VERSION ""

NS_ :

BS_:

BU_: BMS

VAL_TABLE_ Rolling_Counter_0x2A1 15 "Invalid";
VAL_TABLE_ ODS_Status 3 "Reserved" 2 "ODS disconnected" 1 "Seat Occupied" 0 "Seat Not Occupied";
VAL_TABLE_ EVCC_MHU_CharSchSetFeedBack 3 "invalid " 2 "No Schedule" 1 "Schedule Success" 0 "No action";
VAL_TABLE_ EVCC_ChargeGunSts 1 "Plug In" 0 "no Plug in";
VAL_TABLE_ EVCC_ChargeMode 2 "DC Mode " 1 "AC Mode " 0 "Default";
VAL_TABLE_ EVCC_CP_Sts 12 "F~" 11 "E~" 10 "D~" 9 "C~" 8 "B~" 7 "A~" 6 "F" 5 "E" 4 "D" 3 "C" 2 "B" 1 "A" 0 "No CP";
VAL_TABLE_ EVCC_PP_Value 7 "CC GND" 6 "1500" 5 "680" 4 "220" 3 "100" 2 "Connection" 1 "Half Connection " 0 "No Connection";
VAL_TABLE_ EVCC_Lock_Sts 4 "Error" 3 "Unlocking" 2 "Locked" 1 "Locking " 0 "Unlock";
VAL_TABLE_ Rolling_Counter_0x2AA 15 "Invalid";
VAL_TABLE_ EVCC_PLC_CommSts 2 "PLC communication Fail" 1 "PLC communication Success" 0 "No PLC communication";
VAL_TABLE_ EVCC_DC_ChargeProcess 10 "Charge Error" 9 "After Charge" 8 "Charge Stoping" 7 "Charging" 6 "Precharge waiting" 5 "Insulation Monitor From Charge Station" 4 "Information exchange" 3 "Charging authentication" 2 "TCP Connecting" 1 "PLC Linking" 0 "No Charge";
VAL_TABLE_ EVCC_BMS_InsulationMonReq 1 "Close" 0 "invalid";
VAL_TABLE_ Rolling_Counter_0x2AB 15 "Invalid";
VAL_TABLE_ EVCC_OBC_PowerReq 127 "Invalid";
VAL_TABLE_ EVCC_OBC_VoltageReq 8191 "Invalid";
VAL_TABLE_ EVCC_OBC_CurrentReq 1023 "Invalid";
VAL_TABLE_ EVCC_OBC_Control 1 "enable" 0 "disable";
VAL_TABLE_ EVCC_AC_ChargeSts 4 "Charge Err" 3 "Afer Charge" 2 "Charge Stoping" 1 "Charging " 0 "No charge";
VAL_TABLE_ Rolling_Counter_0x218 15 "Invalid";
VAL_TABLE_ BMS_DC_Charge_input 1 "Valid" 0 "invalid";
VAL_TABLE_ BMS_DC_Charge_Req 1 "Valid" 0 "invalid";
VAL_TABLE_ BMS_DC_ChargeRelay_Sts 4 "stuck open" 3 "stuck closed" 2 "closed" 1 "open" 0 "reserved";
VAL_TABLE_ Rolling_Counter_0x216 15 "Invalid";
VAL_TABLE_ BMS_RemainChargeTime 16383 "Invalid";
VAL_TABLE_ BMS_ChgVoltage_REQ 16383 "Invalid";
VAL_TABLE_ BMS_ChgCurrent_REQ 65535 "Invalid";
VAL_TABLE_ Rolling_Counter_0x126 15 "Invalid";
VAL_TABLE_ BMS_AllowChgCurrPeak 65535 "Invalid";
VAL_TABLE_ BMS_AllowChgCurr 65535 "Invalid";
VAL_TABLE_ Rolling_Counter_0x209 15 "Invalid";
VAL_TABLE_ BMS_MaxDischgPwr_ALW 4095 "Invalid";
VAL_TABLE_ BMS_MaxChgPwr_ALW 4095 "Invalid";
VAL_TABLE_ BMS_MaxDischgPwr_Peak 4095 "Invalid";
VAL_TABLE_ BMS_MaxChgPwr_Peak 4095 "Invalid";
VAL_TABLE_ Rolling_Counter_0x249 15 "Invalid";
VAL_TABLE_ Rolling_Counter_0x248 15 "Invalid";
VAL_TABLE_ BMS_FlowRate_Req 255 "Invalid";
VAL_TABLE_ BMS_CoolPwrDemand 4095 "Invalid";
VAL_TABLE_ BMS_VCU_ValveOnOff_Req 1 "open " 0 "close";
VAL_TABLE_ BMS_HeatPwrDemand 4095 "Invalid";
VAL_TABLE_ BMS_VCU_PTCOnOff_Req 1 "ON" 0 "OFF";
VAL_TABLE_ Rolling_Counter_0x206 15 "Invalid";
VAL_TABLE_ BMS_MaxMinDiffCellVol 8191 "Invalid value if diff > 500mV";
VAL_TABLE_ Rolling_Counter_0x332 15 "Invalid";
VAL_TABLE_ BMS_PackTemp_Infor 255 "Invalid";
VAL_TABLE_ Rolling_Counter_0x330 15 "Invalid";
VAL_TABLE_ BMS_ContactorAging 2 "Fault: counter reach 98%" 1 "Warning: counter reach 90%" 0 "Normal";
VAL_TABLE_ Rolling_Counter_0x176 15 "Invalid";
VAL_TABLE_ BMS_HVLinkVol_MEAS 65535 "Invalid";
VAL_TABLE_ BMS_HVPackVol_MEAS 65535 "Invalid";
VAL_TABLE_ Rolling_Counter_0x177 15 "Invalid";
VAL_TABLE_ BMS_HVBusVol_MEAS 65535 "Invalid";
VAL_TABLE_ BMS_HVFuseVol_MEAS 65535 "Invalid";
VAL_TABLE_ Rolling_Counter_0x174 15 "Invalid";
VAL_TABLE_ BMS_PackCur_MEAS 65535 "Invalid";
VAL_TABLE_ Rolling_Counter_0x215 15 "Invalid";
VAL_TABLE_ BMS_HWCrash_Sts 1 "Crash " 0 "No Crash";
VAL_TABLE_ BMS_HVIL_STS 2 "short to ground" 1 "Open & short to battery" 0 "Closed";
VAL_TABLE_ BMS_IGN_Sts 1 "ON " 0 "OFF";
VAL_TABLE_ BMS_Sys_STS 8 "Invalid" 7 "Failure, unable to operate" 6 "BCU Sleep mode" 5 "Successful Power Down" 4 "Power Down process" 3 "Successful Power Down of HV" 2 "Successful High Voltage Power Up" 1 "Self-check passes, can be high-voltage" 0 "Initialization of power on, self-checking";
VAL_TABLE_ BMS_HVOnOff_STS 3 "Fail to HV on " 2 "HV On " 1 "Precharge " 0 "HV Off";
VAL_TABLE_ BMS_Balance_STS 1 "active " 0 "Inactive";
VAL_TABLE_ BMS_BatBalance_ERR 1 "normal " 0 "Error";
VAL_TABLE_ BMS_ISU_Status 3 "Level3(<100 Ohms/V)" 2 "Level2(<200 Ohms/V)" 1 "Level1 <500 Ohms/V ~ >200 Ohms/V" 0 "Normal (> 500 Ohms/V)";
VAL_TABLE_ BMS_ERR_LEV 7 "Battery locked -Reserved" 6 "Fault, needs Shutdown and Wakeup" 5 "Emergency off condition" 4 "Delayed power down with FTTI" 3 "Power down without FTTI" 2 "Limp Home" 1 " Warning (any warning in system)" 0 "No error";
VAL_TABLE_ BMS_HV_Sts 4 "AC Charging" 3 "DC Charging" 2 "HV ON" 1 "Precharge" 0 "HV Off";
VAL_TABLE_ BMS_MHU_Auth_Sts 2 "failed " 1 "pass " 0 "init";
VAL_TABLE_ Rolling_Counter_0x214 15 "Invalid";
VAL_TABLE_ BMS_Display_SOC 1023 "Invalid";
VAL_TABLE_ Rolling_Counter_0x225 15 "Invalid";
VAL_TABLE_ CDM_bAcvCanComStblMon 1 "Error" 0 "No error";
VAL_TABLE_ FRMo_bErrHvbatStReqExtMon 1 "Error" 0 "No error";
VAL_TABLE_ FRMo_bErrChrgnAllwdExtMon 1 "Error" 0 "No error";
VAL_TABLE_ FRMo_bErrVehCrashStExtMon 1 "Error" 0 "No error";
VAL_TABLE_ CDM_bErrComctnLossCanMon 1 "Error" 0 "No error";
VAL_TABLE_ CTCMon_bErrCtctrSopcMon 1 "Error" 0 "No error";
VAL_TABLE_ CTCMon_bInvldCtctrHisdIFbMon 1 "Error" 0 "No error";
VAL_TABLE_ CTCMon_bInvldCtctrLosdUFbMon 1 "Error" 0 "No error";
VAL_TABLE_ CTM_bErrCellTDifMaxMon 1 "Error" 0 "No error";
VAL_TABLE_ CTM_bErrCellTMaxMon 1 "Error" 0 "No error";
VAL_TABLE_ CTM_bErrCellTMinMon 1 "Error" 0 "No error";
VAL_TABLE_ CTM_bErrThrwyPredMon 1 "Error" 0 "No error";
VAL_TABLE_ CUM_bErrCellUDifMaxMon 1 "Error" 0 "No error";
VAL_TABLE_ CUM_bErrCellUMaxMon 1 "Error" 0 "No error";
VAL_TABLE_ CUM_bErrCellUMinMon 1 "Error" 0 "No error";
VAL_TABLE_ CUM_bErrCellUProtnMaxNvMon 1 "Error" 0 "No error";
VAL_TABLE_ CUM_bErrCellUProtnMinNvMon 1 "Error" 0 "No error";
VAL_TABLE_ CUM_bErrPackUImplyMon 1 "Error" 0 "No error";
VAL_TABLE_ EHPMon_bRdyHvilMon 1 "Error" 0 "No error";
VAL_TABLE_ EHPMon_bErrWlddNegNvMon 1 "Error" 0 "No error";
VAL_TABLE_ EHPMon_bErrWlddPosNvMon 1 "Error" 0 "No error";
VAL_TABLE_ EHPMon_bErrWlddPrechNvMon 1 "Error" 0 "No error";
VAL_TABLE_ EHPMon_bErrHvilMon 1 "Error" 0 "No error";
VAL_TABLE_ EHPMon_bErrHvilShoMon 1 "Error" 0 "No error";
VAL_TABLE_ EHPMon_bErrPackIslnRNvMon 1 "Error" 0 "No error";
VAL_TABLE_ EHPMon_bErrVehCrashNvMon 1 "Error" 0 "No error";
VAL_TABLE_ EHPMon_bErrVehIslnRNvMon 1 "Error" 0 "No error";
VAL_TABLE_ FRMo_bErrMemStorgNvMon 1 "Error" 0 "No error";
VAL_TABLE_ L1IM_bErrClmp30MaxMonInp 1 "Error" 0 "No error";
VAL_TABLE_ L1IM_bErrClmp30MinMonInp 1 "Error" 0 "No error";
VAL_TABLE_ L1IM_bErrCtctrDtrtMonInp 1 "Error" 0 "No error";
VAL_TABLE_ L1IM_bErrUActImplyMonInp 1 "Error" 0 "No error";
VAL_TABLE_ MCCM_bAcvMdulCtlrStsMon 1 "Error" 0 "No error";
VAL_TABLE_ MCCM_bErrLntecSngFltMon 1 "Error" 0 "No error";
VAL_TABLE_ MCCM_bErrLntecLtntFltMon 1 "Error" 0 "No error";
VAL_TABLE_ MCCM_bErrMdulCellSnsrCfgMon 1 "Error" 0 "No error";
VAL_TABLE_ MCCM_bErrMdulCtlrComMon 1 "Error" 0 "No error";
VAL_TABLE_ MCCM_bErrSnsrTEltlMon 1 "Error" 0 "No error";
VAL_TABLE_ MCCM_bWarnSnsrTEltlMon 1 "Error" 0 "No error";
VAL_TABLE_ PCM_bRdySnsrIMon 1 "Error" 0 "No error";
VAL_TABLE_ PCM_bErrPackEFlowMaxLimMon 1 "Error" 0 "No error";
VAL_TABLE_ PCM_bErrPackIChDchaMaxLimMon 1 "Error" 0 "No error";
VAL_TABLE_ PCM_bErrSnsrIImplyMon 1 "Error" 0 "No error";
VAL_TABLE_ FRMo_bErrSnsrI1ExtMon 1 "Error" 0 "No error";
VAL_TABLE_ PCM_bInvldSnsrI1Mon 1 "Error" 0 "No error";
VAL_TABLE_ PCM_bInvldSnsrI2Mon 1 "Error" 0 "No error";
VAL_TABLE_ FRMo_bErrSopcLvl3Mon 1 "Error" 0 "No error";
VAL_TABLE_ BMS_FRMo_Reserved_1 1 "Error" 0 "No error";
VAL_TABLE_ BMS_FRMo_Reserved_2 1 "Error" 0 "No error";
VAL_TABLE_ BMS_FRMo_Reserved_3 1 "Error" 0 "No error";
VAL_TABLE_ BMS_FRMo_Reserved_4 1 "Error" 0 "No error";
VAL_TABLE_ BMS_FRMo_Reserved_5 1 "Error" 0 "No error";
VAL_TABLE_ Rolling_Counter_0x125 15 "Invalid";
VAL_TABLE_ BMS_AllowDischgCurr 65535 "Invalid";
VAL_TABLE_ BMS_AllowDischgCurrPeak 65535 "Invalid";
VAL_TABLE_ Rolling_Counter_0x375 15 "Invalid";
VAL_TABLE_ BMS_MainPosRelay_ERR 1 "normal " 0 "Error";
VAL_TABLE_ BMS_MainPosRelay_STS 4 "stuck open" 3 "stuck closed" 2 "closed" 1 "open" 0 "reserved";
VAL_TABLE_ BMS_PreChgRelay_ERR 1 "normal " 0 "error";
VAL_TABLE_ BMS_PreChgRelay_STS 4 "stuck open" 3 "stuck closed" 2 "closed" 1 "open" 0 "reserved";
VAL_TABLE_ BMS_TotalNegRelay_STS 4 "stuck open" 3 "stuck closed" 2 "closed" 1 "open" 0 "reserved";
VAL_TABLE_ BMS_TotalNegRelay_ERR 1 "normal " 0 "Error";
VAL_TABLE_ Rolling_Counter_0x205 15 "Invalid";
VAL_TABLE_ BMS_MaxCellVol 8191 "Invalid";
VAL_TABLE_ BMS_CellNumMaxCellVol 0 "Invalid";
VAL_TABLE_ BMS_MinCellVol 8191 "Invalid";
VAL_TABLE_ BMS_CellNumMinCellVol 0 "Invalid";
VAL_TABLE_ Rolling_Counter_0x245 15 "Invalid";
VAL_TABLE_ BMS_PackTemp 255 "Invalid";
VAL_TABLE_ BMS_MaxMinDiffCellTemp 255 "Diff Temp";
VAL_TABLE_ BMS_MaxCellTemp 255 "Invalid";
VAL_TABLE_ BMS_MinCellTemp 255 "Invalid";
VAL_TABLE_ BMS_ProbeNumMaxCellTemp 63 "Invalid" 62 "Error" 0 "Invalid";
VAL_TABLE_ BMS_ProbeNumMinCellTemp 63 "Invalid" 62 "Error" 0 "Invalid";
VAL_TABLE_ Rolling_Counter_0x305 15 "Invalid";
VAL_TABLE_ BMS_VCU_Insulation_Mon_Sts 1 "OFF" 0 "ON";
VAL_TABLE_ BMS_DischargeCurrent_Limited 1 "Limited" 0 "Not Limited ";
VAL_TABLE_ BMS_Warning_Flag_Reserved_07 1 "Warning" 0 "No warning";
VAL_TABLE_ BMS_Warning_Flag_Reserved_11 1 "Warning" 0 "No warning";
VAL_TABLE_ BMS_Warning_Flag_Reserved_10 1 "Warning" 0 "No warning";
VAL_TABLE_ BMS_Warning_Flag_Reserved_09 1 "Warning" 0 "No warning";
VAL_TABLE_ BMS_Warning_Flag_Reserved_13 1 "Warning" 0 "No warning";
VAL_TABLE_ BMS_Warning_Flag_Reserved_12 1 "Warning" 0 "No warning";
VAL_TABLE_ BMS_Warning_Flag_Reserved_06 1 "Warning" 0 "No warning";
VAL_TABLE_ BMS_Warning_Flag_Reserved_05 1 "Warning" 0 "No warning";
VAL_TABLE_ BMS_Warning_Flag_Reserved_04 1 "Warning" 0 "No warning";
VAL_TABLE_ BMS_MalfunctionSts 1 "Malfunction indicator lamp ON" 0 "Malfunction indicator lamp OFF";
VAL_TABLE_ BMS_LowBattery 2 "Extremely low level" 1 "Low level" 0 "No warning";
VAL_TABLE_ BMS_BatteryReplacement 1 "Warning" 0 "No warning";
VAL_TABLE_ BMS_PackTempSts 2 "Under Temperature Warning" 1 "Over Temperature Warning" 0 "No warning";
VAL_TABLE_ BMS_ThermalRunaway 1 "Warning" 0 "No warning";
VAL_TABLE_ Rolling_Counter_0x493 15 "Invalid";
VAL_TABLE_ BMS_QMMo_Reserved_9 1 "Error" 0 "No Error";
VAL_TABLE_ BMS_QMMo_Reserved_8 1 "Error" 0 "No Error";
VAL_TABLE_ BMS_QMMo_Reserved_7 1 "Error" 0 "No Error";
VAL_TABLE_ BMS_QMMo_Reserved_6 1 "Error" 0 "No Error";
VAL_TABLE_ BMS_QMMo_Reserved_5 1 "Error" 0 "No Error";
VAL_TABLE_ BMS_QMMo_Reserved_4 1 "Error" 0 "No Error";
VAL_TABLE_ BMS_QMMo_Reserved_3 1 "Error" 0 "No Error";
VAL_TABLE_ BMS_QMMo_Reserved_2 1 "Error" 0 "No Error";
VAL_TABLE_ BMS_QMMo_Reserved_11 1 "Error" 0 "No Error";
VAL_TABLE_ BMS_QMMo_Reserved_10 1 "Error" 0 "No Error";
VAL_TABLE_ BMS_QMMo_Reserved_1 1 "Error" 0 "No Error";
VAL_TABLE_ BMS_QMMo_Reserved_0 1 "Error" 0 "No Error";
VAL_TABLE_ Rolling_Counter_0x226 15 "Invalid";
VAL_TABLE_ Rolling_Counter_0x455 15 "Invalid";
VAL_TABLE_ BMS_PackInsu_ERR 2 "Lv2-Short to vbat and open line" 1 "Lv1 - Short to ground" 0 "Lv0-No Err";
VAL_TABLE_ BMS_CellVoltDiff_ERR 3 "Level3 Reserve" 2 "Level2 Serious alarm value" 1 "Level1 General alarm value" 0 "Level0 Normal";
VAL_TABLE_ BMS_PackOverCurr_ERR 2 "Serious Alarm value" 1 "General Alarm Value" 0 "Normal";
VAL_TABLE_ BMS_HVIL_Err 3 "Level3" 2 "Level2" 1 "Level1" 0 "Normal";
VAL_TABLE_ BMS_CellHighVol_ERR 3 "Level3 Reserve" 2 "Level2 Serious alarm value" 1 "Level1 General alarm value" 0 "Level0 Normal";
VAL_TABLE_ BMS_CellLowVol_ERR 3 "Level3 Reserve" 2 "Level2 Serious alarm value" 1 "Level1 General alarm value" 0 "Level0 Normal";
VAL_TABLE_ BMS_PackLowVol_ERR 3 "Level3 Reserve" 2 "Level2 Serious alarm value" 1 "Level1 General alarm value" 0 "Level0 Normal";
VAL_TABLE_ BMS_PackHighVol_ERR 3 "Level3 Reserve" 2 "Level2 Serious alarm value" 1 "Level1 General alarm value" 0 "Level0 Normal";
VAL_TABLE_ BMS_ProbeHighTemp_ERR 3 "Level3 Reserve" 2 "Level2 Serious alarm value" 1 "Level1 General alarm value" 0 "Level0 Normal";
VAL_TABLE_ BMS_ProbeTempDiff_ERR 3 "Level3 Reserve" 2 "Level2 Serious alarm value" 1 "Level1 General alarm value" 0 "Level0 Normal";
VAL_TABLE_ BMS_FuseStatus_ERR 1 "Fuse blow" 0 "Normal";
VAL_TABLE_ BMS_ProbeLowTemp_ERR 3 "Level3 Reserve" 2 "Level2 Serious alarm value" 1 "Level1 General alarm value" 0 "Level0 Normal";
VAL_TABLE_ softwore_version 1 "valid" 0 "Invalid";
VAL_TABLE_ Rolling_Counter_0x20B 15 "Invalid";
VAL_TABLE_ DCDC_Sys_STS 6 "(Off)" 5 "(Fault,Cannot work)" 3 "(Successful High Voltage Power Up)" 1 "(Self-Check passes, can be high-voltage)" 0 "(Initialization of power on, self-checking)";
VAL_TABLE_ DCDC_Voltage_Input 1023 "Invalid";
VAL_TABLE_ DCDC_Current_Input 255 "Invalid";
VAL_TABLE_ DCDC_Voltage_Output 1023 "Invalid";
VAL_TABLE_ DCDC_Current_Output 255 "Invalid";
VAL_TABLE_ DCDC_Output_STS 2 "fault" 1 "normal" 0 "stop";
VAL_TABLE_ DCDC_Temp 255 "Invalid";
VAL_TABLE_ Rolling_Counter_0x356 15 "Invalid";
VAL_TABLE_ OBC_WorkStatus 7 "CHG_LOCK_FAULT_STATE " 6 "CHG_RECV_FAULT_STATE " 5 " CHG_SLEEP_STATE" 4 "CHG_CHARG_OVER_STATE" 3 "CHG_CHARG_CV_STATE" 2 "CHG_CHARG_CC_STATE" 1 "CHG_STANDBY_STATE" 0 "Initial";
VAL_TABLE_ OBC_Sys_STS 3 "fault" 2 "warning" 1 "ok" 0 "init";
VAL_TABLE_ OBC_StartStatus 1 "Close Output" 0 "Start Output";
VAL_TABLE_ OBC_ChargeConnetState 3 "Invalid" 2 "connect" 1 "half connect" 0 "disconnect";
VAL_TABLE_ Rolling_Counter_0x366 15 "Invalid";
VAL_TABLE_ OBC_CP_State_reserved 5 "StataF" 4 "StataE" 3 "StataD" 2 "StataC" 1 "StataB" 0 "StataA";
VAL_TABLE_ OBC_Charge_air_temp 255 "Invalid";
VAL_TABLE_ OBC_Temp_Reserved 255 "Invalid";
VAL_TABLE_ Rolling_Counter_0x286 15 "Invalid";
VAL_TABLE_ OBC_OUT_DC_V 65535 "Invalid";
VAL_TABLE_ OBC_OUT_DC_I 16383 "Invalid";
VAL_TABLE_ OBC_DCCharge_line_V 65535 "Invalid";
VAL_TABLE_ Rolling_Counter_0x276 15 "Invalid";
VAL_TABLE_ OBC_Input_U 65535 "Invalid";
VAL_TABLE_ OBC_IN_Main_V_Reserved 65535 "Invalid";
VAL_TABLE_ OBC_IN_Main_I_Reserved 1023 "Invalid";
VAL_TABLE_ Rolling_Counter_0x296 15 "Invalid";
VAL_TABLE_ OBC_MaxOutputChgU 8191 "Invalid";
VAL_TABLE_ OBC_MaxOutputChgI 511 "Invalid";
VAL_TABLE_ OBC_MaxOutputPwr 127 "Invalid";
VAL_TABLE_ OBC_FailGrade_ERR 5 "Level5,Fatal fault" 4 "Level4,Serious fault" 3 "Level3,General fault" 2 "Level2,Minor fault" 1 "Level1,slight fault" 0 "No Fault";
VAL_TABLE_ OBC_ErrorFlag_Reserved 11 "FAULT_MUTEX " 10 "FAULT_OUT_OV " 9 "FAULT_OUT_UV" 8 "FAULT_PFC_UVPFC" 7 "FAULT_PFC_OVPFC" 6 "FAULT_IN_OV" 5 "FAULT_IN_UV" 4 "FAULT_COMM_OUT" 3 "FAULT_OUT_OC " 2 " FAULT_OTP_ALL " 1 "FAULT_OTP_RT " 0 "Initial";
VAL_TABLE_ OBC_Hardware_ERR 1 "Error" 0 "Normal";
VAL_TABLE_ OBC_OTemp_ERR 2 "Level2 - stop" 1 "Level1 - limit" 0 "Normal";
VAL_TABLE_ OBC_OCofOut_ERR_Reserved 1 "Error" 0 "Normal";
VAL_TABLE_ OBC_SlwChgSktOTemp_ERR_Reserved 1 "Error" 0 "Normal";
VAL_TABLE_ OBC_CANcomoverT_ERR 1 "Error" 0 "Normal";
VAL_TABLE_ OBC_UVofIn_ERR_Reserved 1 "Error" 0 "Normal";
VAL_TABLE_ OBC_OVofIn_ERR_Reserved 1 "Error" 0 "Normal";
VAL_TABLE_ OBC_OVofPFC_ERR_Reserved 1 "Error" 0 "Normal";
VAL_TABLE_ OBC_UVofPFC_ERR_Reserved 1 "Error" 0 "Normal";
VAL_TABLE_ OBC_UVofOut_ERR 1 "Error" 0 "Normal";
VAL_TABLE_ OBC_OVofOut_ERR 1 "Error" 0 "Normal";
VAL_TABLE_ EDS_bus_Volt_FWD 16383 "Invalid";
VAL_TABLE_ EDS_bus_Curr_FWD 65535 "Invalid";
VAL_TABLE_ EDS_HVIL_STS_FWD 3 "short to ground" 2 "short to battery" 1 "Open" 0 "Closed";
VAL_TABLE_ Rolling_Counter_0x1F8 15 "Invalid";
VAL_TABLE_ EDS_output_trq_FR 65535 "Invalid";
VAL_TABLE_ EDS_output_trqValid_FR 1 "valid" 0 "invalid";
VAL_TABLE_ EDS_Spd_FR 65535 "Invalid";
VAL_TABLE_ EDS_SpdValid_FR 1 "valid" 0 "invalid";
VAL_TABLE_ EDS_MotorDriveSts_FR 3 "Invaild" 2 "regen control" 1 "Drive control" 0 "Zero control";
VAL_TABLE_ EDS_Work_STS_FR 15 "invaild" 14 "power off" 13 "Failure" 12 "after run" 11 "shut down" 5 "HVReady" 4 "normal" 3 "precharge" 2 "standby" 1 "init" 0 "default";
VAL_TABLE_ EDS_powoff_req_FR 1 "(Request high voltage power down)" 0 "(No request)";
VAL_TABLE_ EDS_FailGrade_ERR_FWD 7 "Invaild" 6 "Invaild" 5 "Fifth Fault,Delayed power off" 4 "Forth Fault,ZeroTorque" 3 "Third Fault,Limp" 2 "Second Fault，Limited power" 1 "First-Level warning" 0 "No fault";
VAL_TABLE_ EDS_MotOverTempAlarm_FWD 1 "Error" 0 "Normal";
VAL_TABLE_ EDS_MotOverTempFault_FWD 1 "Error" 0 "Normal";
VAL_TABLE_ EDS_MotTempSenFault_FWD 1 "Error" 0 "Normal";
VAL_TABLE_ EDS_EDSOverTempUFault_FWD 1 "Error" 0 "Normal";
VAL_TABLE_ EDS_EDSOverTempVFault_FWD 1 "Error" 0 "Normal";
VAL_TABLE_ EDS_EDSOverTempWFault_FWD 1 "Error" 0 "Normal";
VAL_TABLE_ EDS_EDSOverTempAlarm_FWD 1 "Error" 0 "Normal";
VAL_TABLE_ EDS_TCoolantOvHi_FWD 1 "Error" 0 "Normal";
VAL_TABLE_ EDS_EDSTempCmpAlarm_FWD 1 "Error" 0 "Normal";
VAL_TABLE_ EDS_EDSPhaOvCurentHWFault_FWD 1 "Error" 0 "Normal";
VAL_TABLE_ EDS_EDSphaOffCalFault_FWD 1 "Error" 0 "Normal";
VAL_TABLE_ EDS_EDSOverIdcLnkAlarm_FWD 1 "Error" 0 "Normal";
VAL_TABLE_ EDS_EDSHVOverVoltageAlarm_FWD 1 "Error" 0 "Normal";
VAL_TABLE_ EDS_EDSHVOverVoltageFault_FWD 1 "Error" 0 "Normal";
VAL_TABLE_ EDS_EDSHVUnderVoltageAlarm_FWD 1 "Error" 0 "Normal";
VAL_TABLE_ EDS_EDSHVUnderVoltageFault_FWD 1 "Error" 0 "Normal";
VAL_TABLE_ EDS_RunToDischaErr_FWD 1 "Error" 0 "Normal";
VAL_TABLE_ EDS_12VOverVoltageAlarm_FWD 1 "Error" 0 "Normal";
VAL_TABLE_ EDS_12VUnderVoltageAlarm_FWD 1 "Error" 0 "Normal";
VAL_TABLE_ EDS_MotOverAlarm_FWD 1 "Error" 0 "Normal";
VAL_TABLE_ EDS_MotOverFault_FWD 1 "Error" 0 "Normal";
VAL_TABLE_ EDS_iDcLnkOvCLimFail_FWD 1 "Error" 0 "Normal";
VAL_TABLE_ EDS_MotBlockedFault_FWD 1 "Error" 0 "Normal";
VAL_TABLE_ EDS_RSLErr_FWD 1 "Error" 0 "Normal";
VAL_TABLE_ EDS_MotTrqLimFault_FWD 1 "Error" 0 "Normal";
VAL_TABLE_ EDS_ResolverOffsetAngle_FWD 1 "Error" 0 "Normal";
VAL_TABLE_ EDS_EDSDisChgFault_FWD 1 "Error" 0 "Normal";
VAL_TABLE_ EDS_IGBTFault_FWD 1 "Error" 0 "Normal";
VAL_TABLE_ EDS_CANBusoffFault_FWD 1 "Error" 0 "Normal";
VAL_TABLE_ EDS_TDrvBoardOvHiWarn_FWD 1 "Error" 0 "Normal";
VAL_TABLE_ EDS_TIGBTOvHiFault_FWD 1 "Error" 0 "Normal";
VAL_TABLE_ EDS_TIGBTOvHiWarn_FWD 1 "Error" 0 "Normal";
VAL_TABLE_ EDS_IOHWABSampFail_FWD 1 "Error" 0 "Normal";
VAL_TABLE_ EDS_EDSOpenFault_FWD 1 "Error" 0 "Normal";
VAL_TABLE_ EDS_MotorOpenFault_FWD 1 "Error" 0 "Normal";
VAL_TABLE_ EDS_EmacBlkdWarn_FWD 1 "Error" 0 "Normal";
VAL_TABLE_ EDS_VerMatchFailureErr_FWD 1 "Error" 0 "Normal";
VAL_TABLE_ EDS_DiashCirNoPsblErr_FWD 1 "Error" 0 "Normal";
VAL_TABLE_ EDS_OperOutdRngErr_FWD 1 "Error" 0 "Normal";
VAL_TABLE_ EDS_PhaseLossFaultErr_FWD 1 "Error" 0 "Normal";
VAL_TABLE_ EDS_CPLDFault_FWD 1 "Error" 0 "Normal";
VAL_TABLE_ EDS_CPLDFaultBaseSpd_FWD 1 "Error" 0 "Normal";
VAL_TABLE_ EDS_IOHWABNen33Fail_FWD 1 "Error" 0 "Normal";
VAL_TABLE_ EDS_HvMcuSlightFault_RWD 1 "Error" 0 "Normal";
VAL_TABLE_ EDS_HvMcuSevFault_FWD 1 "Error" 0 "Normal";
VAL_TABLE_ EDS_EDSPhaSampHWFault_FWD 1 "Error" 0 "Normal";
VAL_TABLE_ EDS_IsOvHiErr_FWD 1 "Error" 0 "Normal";
VAL_TABLE_ EDS_CanRollingCounterErr_FWD 1 "Error" 0 "Normal";
VAL_TABLE_ EDS_CanTimeoutErr_FWD 1 "Error" 0 "Normal";
VAL_TABLE_ EDS_CrashFault_FWD 1 "Error" 0 "Normal";
VAL_TABLE_ Rolling_Counter_0x219 15 "Invalid";
VAL_TABLE_ VCU_ChargeAllow 1 "Allow " 0 "Not allow";
VAL_TABLE_ Rolling_Counter_0x220 15 "Invalid";
VAL_TABLE_ VCU_BMS_PTCOnOff_Sts 1 "on " 0 "off";
VAL_TABLE_ VCU_BMS_ValveOnOff_Sts 1 "open " 0 "close";
VAL_TABLE_ VCU_BMS_PumpFB 3 "Reserve" 2 "Fault" 1 "ON" 0 "OFF";
VAL_TABLE_ VCU_Charge_Control 2 "Forbid" 1 "Allowed" 0 "Default";
VAL_TABLE_ VCU_AC_chargeSock_temp1 2047 "Invaild";
VAL_TABLE_ VCU_DC_chargeSock_temp1 2047 "Invaild";
VAL_TABLE_ VCU_DC_chargeSock_temp2 2047 "Invaild";
VAL_TABLE_ VCU_PTC_RelaySts 1 "close" 0 "open";
VAL_TABLE_ VCU_EACEnbReq 1 "Enable" 0 "Disable";
VAL_TABLE_ VCU_EACAllowedPower 1023 "Invalid";
VAL_TABLE_ VCU_EAC_CompSpdReq 16383 "Invaild";
VAL_TABLE_ VCU_RegenLevel_Feed 3 "invalid" 2 "High" 1 "Low" 0 "none";
VAL_TABLE_ VCU_RBCSts 1 "active" 0 "incative";
VAL_TABLE_ VCU_RDCSts 1 "active" 0 "incative";
VAL_TABLE_ VCU_Veh_ERR 1 "Error" 0 "Normal";
VAL_TABLE_ VCU_DrvSys_ERR 1 "Error" 0 "Normal";
VAL_TABLE_ VCU_PackSys_ERR 1 "Error" 0 "Normal";
VAL_TABLE_ VCU_TBOX_Veh_STS_Reserved 3 "Other" 2 "Off" 1 "Start" 0 "Invalid";
VAL_TABLE_ VCU_VehChg_STS 3 "Charge fault" 2 "Charging complete" 1 "Charging in progress" 0 "Charging not in progress";
VAL_TABLE_ VCU_BatterVoltage_Reserved 255 "Invalid";
VAL_TABLE_ VCU_BatteryVoltErr_Reserved 1 "warning" 0 "no warning";
VAL_TABLE_ VCU_MotorCoolingCircuitErr_Reserved 1 "Error" 0 "Normal";
VAL_TABLE_ VCU_PackCoolingCircuitErr_Reserved 1 "Error" 0 "Normal";
VAL_TABLE_ VCU_VehicleHVStatus 3 "Reserved" 2 "ReadyToDrive" 1 "HV On" 0 "Not ready";
VAL_TABLE_ VCU_InstantPowerConsump 1023 "Invalid";
VAL_TABLE_ VCU_AveragePowerConsump 1023 "Invalid";
VAL_TABLE_ VCU_BrakePedalSts 3 "Invalid" 2 "Reserved" 1 "pressed" 0 "Not pressed";
VAL_TABLE_ Rolling_Counter_0x3E0 15 "Invalid";
VAL_TABLE_ VCU_MHU_Ack_ChgSche_stt 0 "Disabled" 1 "Enabled" 2 "Reserved" 3 "Invalid";
VAL_TABLE_ VCU_MHU_GuestMode_sts 0 "OFF" 1 "ON" 2 "Reserved" 3 "Reserved";
VAL_TABLE_ VCU_ValetMode_sts 0 "Inactive" 1 "Active" 255 "Invalid";
VAL_TABLE_ VCU_CreepDisable_stt 0 "Enable" 1"Disable";
VAL_TABLE_ Rolling_Counter_0x199 15 "Invalid";
VAL_TABLE_ VCU_VehFailGrade_ERR 5 "Level5" 4 "Level4" 3 "Level3" 2 "Level2" 1 "Level1" 0 "Normal";
VAL_TABLE_ VCU_BMS_HVOnOff_REQ 1 "allow" 0 "forbid";
VAL_TABLE_ VCU_Vehicle_Mode 9 "Reserved " 8 "Emer Driving Mode " 7 "Reserved" 6 "Charging Mode " 5 "HV-Termination Mode " 4 "Driving Mode " 3 "HV-Activation Mode" 2 "Vehicle Reset Mode " 1 "StandBy IG OFF Mode " 0 "Reserved";
VAL_TABLE_ EAC_CompElecCurrV 0 "Valid" 1 "Invalid";
VAL_TABLE_ EAC_CompStat 0 "Normal Operation" 1 "Degraded Operation" 2 "Inoperative" 15 "Invalid";
VAL_TABLE_ EAC_CompElecPwrV 0 "Valid" 1 "Invalid";
VAL_TABLE_ EAC_CompSpdIncrReq 0 "False" 1 "True";
VAL_TABLE_ EAC_CompSpdV 0 "Valid" 1 "Invalid";
VAL_TABLE_ EAC_CompElecPwr 255 "Invaild";
VAL_TABLE_ EAC_CompSpd 16383 "Invaild";
VAL_TABLE_ EAC_CompElecCurr 255 "Invaild";
VAL_TABLE_ EAC_CompFltStat 0 "No Fault" 1 "Under Voltage" 2 "Over Voltage" 3 "Over Temperature" 4 "Input Control" 5 "Current Fault" 6 "Internal Fault" 8 "Motor slip protection" 9 "HVDC input voltage drop protection" 10 "Inside the controller 15V control power supply output undervoltage protection" 11 "Overcurrent frequency limitation and frequency reduction" 15 "Invalid";
VAL_TABLE_ Rolling_Counter_0x20C 15 "Invalid";
VAL_TABLE_ IPC_ODO 1048575 "Invalid";
VAL_TABLE_ IPC_TripA 65535 "Invalid";
VAL_TABLE_ IPC_AverageSpeedTripA 4095 "Invalid";
VAL_TABLE_ IPC_AverageConsumptionTripA 1023 "Invalid";
VAL_TABLE_ IPC_ParkBrakeSts 3 "Invalid" 2 "Reserved" 1 "Applied" 0 "Released";
VAL_TABLE_ IPC_VehSpd 32767 "Invalid";
VAL_TABLE_ IPC_Sec 63 "Invalid";
VAL_TABLE_ IPC_Min 63 "Invalid";
VAL_TABLE_ IPC_Hour 31 "Invalid";
VAL_TABLE_ IPC_Day 31 "Invalid";
VAL_TABLE_ IPC_Month 15 "Invalid";
VAL_TABLE_ IPC_Year 255 "Invalid";
VAL_TABLE_ IPC_SelfCheckStatus 1 "self-check finish" 0 "self-checking";
VAL_TABLE_ Rolling_Counter_0x432 15 "Invalid";
VAL_TABLE_ MHU_FOTA_State 0 "INIT" 1 "NORMAL" 2 "FOTA FLASHING" 3 "FOTA-SUSPENDED" 4 "FAIL-SAFE-ERROR" 5 "SHUTDOWN" 6 "REMOTE DIAGNOSTICS" 7 "Invalid";
VAL_TABLE_ Rolling_Counter_0x403 15 "Invalid";
VAL_TABLE_ MHU_SET_TCS_OnOff 0 "OFF (keep sending for 2 seconds)" 1 "ON (keep sending for 2 seconds)" 2 "No action" 3 "Invalid";
VAL_TABLE_ MHU_SET_DrivingModeSwitch 3 "sport mode (should be hold during 1 second)" 2 "normal mode (should be hold during 1 second)" 1 "eco mode (should be hold during 1 second)" 0 "no change request";
VAL_TABLE_ MHU_SET_RegenLevel 3 "No action" 2 "High" 1 "Low" 0 "none";
VAL_TABLE_ MHU_VCU_CreepDisable_stt 0 "No request" 1 "Creep Disable request" 2 "Reserved" 3 "Invalid";
VAL_TABLE_ MHU_HVACTurnON 0 "No request" 1 "ON" 2 "Reserved" 3 "Invalid";
VAL_TABLE_ MHU_ChargeScheduleSet 0 "Disabled" 1 "Enabled" 2 "No Action" 3 "Reserved";
VAL_TABLE_ MHU_ChargingRequest 0 "Reserved" 1 "Request scheduled start charging" 2 "Request stop" 3 "No effect";
VAL_TABLE_ MHU_ValetMode_Activation 0 "Inactive" 1 "Active" 254 "Reserved" 255 "Invalid";
VAL_TABLE_ CCU_TemperatureGearSts 63 "Invalid" 16 "level 8" 15 "level 7" 14 "level 6" 13 "level 5" 12 "level 4" 11 "level 3" 10 "level 2" 9 "level 1" 8 "level 8" 7 "level 7" 6 "level 6" 5 "level 5" 4 "level 4" 3 "level 3" 2 "level 2" 1 "level 1" 0 "Inactive";
VAL_TABLE_ CCU_BlowMode_Sts 7 "Invalid" 6 "Reserve" 4 "Foot and window" 3 "Foot" 2 "Foot and Face" 1 "Face" 0 "OFF";
VAL_TABLE_ CCU_Circulation_Sts 1 "Internal circulation" 0 "Outer circulation";
VAL_TABLE_ CCU_AC_Req 3 "Invalid" 2 "Reserved" 1 "Requset" 0 "No requset";
VAL_TABLE_ CCU_AC_Sts 1 "ON" 0 "OFF";
VAL_TABLE_ CCU_BlowerLevelSts 8 "level 8" 7 "level 7" 6 "level 6" 5 "level 5" 4 "level 4" 3 "level 3" 2 "level 2" 1 "level 1" 0 "OFF";
VAL_TABLE_ CCU_FrontDefrostSts 1 "On" 0 "Off";
VAL_TABLE_ CCU_PTC_Req 3 "Invalid" 2 "Reserved" 1 "Requset" 0 "No requset";
VAL_TABLE_ CCU_PTC_Temperature 1023 "Invaild";
VAL_TABLE_ CCU_CompSpdMEAS_Comp 8191 "Invalid";
VAL_TABLE_ CCU_PollutionSts 1 "ON" 0 "OFF";
VAL_TABLE_ CCU_ExternalTemperature 255 "Invaild";
VAL_TABLE_ CCU_evaporator_Temperature 31 "Invalid";
VAL_TABLE_ CCU_ExternalTemperatureFailSts 1 "invalid" 0 "valid";
VAL_TABLE_ Rolling_Counter_0x112 15 "Invalid";
VAL_TABLE_ STAT_Terminal 7 "Signal invalid" 6 "Reserved" 5 "Reserved" 4 "SW update OTA (Not used in VFe34)" 3 "Engine start (eMotor running)" 2 "ON (Driver Present)" 1 "ACC (Park)" 0 "OFF(Comfort Enable)";
VAL_TABLE_ STAT_CL30s_L_Reserved 3 "Signal invalid" 2 "Failure" 1 "ON" 0 "OFF";
VAL_TABLE_ Rolling_Counter_0x10a 15 "Invalid";
VAL_TABLE_ BCM_LVTop_up 1 "start Top up" 0 "stop Top up";
VAL_TABLE_ Rolling_Counter_0x85 15 "Invalid";
VAL_TABLE_ ACM_Crash_Sts 3 "Invalid Value" 2 "Invalid Value" 1 "Crash_Detected" 0 "No_Event";
VAL_TABLE_ ACM_Airbag_Deployment_Status 3 "Invalid Value" 2 "Invalid Value" 1 "Airbag_Deployment" 0 "No_Airbag_Deployment";
VAL_TABLE_ ACM_Crash_Intensity 7 "Invalid_Value" 6 "Invalid_Value" 5 "Invalid_Value" 4 "Invalid_Value" 3 "Crash_Intensity_3" 2 "Crash_Intensity_2" 1 "Crash_Intensity_1" 0 "No_Crash";
VAL_TABLE_ ACM_Front_Crash 3 "Invalid Value" 2 "Invalid Value" 1 "Front_Crash_Detected" 0 "No_Event";
VAL_TABLE_ ACM_DriverSide_Crash 3 "Invalid Value" 2 "Invalid Value" 1 "Driverside_Crash_Detected" 0 "No_Event";
VAL_TABLE_ ACM_PassSide_Crash 3 "Invalid Value" 2 "Invalid Value" 1 "PassSide_Crash_Detected" 0 "No_Event";
VAL_TABLE_ ACM_Rear_Crash 3 "Invalid Value" 2 "Invalid Value" 1 "Rear_Crash_Detected" 0 "No_Event";
VAL_TABLE_ ACM_Rollover_Crash 3 "Invalid Value" 2 "Invalid Value" 1 "Rollover_Crash_Detected" 0 "No_Event";
VAL_TABLE_ Rolling_Counter_0x342 15 "Invalid";
VAL_TABLE_ ABS_LRWhlSpdRaw 32767 "Invalid";
VAL_TABLE_ ABS_LRWhlSpdRawValid 1 "Valid" 0 "Invalid";
VAL_TABLE_ ABS_RRWhlSpdRaw 32767 "Invalid";
VAL_TABLE_ ABS_RRWhlSpdRawValid 1 "Valid" 0 "Invalid";
VAL_TABLE_ ABS_VehSpd 32767 "Invalid";
VAL_TABLE_ ABS_VehSpdValid 1 "Valid" 0 "Invalid";
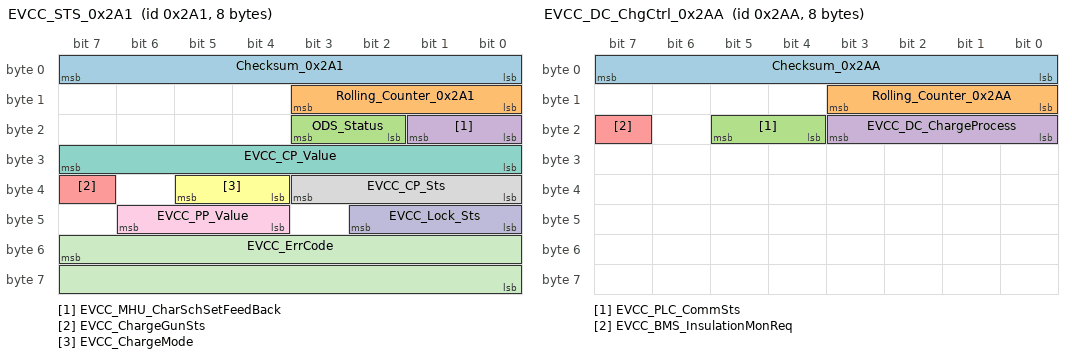
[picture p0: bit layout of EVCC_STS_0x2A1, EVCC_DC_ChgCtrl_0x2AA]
BO_ 673 EVCC_STS_0x2A1: 8 Vector__XXX
 SG_ Checksum_0x2A1 : 7|8@0+ (1,0) [0|255] "" BMS
 SG_ Rolling_Counter_0x2A1 : 11|4@0+ (1,0) [0|15] "" BMS
 SG_ ODS_Status : 19|2@0+ (1,0) [0|3] "" BMS
 SG_ EVCC_MHU_CharSchSetFeedBack : 17|2@0+ (1,0) [0|3] "" Vector__XXX
 SG_ EVCC_ChargeGunSts : 39|1@0+ (1,0) [0|1] "" BMS
 SG_ EVCC_ChargeMode : 37|2@0+ (1,0) [0|3] "" BMS
 SG_ EVCC_CP_Value : 31|8@0+ (1,0) [0|100] "%" BMS
 SG_ EVCC_CP_Sts : 35|4@0+ (1,0) [0|15] "" BMS
 SG_ EVCC_PP_Value : 46|3@0+ (1,0) [0|7] "" BMS
 SG_ EVCC_Lock_Sts : 42|3@0+ (1,0) [0|7] "" BMS
 SG_ EVCC_ErrCode : 55|16@0+ (1,0) [0|65535] "" BMS
BO_ 682 EVCC_DC_ChgCtrl_0x2AA: 8 Vector__XXX
 SG_ Checksum_0x2AA : 7|8@0+ (1,0) [0|255] "" BMS
 SG_ Rolling_Counter_0x2AA : 11|4@0+ (1,0) [0|15] "" BMS
 SG_ EVCC_PLC_CommSts : 21|2@0+ (1,0) [0|3] "" BMS
 SG_ EVCC_DC_ChargeProcess : 19|4@0+ (1,0) [0|15] "" BMS
 SG_ EVCC_BMS_InsulationMonReq : 23|1@0+ (1,0) [0|1] "" BMS
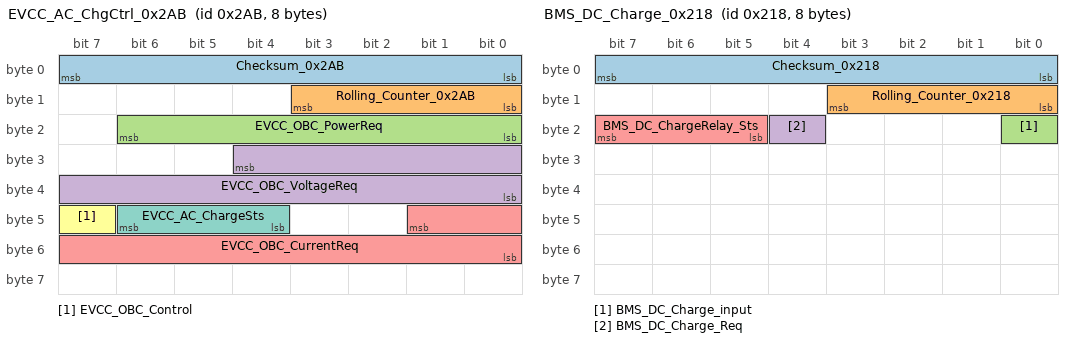
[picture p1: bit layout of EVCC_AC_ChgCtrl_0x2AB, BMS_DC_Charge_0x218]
BO_ 683 EVCC_AC_ChgCtrl_0x2AB: 8 Vector__XXX
 SG_ Checksum_0x2AB : 7|8@0+ (1,0) [0|255] "" BMS
 SG_ Rolling_Counter_0x2AB : 11|4@0+ (1,0) [0|15] "" BMS
 SG_ EVCC_OBC_PowerReq : 22|7@0+ (0.1,0) [0|10] "kW" Vector__XXX
 SG_ EVCC_OBC_VoltageReq : 28|13@0+ (0.1,0) [0|500] "V" Vector__XXX
 SG_ EVCC_OBC_CurrentReq : 41|10@0+ (0.1,0) [0|100] "A" Vector__XXX
 SG_ EVCC_OBC_Control : 47|1@0+ (1,0) [0|1] "" Vector__XXX
 SG_ EVCC_AC_ChargeSts : 46|3@0+ (1,0) [0|7] "" BMS
BO_ 536 BMS_DC_Charge_0x218: 8 BMS
 SG_ Checksum_0x218 : 7|8@0+ (1,0) [0|255] "" Vector__XXX
 SG_ Rolling_Counter_0x218 : 11|4@0+ (1,0) [0|15] "" Vector__XXX
 SG_ BMS_DC_Charge_input : 16|1@0+ (1,0) [0|1] "" Vector__XXX
 SG_ BMS_DC_Charge_Req : 20|1@0+ (1,0) [0|1] "" Vector__XXX
 SG_ BMS_DC_ChargeRelay_Sts : 23|3@0+ (1,0) [0|4] "" Vector__XXX
BO_ 534 BMS_ChgParamReq_0x216: 8 BMS
 SG_ Checksum_0x216 : 7|8@0+ (1,0) [0|255] "" Vector__XXX
 SG_ Rolling_Counter_0x216 : 11|4@0+ (1,0) [0|15] "" Vector__XXX
 SG_ BMS_RemainChargeTime : 21|14@0+ (1,0) [0|16383] "min" Vector__XXX
 SG_ BMS_ChgVoltage_REQ : 37|14@0+ (0.1,0) [0|800] "V" Vector__XXX
 SG_ BMS_ChgCurrent_REQ : 55|16@0+ (0.1,0) [0|1500] "A" Vector__XXX
BO_ 294 BMS_AllowChargeCurr_0x126: 8 BMS
 SG_ Checksum_0x126 : 7|8@0+ (1,0) [0|255] "" Vector__XXX
 SG_ Rolling_Counter_0x126 : 11|4@0+ (1,0) [0|15] "" Vector__XXX
 SG_ BMS_AllowChgCurrPeak : 39|16@0+ (0.1,0) [0|1500] "A" Vector__XXX
 SG_ BMS_AllowChgCurr : 23|16@0+ (0.1,0) [0|1500] "A" Vector__XXX
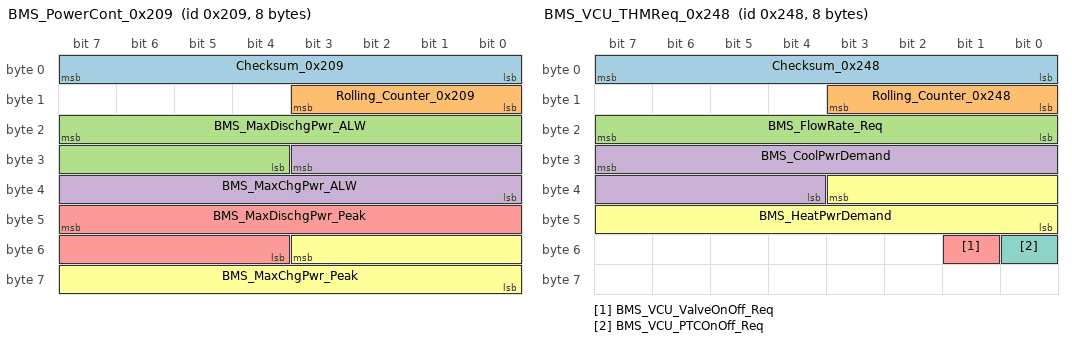
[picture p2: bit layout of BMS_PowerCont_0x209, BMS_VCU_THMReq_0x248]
BO_ 521 BMS_PowerCont_0x209: 8 BMS
 SG_ Checksum_0x209 : 7|8@0+ (1,0) [0|255] "" Vector__XXX
 SG_ Rolling_Counter_0x209 : 11|4@0+ (1,0) [0|15] "" Vector__XXX
 SG_ BMS_MaxDischgPwr_ALW : 23|12@0+ (0.1,0) [0|400] "KW" Vector__XXX
 SG_ BMS_MaxChgPwr_ALW : 27|12@0+ (0.1,0) [0|400] "KW" Vector__XXX
 SG_ BMS_MaxDischgPwr_Peak : 47|12@0+ (0.2,0) [0|800] "kw" Vector__XXX
 SG_ BMS_MaxChgPwr_Peak : 51|12@0+ (0.2,0) [0|800] "kw" Vector__XXX
BO_ 585 BMS_CoolntInletOutletTmp_0x249: 8 BMS
 SG_ Checksum_0x249 : 7|8@0+ (1,0) [0|255] "" Vector__XXX
 SG_ Rolling_Counter_0x249 : 11|4@0+ (1,0) [0|15] "" Vector__XXX
 SG_ BMS_CoolantOutletTemp : 31|8@0+ (1,-40) [-40|215] "degree centigrade" Vector__XXX
 SG_ BMS_CoolantInletTemp : 23|8@0+ (1,-40) [-40|215] "degree centigrade" Vector__XXX
BO_ 584 BMS_VCU_THMReq_0x248: 8 BMS
 SG_ Checksum_0x248 : 7|8@0+ (1,0) [0|255] "" Vector__XXX
 SG_ Rolling_Counter_0x248 : 11|4@0+ (1,0) [0|15] "" Vector__XXX
 SG_ BMS_FlowRate_Req : 23|8@0+ (1,0) [0|50] "L/min" Vector__XXX
 SG_ BMS_CoolPwrDemand : 31|12@0+ (0.1,0) [0|10] "KW" Vector__XXX
 SG_ BMS_VCU_ValveOnOff_Req : 49|1@0+ (1,0) [0|1] "" Vector__XXX
 SG_ BMS_HeatPwrDemand : 35|12@0+ (0.1,0) [0|10] "KW" Vector__XXX
 SG_ BMS_VCU_PTCOnOff_Req : 48|1@0+ (1,0) [0|1] "" Vector__XXX
BO_ 518 BMS_VolMeas2_0x206: 8 BMS
 SG_ Checksum_0x206 : 7|8@0+ (1,0) [0|255] "" Vector__XXX
 SG_ Rolling_Counter_0x206 : 11|4@0+ (1,0) [0|15] "" Vector__XXX
 SG_ BMS_MaxMinDiffCellVol : 20|13@0+ (0.001,0) [0|2] "V" Vector__XXX
BO_ 818 BMS_PackInfo_0x332: 8 BMS
 SG_ Checksum_0x332 : 7|8@0+ (1,0) [0|255] "" Vector__XXX
 SG_ Rolling_Counter_0x332 : 11|4@0+ (1,0) [0|15] "" Vector__XXX
 SG_ BMS_PackTemp_Infor : 39|8@0+ (1,-40) [-40|215] "℃" Vector__XXX
 SG_ BMS_PackCNom : 23|16@0+ (0.1,0) [0|6553.5] "kwh" Vector__XXX
BO_ 816 BMS_HistData_x330: 8 BMS
 SG_ Checksum_0x330 : 7|8@0+ (1,0) [0|255] "" Vector__XXX
 SG_ Rolling_Counter_0x330 : 11|4@0+ (1,0) [0|15] "" Vector__XXX
 SG_ BMS_ContactorAging : 23|8@0+ (1,0) [0|100] "%" Vector__XXX
BO_ 374 BMS_HVMeas1_0x176: 8 BMS
 SG_ Checksum_0x176 : 7|8@0+ (1,0) [0|255] "" Vector__XXX
 SG_ Rolling_Counter_0x176 : 11|4@0+ (1,0) [0|15] "" Vector__XXX
 SG_ BMS_HVLinkVol_MEAS : 39|16@0+ (0.1,0) [0|800] "V" Vector__XXX
 SG_ BMS_HVPackVol_MEAS : 23|16@0+ (0.1,0) [0|800] "V" Vector__XXX
BO_ 375 BMS_HVMeas2_0x177: 8 BMS
 SG_ Checksum_0x177 : 7|8@0+ (1,0) [0|255] "" Vector__XXX
 SG_ Rolling_Counter_0x177 : 11|4@0+ (1,0) [0|15] "" Vector__XXX
 SG_ BMS_HVBusVol_MEAS : 23|16@0+ (0.1,0) [0|800] "V" Vector__XXX
 SG_ BMS_HVFuseVol_MEAS : 39|16@0+ (0.1,0) [0|800] "V" Vector__XXX
BO_ 372 BMS_CurMeas_0x174: 8 BMS
 SG_ Checksum_0x174 : 7|8@0+ (1,0) [0|255] "" Vector__XXX
 SG_ Rolling_Counter_0x174 : 11|4@0+ (1,0) [0|15] "" Vector__XXX
 SG_ BMS_PackCur_MEAS : 23|16@0+ (0.1,-3276.8) [-3276.8|3276.7] "A" Vector__XXX
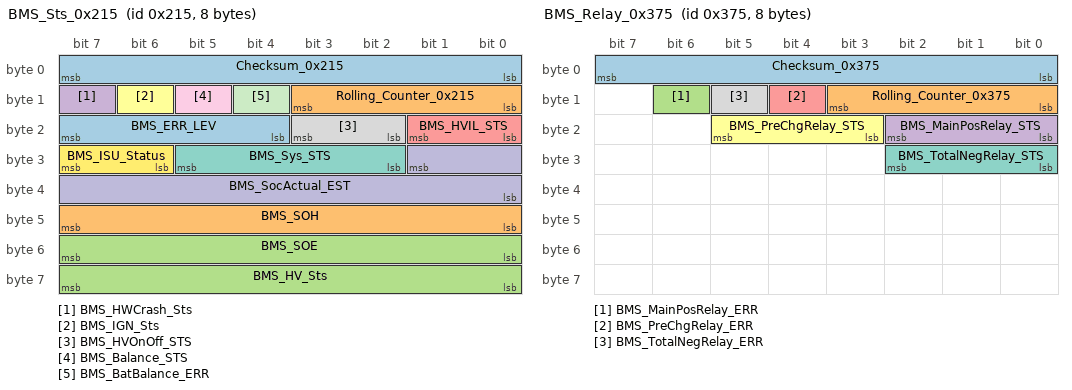
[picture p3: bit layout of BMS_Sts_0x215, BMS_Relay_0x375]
BO_ 533 BMS_Sts_0x215: 8 BMS
 SG_ Checksum_0x215 : 7|8@0+ (1,0) [0|255] "" Vector__XXX
 SG_ Rolling_Counter_0x215 : 11|4@0+ (1,0) [0|15] "" Vector__XXX
 SG_ BMS_SOE : 55|8@0+ (0.5,0) [0|100] "%" Vector__XXX
 SG_ BMS_HWCrash_Sts : 15|1@0+ (1,0) [0|1] "" Vector__XXX
 SG_ BMS_HVIL_STS : 17|2@0+ (1,0) [0|3] "" Vector__XXX
 SG_ BMS_IGN_Sts : 14|1@0+ (1,0) [0|1] "" Vector__XXX
 SG_ BMS_Sys_STS : 29|4@0+ (1,0) [0|15] "" Vector__XXX
 SG_ BMS_HVOnOff_STS : 19|2@0+ (1,0) [0|3] "" Vector__XXX
 SG_ BMS_Balance_STS : 13|1@0+ (1,0) [0|1] "" Vector__XXX
 SG_ BMS_SocActual_EST : 25|10@0+ (0.1,0) [0|100] "percent" Vector__XXX
 SG_ BMS_BatBalance_ERR : 12|1@0+ (1,0) [0|1] "" Vector__XXX
 SG_ BMS_ISU_Status : 31|2@0+ (1,0) [0|3] "" Vector__XXX
 SG_ BMS_ERR_LEV : 23|4@0+ (1,0) [0|15] "" Vector__XXX
 SG_ BMS_SOH : 47|8@0+ (0.5,0) [0|100] "%" Vector__XXX
 SG_ BMS_HV_Sts : 63|8@0+ (1,0) [0|255] "" Vector__XXX
BO_ 931 BMS_Sts2_0x3A3: 8 BMS
 SG_ BMS_MHU_Auth_Sts : 7|2@0+ (1,0) [0|3] "" Vector__XXX
BO_ 532 BMS_Sts3_0x214: 8 BMS
 SG_ Checksum_0x214 : 7|8@0+ (1,0) [0|255] "" Vector__XXX
 SG_ Rolling_Counter_0x214 : 11|4@0+ (1,0) [0|15] "" Vector__XXX
 SG_ BMS_Display_SOC : 21|10@0+ (0.1,0) [0|100] "" Vector__XXX
BO_ 549 BMS_FaultMgr_0x225: 8 BMS
 SG_ Checksum_0x225 : 7|8@0+ (1,0) [0|255] "" Vector__XXX
 SG_ Rolling_Counter_0x225 : 11|4@0+ (1,0) [0|15] "" Vector__XXX
 SG_ CDM_bAcvCanComStblMon : 12|1@0+ (1,0) [0|1] "" Vector__XXX
 SG_ FRMo_bErrHvbatStReqExtMon : 13|1@0+ (1,0) [0|1] "" Vector__XXX
 SG_ FRMo_bErrChrgnAllwdExtMon : 14|1@0+ (1,0) [0|1] "" Vector__XXX
 SG_ FRMo_bErrVehCrashStExtMon : 15|1@0+ (1,0) [0|1] "" Vector__XXX
 SG_ CDM_bErrComctnLossCanMon : 16|1@0+ (1,0) [0|1] "" Vector__XXX
 SG_ CTCMon_bErrCtctrSopcMon : 17|1@0+ (1,0) [0|1] "" Vector__XXX
 SG_ CTCMon_bInvldCtctrHisdIFbMon : 18|1@0+ (1,0) [0|1] "" Vector__XXX
 SG_ CTCMon_bInvldCtctrLosdUFbMon : 19|1@0+ (1,0) [0|1] "" Vector__XXX
 SG_ CTM_bErrCellTDifMaxMon : 20|1@0+ (1,0) [0|1] "" Vector__XXX
 SG_ CTM_bErrCellTMaxMon : 21|1@0+ (1,0) [0|1] "" Vector__XXX
 SG_ CTM_bErrCellTMinMon : 22|1@0+ (1,0) [0|1] "" Vector__XXX
 SG_ CTM_bErrThrwyPredMon : 23|1@0+ (1,0) [0|1] "" Vector__XXX
 SG_ CUM_bErrCellUDifMaxMon : 24|1@0+ (1,0) [0|1] "" Vector__XXX
 SG_ CUM_bErrCellUMaxMon : 25|1@0+ (1,0) [0|1] "" Vector__XXX
 SG_ CUM_bErrCellUMinMon : 26|1@0+ (1,0) [0|1] "" Vector__XXX
 SG_ CUM_bErrCellUProtnMaxNvMon : 27|1@0+ (1,0) [0|1] "" Vector__XXX
 SG_ CUM_bErrCellUProtnMinNvMon : 28|1@0+ (1,0) [0|1] "" Vector__XXX
 SG_ CUM_bErrPackUImplyMon : 29|1@0+ (1,0) [0|1] "" Vector__XXX
 SG_ EHPMon_bRdyHvilMon : 30|1@0+ (1,0) [0|1] "" Vector__XXX
 SG_ EHPMon_bErrWlddNegNvMon : 31|1@0+ (1,0) [0|1] "" Vector__XXX
 SG_ EHPMon_bErrWlddPosNvMon : 32|1@0+ (1,0) [0|1] "" Vector__XXX
 SG_ EHPMon_bErrWlddPrechNvMon : 33|1@0+ (1,0) [0|1] "" Vector__XXX
 SG_ EHPMon_bErrHvilMon : 34|1@0+ (1,0) [0|1] "" Vector__XXX
 SG_ EHPMon_bErrHvilShoMon : 35|1@0+ (1,0) [0|1] "" Vector__XXX
 SG_ EHPMon_bErrPackIslnRNvMon : 36|1@0+ (1,0) [0|1] "" Vector__XXX
 SG_ EHPMon_bErrVehCrashNvMon : 37|1@0+ (1,0) [0|1] "" Vector__XXX
 SG_ EHPMon_bErrVehIslnRNvMon : 38|1@0+ (1,0) [0|1] "" Vector__XXX
 SG_ FRMo_bErrMemStorgNvMon : 39|1@0+ (1,0) [0|1] "" Vector__XXX
 SG_ L1IM_bErrClmp30MaxMonInp : 40|1@0+ (1,0) [0|1] "" Vector__XXX
 SG_ L1IM_bErrClmp30MinMonInp : 41|1@0+ (1,0) [0|1] "" Vector__XXX
 SG_ L1IM_bErrCtctrDtrtMonInp : 42|1@0+ (1,0) [0|1] "" Vector__XXX
 SG_ L1IM_bErrUActImplyMonInp : 43|1@0+ (1,0) [0|1] "" Vector__XXX
 SG_ MCCM_bAcvMdulCtlrStsMon : 44|1@0+ (1,0) [0|1] "" Vector__XXX
 SG_ MCCM_bErrLntecSngFltMon : 45|1@0+ (1,0) [0|1] "" Vector__XXX
 SG_ MCCM_bErrLntecLtntFltMon : 46|1@0+ (1,0) [0|1] "" Vector__XXX
 SG_ MCCM_bErrMdulCellSnsrCfgMon : 47|1@0+ (1,0) [0|1] "" Vector__XXX
 SG_ MCCM_bErrMdulCtlrComMon : 48|1@0+ (1,0) [0|1] "" Vector__XXX
 SG_ MCCM_bErrSnsrTEltlMon : 49|1@0+ (1,0) [0|1] "" Vector__XXX
 SG_ MCCM_bWarnSnsrTEltlMon : 50|1@0+ (1,0) [0|1] "" Vector__XXX
 SG_ PCM_bRdySnsrIMon : 51|1@0+ (1,0) [0|1] "" Vector__XXX
 SG_ PCM_bErrPackEFlowMaxLimMon : 52|1@0+ (1,0) [0|1] "" Vector__XXX
 SG_ PCM_bErrPackIChDchaMaxLimMon : 53|1@0+ (1,0) [0|1] "" Vector__XXX
 SG_ PCM_bErrSnsrIImplyMon : 54|1@0+ (1,0) [0|1] "" Vector__XXX
 SG_ FRMo_bErrSnsrI1ExtMon : 55|1@0+ (1,0) [0|1] "" Vector__XXX
 SG_ PCM_bInvldSnsrI1Mon : 56|1@0+ (1,0) [0|1] "" Vector__XXX
 SG_ PCM_bInvldSnsrI2Mon : 57|1@0+ (1,0) [0|1] "" Vector__XXX
 SG_ FRMo_bErrSopcLvl3Mon : 58|1@0+ (1,0) [0|1] "" Vector__XXX
 SG_ BMS_FRMo_Reserved_1 : 59|1@0+ (1,0) [0|1] "" Vector__XXX
 SG_ BMS_FRMo_Reserved_2 : 60|1@0+ (1,0) [0|1] "" Vector__XXX
 SG_ BMS_FRMo_Reserved_3 : 61|1@0+ (1,0) [0|1] "" Vector__XXX
 SG_ BMS_FRMo_Reserved_4 : 62|1@0+ (1,0) [0|1] "" Vector__XXX
 SG_ BMS_FRMo_Reserved_5 : 63|1@0+ (1,0) [0|1] "" Vector__XXX
BO_ 293 BMS_Discharge_0x125: 8 BMS
 SG_ Checksum_0x125 : 7|8@0+ (1,0) [0|255] "" Vector__XXX
 SG_ Rolling_Counter_0x125 : 11|4@0+ (1,0) [0|15] "" Vector__XXX
 SG_ BMS_AllowDischgCurr : 23|16@0+ (0.1,0) [0|1500] "A" Vector__XXX
 SG_ BMS_AllowDischgCurrPeak : 39|16@0+ (0.1,0) [0|1500] "A" Vector__XXX
BO_ 885 BMS_Relay_0x375: 8 BMS
 SG_ Checksum_0x375 : 7|8@0+ (1,0) [0|255] "" Vector__XXX
 SG_ Rolling_Counter_0x375 : 11|4@0+ (1,0) [0|15] "" Vector__XXX
 SG_ BMS_MainPosRelay_ERR : 14|1@0+ (1,0) [0|1] "" Vector__XXX
 SG_ BMS_MainPosRelay_STS : 18|3@0+ (1,0) [0|7] "" Vector__XXX
 SG_ BMS_PreChgRelay_ERR : 12|1@0+ (1,0) [0|1] "" Vector__XXX
 SG_ BMS_PreChgRelay_STS : 21|3@0+ (1,0) [0|7] "" Vector__XXX
 SG_ BMS_TotalNegRelay_STS : 26|3@0+ (1,0) [0|7] "" Vector__XXX
 SG_ BMS_TotalNegRelay_ERR : 13|1@0+ (1,0) [0|1] "" Vector__XXX
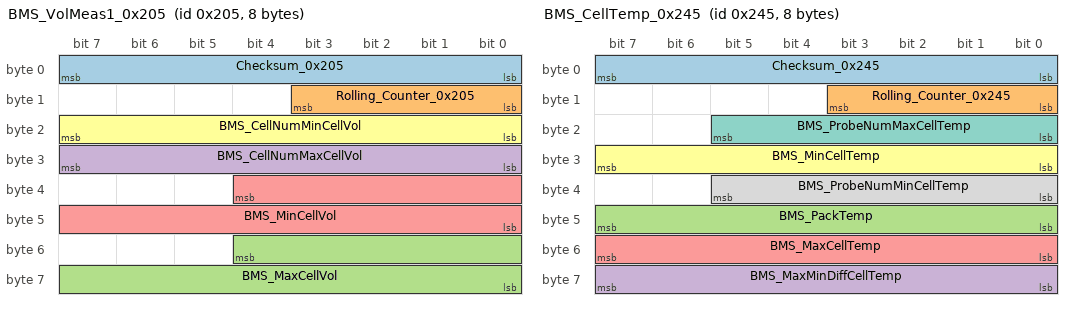
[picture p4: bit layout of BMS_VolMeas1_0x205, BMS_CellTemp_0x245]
BO_ 517 BMS_VolMeas1_0x205: 8 BMS
 SG_ Checksum_0x205 : 7|8@0+ (1,0) [0|255] "" Vector__XXX
 SG_ Rolling_Counter_0x205 : 11|4@0+ (1,0) [0|15] "" Vector__XXX
 SG_ BMS_MaxCellVol : 52|13@0+ (0.001,0) [0|6] "V" Vector__XXX
 SG_ BMS_CellNumMaxCellVol : 31|8@0+ (1,0) [0|255] "" Vector__XXX
 SG_ BMS_MinCellVol : 36|13@0+ (0.001,0) [0|6] "V" Vector__XXX
 SG_ BMS_CellNumMinCellVol : 23|8@0+ (1,0) [0|255] "" Vector__XXX
BO_ 581 BMS_CellTemp_0x245: 8 BMS
 SG_ Checksum_0x245 : 7|8@0+ (1,0) [0|255] "" Vector__XXX
 SG_ Rolling_Counter_0x245 : 11|4@0+ (1,0) [0|15] "" Vector__XXX
 SG_ BMS_PackTemp : 47|8@0+ (1,-40) [-40|215] "degree centigrade" Vector__XXX
 SG_ BMS_MaxMinDiffCellTemp : 63|8@0+ (1,-40) [-40|215] "degree centigrade" Vector__XXX
 SG_ BMS_MaxCellTemp : 55|8@0+ (1,-40) [-40|215] "degree centigrade" Vector__XXX
 SG_ BMS_MinCellTemp : 31|8@0+ (1,-40) [-40|215] "degree centigrade" Vector__XXX
 SG_ BMS_ProbeNumMaxCellTemp : 21|6@0+ (1,0) [0|63] "" Vector__XXX
 SG_ BMS_ProbeNumMinCellTemp : 37|6@0+ (1,0) [0|63] "" Vector__XXX
BO_ 773 BMS_Insulation_0x305: 8 BMS
 SG_ Checksum_0x305 : 7|8@0+ (1,0) [0|255] "" Vector__XXX
 SG_ Rolling_Counter_0x305 : 11|4@0+ (1,0) [0|15] "" Vector__XXX
 SG_ BMS_VCU_Insulation_Mon_Sts : 15|1@0+ (1,0) [0|1] "" Vector__XXX
 SG_ BMS_PackInsuRes : 23|16@0+ (1,0) [0|60000] "kOhm" Vector__XXX
BO_ 1171 BMS_WarnMsg_0x493: 8 BMS
 SG_ BMS_DischargeCurrent_Limited : 16|1@0+ (1,0) [0|1] "" Vector__XXX
 SG_ BMS_Warning_Flag_Reserved_07 : 17|1@0+ (1,0) [0|1] "" Vector__XXX
 SG_ BMS_Warning_Flag_Reserved_11 : 47|8@0+ (1,0) [0|255] "" Vector__XXX
 SG_ BMS_Warning_Flag_Reserved_10 : 39|8@0+ (1,0) [0|255] "" Vector__XXX
 SG_ BMS_Warning_Flag_Reserved_09 : 31|8@0+ (1,0) [0|255] "" Vector__XXX
 SG_ BMS_Warning_Flag_Reserved_13 : 63|8@0+ (1,0) [0|255] "" Vector__XXX
 SG_ BMS_Warning_Flag_Reserved_12 : 55|8@0+ (1,0) [0|255] "" Vector__XXX
 SG_ BMS_Warning_Flag_Reserved_06 : 18|1@0+ (1,0) [0|1] "" Vector__XXX
 SG_ BMS_Warning_Flag_Reserved_05 : 19|1@0+ (1,0) [0|1] "" Vector__XXX
 SG_ BMS_Warning_Flag_Reserved_04 : 20|1@0+ (1,0) [0|1] "" Vector__XXX
 SG_ BMS_MalfunctionSts : 21|1@0+ (1,0) [0|1] "" Vector__XXX
 SG_ BMS_LowBattery : 23|2@0+ (1,0) [0|3] "" Vector__XXX
 SG_ BMS_BatteryReplacement : 15|1@0+ (1,0) [0|1] "" Vector__XXX
 SG_ BMS_PackTempSts : 13|2@0+ (1,0) [0|3] "" Vector__XXX
 SG_ BMS_ThermalRunaway : 14|1@0+ (1,0) [0|1] "" Vector__XXX
 SG_ Rolling_Counter_0x493 : 11|4@0+ (1,0) [0|15] "" Vector__XXX
 SG_ Checksum_0x493 : 7|8@0+ (1,0) [0|255] "" Vector__XXX
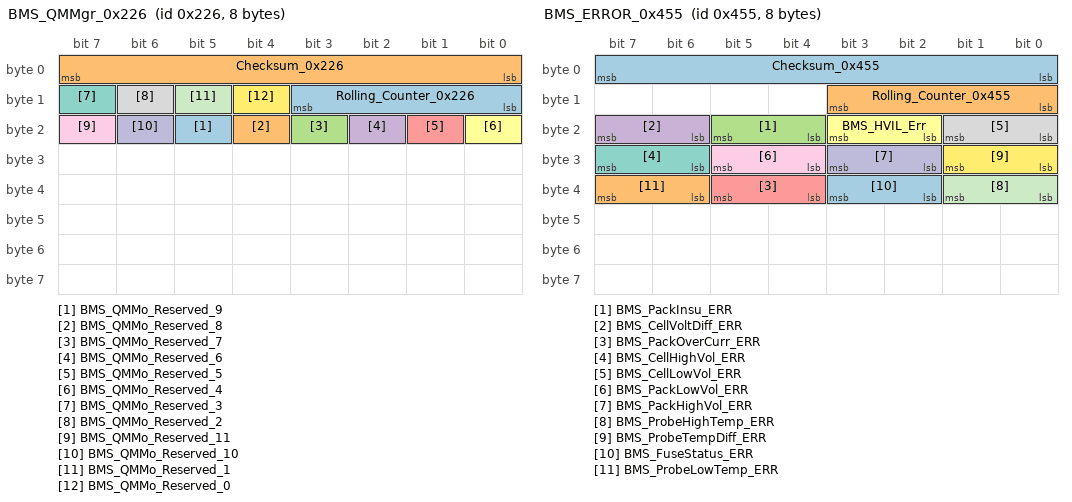
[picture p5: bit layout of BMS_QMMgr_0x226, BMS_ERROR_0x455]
BO_ 550 BMS_QMMgr_0x226: 8 BMS
 SG_ BMS_QMMo_Reserved_9 : 21|1@0+ (1,0) [0|1] "" Vector__XXX
 SG_ BMS_QMMo_Reserved_8 : 20|1@0+ (1,0) [0|1] "" Vector__XXX
 SG_ BMS_QMMo_Reserved_7 : 19|1@0+ (1,0) [0|1] "" Vector__XXX
 SG_ BMS_QMMo_Reserved_6 : 18|1@0+ (1,0) [0|1] "" Vector__XXX
 SG_ BMS_QMMo_Reserved_5 : 17|1@0+ (1,0) [0|1] "" Vector__XXX
 SG_ BMS_QMMo_Reserved_4 : 16|1@0+ (1,0) [0|1] "" Vector__XXX
 SG_ BMS_QMMo_Reserved_3 : 15|1@0+ (1,0) [0|1] "" Vector__XXX
 SG_ BMS_QMMo_Reserved_2 : 14|1@0+ (1,0) [0|1] "" Vector__XXX
 SG_ BMS_QMMo_Reserved_11 : 23|1@0+ (1,0) [0|1] "" Vector__XXX
 SG_ BMS_QMMo_Reserved_10 : 22|1@0+ (1,0) [0|1] "" Vector__XXX
 SG_ BMS_QMMo_Reserved_1 : 13|1@0+ (1,0) [0|1] "" Vector__XXX
 SG_ BMS_QMMo_Reserved_0 : 12|1@0+ (1,0) [0|1] "" Vector__XXX
 SG_ Rolling_Counter_0x226 : 11|4@0+ (1,0) [0|15] "" Vector__XXX
 SG_ Checksum_0x226 : 7|8@0+ (1,0) [0|255] "" Vector__XXX
BO_ 1109 BMS_ERROR_0x455: 8 BMS
 SG_ Checksum_0x455 : 7|8@0+ (1,0) [0|255] "" Vector__XXX
 SG_ Rolling_Counter_0x455 : 11|4@0+ (1,0) [0|15] "" Vector__XXX
 SG_ BMS_PackInsu_ERR : 21|2@0+ (1,0) [0|3] "" Vector__XXX
 SG_ BMS_CellVoltDiff_ERR : 23|2@0+ (1,0) [0|3] "" Vector__XXX
 SG_ BMS_PackOverCurr_ERR : 37|2@0+ (1,0) [0|3] "" Vector__XXX
 SG_ BMS_HVIL_Err : 19|2@0+ (1,0) [0|3] "" Vector__XXX
 SG_ BMS_CellHighVol_ERR : 31|2@0+ (1,0) [0|3] "" Vector__XXX
 SG_ BMS_CellLowVol_ERR : 17|2@0+ (1,0) [0|3] "" Vector__XXX
 SG_ BMS_PackLowVol_ERR : 29|2@0+ (1,0) [0|3] "" Vector__XXX
 SG_ BMS_PackHighVol_ERR : 27|2@0+ (1,0) [0|3] "" Vector__XXX
 SG_ BMS_ProbeHighTemp_ERR : 33|2@0+ (1,0) [0|3] "" Vector__XXX
 SG_ BMS_ProbeTempDiff_ERR : 25|2@0+ (1,0) [0|3] "" Vector__XXX
 SG_ BMS_FuseStatus_ERR : 35|2@0+ (1,0) [0|1] "" Vector__XXX
 SG_ BMS_ProbeLowTemp_ERR : 39|2@0+ (1,0) [0|3] "" Vector__XXX
BO_ 1504 Test1_BMS_CellVoltage_0x5E0: 8 BMS
 SG_ BMS_Voltage_FrameNumber : 7|8@0+ (1,0) [0|255] "" Vector__XXX
 SG_ BMS_Voltage_Value1 : 15|16@0+ (1,0) [0|5000] "" Vector__XXX
 SG_ BMS_Voltage_Value2 : 31|16@0+ (1,0) [0|5000] "" Vector__XXX
 SG_ BMS_Voltage_Value3 : 47|16@0+ (1,0) [0|5000] "" Vector__XXX
 SG_ softwore_version : 63|8@0+ (1,0) [0|255] "" Vector__XXX
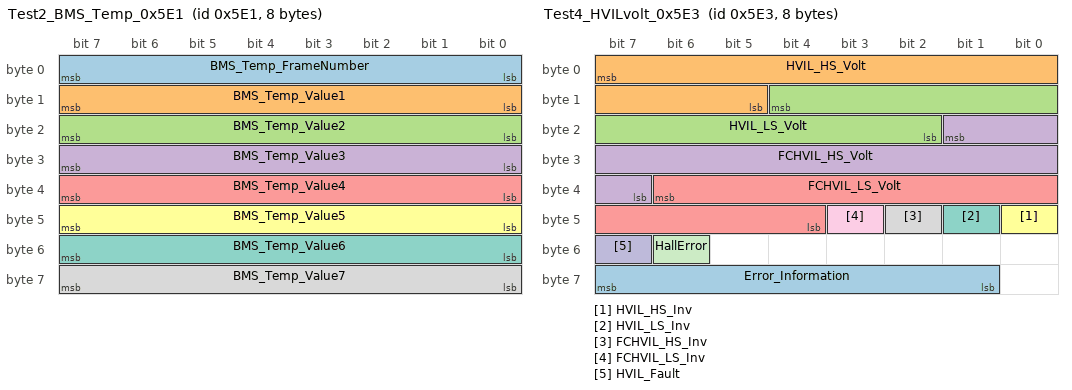
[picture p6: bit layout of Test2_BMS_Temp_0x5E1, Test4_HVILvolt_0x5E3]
BO_ 1505 Test2_BMS_Temp_0x5E1: 8 BMS
 SG_ BMS_Temp_FrameNumber : 7|8@0+ (1,0) [1|255] "" Vector__XXX
 SG_ BMS_Temp_Value1 : 15|8@0+ (1,-40) [-40|215] "°C" Vector__XXX
 SG_ BMS_Temp_Value2 : 23|8@0+ (1,-40) [-40|215] "°C" Vector__XXX
 SG_ BMS_Temp_Value3 : 31|8@0+ (1,-40) [-40|215] "°C" Vector__XXX
 SG_ BMS_Temp_Value4 : 39|8@0+ (1,-40) [-40|215] "°C" Vector__XXX
 SG_ BMS_Temp_Value5 : 47|8@0+ (1,-40) [-40|215] "°C" Vector__XXX
 SG_ BMS_Temp_Value6 : 55|8@0+ (1,-40) [-40|215] "°C" Vector__XXX
 SG_ BMS_Temp_Value7 : 63|8@0+ (1,-40) [-40|215] "°C" Vector__XXX
BO_ 1506 Test3_BMS_DTC_0x5E2: 8 BMS
 SG_ BMS_Test_Runaway : 7|16@0+ (1,0) [0|255] "" Vector__XXX
 SG_ BMS_Test_shunt_Temp : 23|16@0+ (1,-40) [-40|65535] "°C" Vector__XXX
 SG_ BMS_Test_V4_Volt : 39|16@0+ (1,0) [0|65535] "V" Vector__XXX
 SG_ BMS_Test_L2ErrNum : 55|16@0+ (1,0) [0|65535] "" Vector__XXX
BO_ 1507 Test4_HVILvolt_0x5E3: 8 BMS
 SG_ Error_Information : 63|7@0+ (1,0) [0|127] "" Vector__XXX
 SG_ HVIL_HS_Volt : 7|11@0+ (0.01,0) [0|20] "V" Vector__XXX
 SG_ HVIL_LS_Volt : 12|11@0+ (0.01,0) [0|20] "V" Vector__XXX
 SG_ FCHVIL_HS_Volt : 17|11@0+ (0.01,0) [0|20] "V" Vector__XXX
 SG_ FCHVIL_LS_Volt : 38|11@0+ (0.01,0) [0|20] "V" Vector__XXX
 SG_ HVIL_HS_Inv : 40|1@0+ (1,0) [0|0] "" Vector__XXX
 SG_ HVIL_LS_Inv : 41|1@0+ (1,0) [0|0] "" Vector__XXX
 SG_ FCHVIL_HS_Inv : 42|1@0+ (1,0) [0|0] "" Vector__XXX
 SG_ FCHVIL_LS_Inv : 43|1@0+ (1,0) [0|0] "" Vector__XXX
 SG_ HVIL_Fault : 55|1@0+ (1,0) [0|0] "" Vector__XXX
 SG_ HallError : 54|1@0+ (1,0) [0|0] "" Vector__XXX
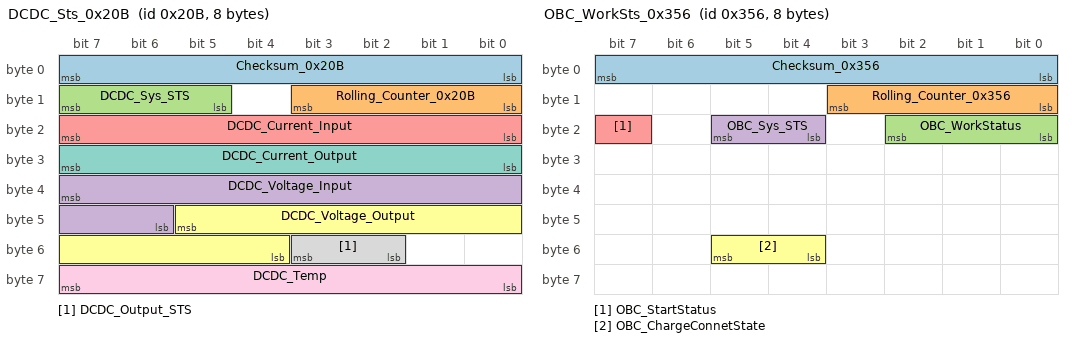
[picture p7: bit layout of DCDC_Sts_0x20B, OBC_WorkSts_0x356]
BO_ 523 DCDC_Sts_0x20B: 8 Vector__XXX
 SG_ Checksum_0x20B : 7|8@0+ (1,0) [0|255] "" BMS
 SG_ Rolling_Counter_0x20B : 11|4@0+ (1,0) [0|15] "" BMS
 SG_ DCDC_Sys_STS : 15|3@0+ (1,0) [0|7] "" BMS
 SG_ DCDC_Voltage_Input : 39|10@0+ (1,0) [0|1000] "V" BMS
 SG_ DCDC_Current_Input : 23|8@0+ (0.1,0) [0|25.5] "A" BMS
 SG_ DCDC_Voltage_Output : 45|10@0+ (1,0) [0|1000] "V" BMS
 SG_ DCDC_Current_Output : 31|8@0+ (1,0) [0|255] "A" BMS
 SG_ DCDC_Output_STS : 51|2@0+ (1,0) [0|3] "" BMS
 SG_ DCDC_Temp : 63|8@0+ (1,-40) [-40|215] "Centigrade" BMS
BO_ 854 OBC_WorkSts_0x356: 8 Vector__XXX
 SG_ Checksum_0x356 : 7|8@0+ (1,0) [0|255] "" BMS
 SG_ Rolling_Counter_0x356 : 11|4@0+ (1,0) [0|15] "" BMS
 SG_ OBC_WorkStatus : 18|3@0+ (1,0) [0|7] "" BMS
 SG_ OBC_Sys_STS : 21|2@0+ (1,0) [0|3] "" BMS
 SG_ OBC_StartStatus : 23|1@0+ (1,0) [0|1] "" BMS
 SG_ OBC_ChargeConnetState : 53|2@0+ (1,0) [0|3] "" BMS
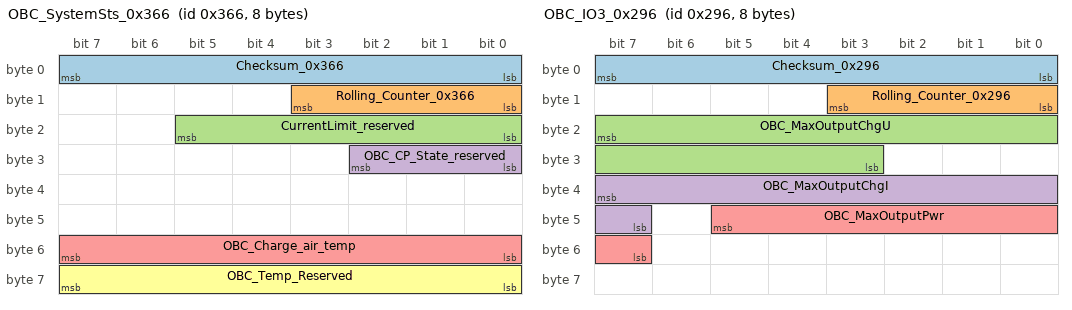
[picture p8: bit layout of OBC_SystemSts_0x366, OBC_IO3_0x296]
BO_ 870 OBC_SystemSts_0x366: 8 Vector__XXX
 SG_ Checksum_0x366 : 7|8@0+ (1,0) [0|255] "" BMS
 SG_ Rolling_Counter_0x366 : 11|4@0+ (1,0) [0|15] "" BMS
 SG_ CurrentLimit_reserved : 21|6@0+ (1,0) [0|63] "A" BMS
 SG_ OBC_CP_State_reserved : 26|3@0+ (1,0) [0|7] "" BMS
 SG_ OBC_Charge_air_temp : 55|8@0+ (1,-40) [-40|215] "degree" BMS
 SG_ OBC_Temp_Reserved : 63|8@0+ (1,-40) [-40|215] "degree" BMS
BO_ 646 OBC_IO1_0x286: 8 Vector__XXX
 SG_ Checksum_0x286 : 7|8@0+ (1,0) [0|255] "" BMS
 SG_ Rolling_Counter_0x286 : 11|4@0+ (1,0) [0|15] "" BMS
 SG_ OBC_OUT_DC_V : 23|16@0+ (0.1,0) [0|6553.5] "V" BMS
 SG_ OBC_OUT_DC_I : 39|14@0+ (0.1,0) [0|1000] "A" BMS
 SG_ OBC_DCCharge_line_V : 55|16@0+ (0.1,0) [0|6553.5] "V" BMS
BO_ 630 OBC_IO2_0x276: 8 Vector__XXX
 SG_ Checksum_0x276 : 7|8@0+ (1,0) [0|255] "" BMS
 SG_ Rolling_Counter_0x276 : 11|4@0+ (1,0) [0|15] "" BMS
 SG_ OBC_Input_U : 39|16@0+ (0.1,0) [0|6553.5] "V" BMS
 SG_ OBC_IN_Main_V_Reserved : 23|16@0+ (0.1,0) [0|6553.5] "V" BMS
 SG_ OBC_IN_Main_I_Reserved : 55|10@0+ (0.1,0) [0|100] "A" BMS
BO_ 662 OBC_IO3_0x296: 8 Vector__XXX
 SG_ Checksum_0x296 : 7|8@0+ (1,0) [0|255] "" BMS
 SG_ Rolling_Counter_0x296 : 11|4@0+ (1,0) [0|15] "" BMS
 SG_ OBC_MaxOutputChgU : 23|13@0+ (0.1,0) [0|500] "V" BMS
 SG_ OBC_MaxOutputChgI : 39|9@0+ (0.1,0) [0|40] "A" BMS
 SG_ OBC_MaxOutputPwr : 45|7@0+ (0.1,0) [0|10] "kW" BMS
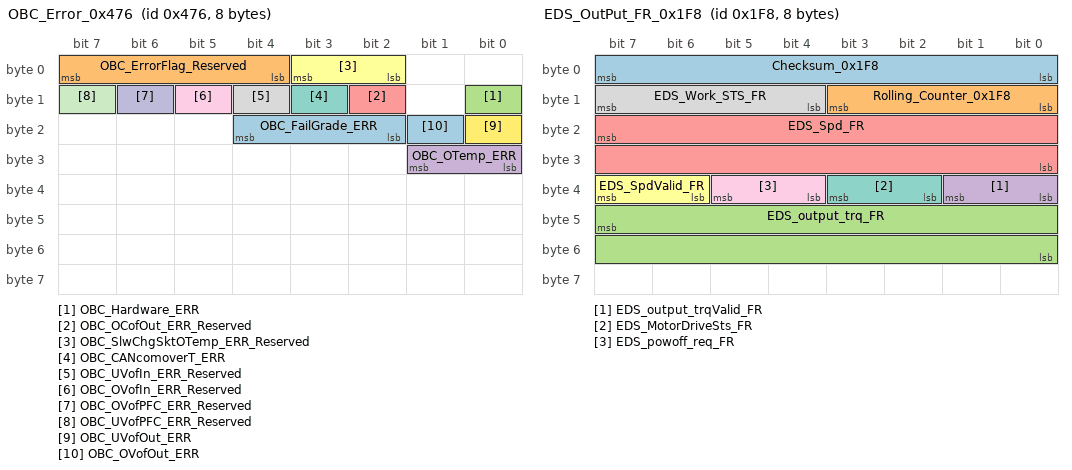
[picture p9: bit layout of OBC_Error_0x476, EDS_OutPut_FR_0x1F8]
BO_ 1142 OBC_Error_0x476: 8 Vector__XXX
 SG_ OBC_FailGrade_ERR : 20|3@0+ (1,0) [0|5] "" BMS
 SG_ OBC_ErrorFlag_Reserved : 7|4@0+ (1,0) [0|16] "" BMS
 SG_ OBC_Hardware_ERR : 8|1@0+ (1,0) [0|1] "" BMS
 SG_ OBC_OTemp_ERR : 25|2@0+ (1,0) [0|3] "" BMS
 SG_ OBC_OCofOut_ERR_Reserved : 10|1@0+ (1,0) [0|1] "" BMS
 SG_ OBC_SlwChgSktOTemp_ERR_Reserved : 3|2@0+ (1,0) [0|2] "" BMS
 SG_ OBC_CANcomoverT_ERR : 11|1@0+ (1,0) [0|1] "" BMS
 SG_ OBC_UVofIn_ERR_Reserved : 12|1@0+ (1,0) [0|1] "" BMS
 SG_ OBC_OVofIn_ERR_Reserved : 13|1@0+ (1,0) [0|1] "" BMS
 SG_ OBC_OVofPFC_ERR_Reserved : 14|1@0+ (1,0) [0|1] "" BMS
 SG_ OBC_UVofPFC_ERR_Reserved : 15|1@0+ (1,0) [0|1] "" BMS
 SG_ OBC_UVofOut_ERR : 16|1@0+ (1,0) [0|1] "" BMS
 SG_ OBC_OVofOut_ERR : 17|1@0+ (1,0) [0|1] "" BMS
BO_ 840 EDS_Sts_FR_0x348: 8 Vector__XXX
 SG_ EDS_bus_Volt_FWD : 7|14@0+ (0.1,0) [0|1000] "V" BMS
 SG_ EDS_bus_Curr_FWD : 23|16@0+ (0.1,-1000) [-1000|1000] "A" BMS
 SG_ EDS_MtrNumb_FWD : 39|8@0+ (1,0) [0|255] "" BMS
 SG_ EDS_DriveMtrNmb_FWD : 47|8@0+ (1,0) [0|255] "" BMS
 SG_ EDS_HVIL_STS_FWD : 9|2@0+ (1,0) [0|3] "" BMS
BO_ 504 EDS_OutPut_FR_0x1F8: 8 Vector__XXX
 SG_ Checksum_0x1F8 : 7|8@0+ (1,0) [0|255] "" BMS
 SG_ Rolling_Counter_0x1F8 : 11|4@0+ (1,0) [0|15] "" BMS
 SG_ EDS_output_trq_FR : 47|16@0+ (1,-2000) [-2000|2000] "Nm" BMS
 SG_ EDS_output_trqValid_FR : 33|2@0+ (1,0) [0|1] "" BMS
 SG_ EDS_Spd_FR : 23|16@0+ (1,-20000) [-20000|20000] "rpm" BMS
 SG_ EDS_SpdValid_FR : 39|2@0+ (1,0) [0|1] "" BMS
 SG_ EDS_MotorDriveSts_FR : 35|2@0+ (1,0) [0|3] "" BMS
 SG_ EDS_Work_STS_FR : 15|4@0+ (1,0) [0|15] "" BMS
 SG_ EDS_powoff_req_FR : 37|2@0+ (1,0) [0|1] "" BMS
BO_ 1080 EDS_Error_FR_0x438: 8 Vector__XXX
 SG_ EDS_FailNum_ERR_FWD : 7|8@0+ (1,0) [0|255] "" BMS
 SG_ EDS_FailGrade_ERR_FWD : 10|3@0+ (1,0) [0|7] "" BMS
 SG_ EDS_MotOverTempAlarm_FWD : 11|1@0+ (1,0) [0|1] "" BMS
 SG_ EDS_MotOverTempFault_FWD : 12|1@0+ (1,0) [0|1] "" BMS
 SG_ EDS_MotTempSenFault_FWD : 13|1@0+ (1,0) [0|1] "" BMS
 SG_ EDS_EDSOverTempUFault_FWD : 14|1@0+ (1,0) [0|1] "" BMS
 SG_ EDS_EDSOverTempVFault_FWD : 15|1@0+ (1,0) [0|1] "" BMS
 SG_ EDS_EDSOverTempWFault_FWD : 16|1@0+ (1,0) [0|1] "" BMS
 SG_ EDS_EDSOverTempAlarm_FWD : 17|1@0+ (1,0) [0|1] "" BMS
 SG_ EDS_TCoolantOvHi_FWD : 18|1@0+ (1,0) [0|1] "" BMS
 SG_ EDS_EDSTempCmpAlarm_FWD : 19|1@0+ (1,0) [0|1] "" BMS
 SG_ EDS_EDSPhaOvCurentHWFault_FWD : 20|1@0+ (1,0) [0|1] "" BMS
 SG_ EDS_EDSphaOffCalFault_FWD : 21|1@0+ (1,0) [0|1] "" BMS
 SG_ EDS_EDSOverIdcLnkAlarm_FWD : 22|1@0+ (1,0) [0|1] "" BMS
 SG_ EDS_EDSHVOverVoltageAlarm_FWD : 23|1@0+ (1,0) [0|1] "" BMS
 SG_ EDS_EDSHVOverVoltageFault_FWD : 24|1@0+ (1,0) [0|1] "" BMS
 SG_ EDS_EDSHVUnderVoltageAlarm_FWD : 25|1@0+ (1,0) [0|1] "" BMS
 SG_ EDS_EDSHVUnderVoltageFault_FWD : 26|1@0+ (1,0) [0|1] "" BMS
 SG_ EDS_RunToDischaErr_FWD : 27|1@0+ (1,0) [0|1] "" BMS
 SG_ EDS_12VOverVoltageAlarm_FWD : 28|1@0+ (1,0) [0|1] "" BMS
 SG_ EDS_12VUnderVoltageAlarm_FWD : 29|1@0+ (1,0) [0|1] "" BMS
 SG_ EDS_MotOverAlarm_FWD : 30|1@0+ (1,0) [0|1] "" BMS
 SG_ EDS_MotOverFault_FWD : 31|1@0+ (1,0) [0|1] "" BMS
 SG_ EDS_iDcLnkOvCLimFail_FWD : 32|1@0+ (1,0) [0|1] "" BMS
 SG_ EDS_MotBlockedFault_FWD : 33|1@0+ (1,0) [0|1] "" BMS
 SG_ EDS_RSLErr_FWD : 34|1@0+ (1,0) [0|1] "" BMS
 SG_ EDS_MotTrqLimFault_FWD : 35|1@0+ (1,0) [0|1] "" BMS
 SG_ EDS_ResolverOffsetAngle_FWD : 36|1@0+ (1,0) [0|1] "" BMS
 SG_ EDS_EDSDisChgFault_FWD : 37|1@0+ (1,0) [0|1] "" BMS
 SG_ EDS_IGBTFault_FWD : 38|1@0+ (1,0) [0|1] "" BMS
 SG_ EDS_CANBusoffFault_FWD : 39|1@0+ (1,0) [0|1] "" BMS
 SG_ EDS_TDrvBoardOvHiWarn_FWD : 40|1@0+ (1,0) [0|1] "" BMS
 SG_ EDS_TIGBTOvHiFault_FWD : 41|1@0+ (1,0) [0|1] "" BMS
 SG_ EDS_TIGBTOvHiWarn_FWD : 42|1@0+ (1,0) [0|1] "" BMS
 SG_ EDS_IOHWABSampFail_FWD : 43|1@0+ (1,0) [0|1] "" BMS
 SG_ EDS_EDSOpenFault_FWD : 44|1@0+ (1,0) [0|1] "" BMS
 SG_ EDS_MotorOpenFault_FWD : 45|1@0+ (1,0) [0|1] "" BMS
 SG_ EDS_EmacBlkdWarn_FWD : 47|1@0+ (1,0) [0|1] "" BMS
 SG_ EDS_VerMatchFailureErr_FWD : 48|1@0+ (1,0) [0|1] "" BMS
 SG_ EDS_DiashCirNoPsblErr_FWD : 49|1@0+ (1,0) [0|1] "" BMS
 SG_ EDS_OperOutdRngErr_FWD : 50|1@0+ (1,0) [0|1] "" BMS
 SG_ EDS_PhaseLossFaultErr_FWD : 51|1@0+ (1,0) [0|1] "" BMS
 SG_ EDS_CPLDFault_FWD : 52|1@0+ (1,0) [0|1] "" BMS
 SG_ EDS_CPLDFaultBaseSpd_FWD : 53|1@0+ (1,0) [0|1] "" BMS
 SG_ EDS_IOHWABNen33Fail_FWD : 54|1@0+ (1,0) [0|1] "" BMS
 SG_ EDS_HvMcuSlightFault_RWD : 55|1@0+ (1,0) [0|1] "" BMS
 SG_ EDS_HvMcuSevFault_FWD : 56|1@0+ (1,0) [0|1] "" BMS
 SG_ EDS_EDSPhaSampHWFault_FWD : 57|1@0+ (1,0) [0|1] "" BMS
 SG_ EDS_IsOvHiErr_FWD : 58|1@0+ (1,0) [0|1] "" BMS
 SG_ EDS_CanRollingCounterErr_FWD : 59|1@0+ (1,0) [0|1] "" BMS
 SG_ EDS_CanTimeoutErr_FWD : 60|1@0+ (1,0) [0|1] "" BMS
 SG_ EDS_CrashFault_FWD : 61|1@0+ (1,0) [0|1] "" BMS
BO_ 537 VCU_PT_Control_0x219: 8 Vector__XXX
 SG_ Checksum_0x219 : 7|8@0+ (1,0) [0|255] "" BMS
 SG_ Rolling_Counter_0x219 : 11|4@0+ (1,0) [0|15] "" BMS
 SG_ VCU_VehicleDischargePower : 39|7@0+ (1,0) [0|100] "%" Vector__XXX
 SG_ VCU_VehicleChargePower : 23|7@0+ (1,0) [0|100] "%" Vector__XXX
 SG_ VCU_ChargeAllow : 54|1@0+ (1,0) [0|1] "" BMS
BO_ 544 VCU_BMS_PumpValve_REQ_0x220: 8 Vector__XXX
 SG_ Checksum_0x220 : 7|8@0+ (1,0) [0|255] "" BMS
 SG_ Rolling_Counter_0x220 : 11|4@0+ (1,0) [0|15] "" BMS
 SG_ VCU_BMS_PTCOnOff_Sts : 12|1@0+ (1,0) [0|1] "" BMS
 SG_ VCU_BMS_ValveOnOff_Sts : 13|1@0+ (1,0) [0|1] "" BMS
 SG_ VCU_BMS_PumpFB : 18|3@0+ (1,0) [0|7] "" BMS
BO_ 757 VCU_Chgcontrol_0x2F5: 8 Vector__XXX
 SG_ VCU_Charge_Control : 23|2@0+ (1,0) [0|3] "" BMS
 SG_ VCU_AC_chargeSock_temp1 : 18|11@0+ (0.1,-50) [-50|100] "degree" BMS
 SG_ VCU_DC_chargeSock_temp1 : 34|11@0+ (0.1,-50) [-50|100] "degree" BMS
 SG_ VCU_DC_chargeSock_temp2 : 50|11@0+ (0.1,-50) [-50|100] "degree" BMS
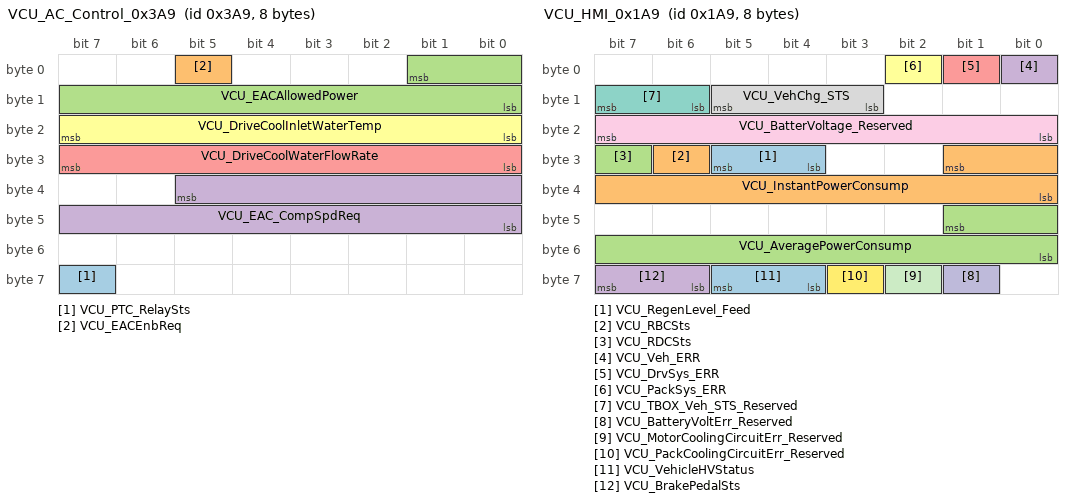
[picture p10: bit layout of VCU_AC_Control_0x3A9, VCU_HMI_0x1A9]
BO_ 937 VCU_AC_Control_0x3A9: 8 Vector__XXX
 SG_ VCU_PTC_RelaySts : 63|1@0+ (1,0) [0|1] "" BMS
 SG_ VCU_EACEnbReq : 5|1@0+ (1,0) [0|1] "" Vector__XXX
 SG_ VCU_EACAllowedPower : 1|10@0+ (0.1,0) [0|100] "KW" Vector__XXX
 SG_ VCU_EAC_CompSpdReq : 37|14@0+ (1,0) [0|16383] "rpm" Vector__XXX
 SG_ VCU_DriveCoolWaterFlowRate : 31|8@0+ (0.1,0) [0|25.4] "L/min" Vector__XXX
 SG_ VCU_DriveCoolInletWaterTemp : 23|8@0+ (1,-40) [-40|215] "degree" Vector__XXX
BO_ 425 VCU_HMI_0x1A9: 8 Vector__XXX
 SG_ VCU_RegenLevel_Feed : 29|2@0+ (1,0) [0|3] "" Vector__XXX
 SG_ VCU_RBCSts : 30|1@0+ (1,0) [0|1] "" Vector__XXX
 SG_ VCU_RDCSts : 31|1@0+ (1,0) [0|1] "" Vector__XXX
 SG_ VCU_Veh_ERR : 0|1@0+ (1,0) [0|1] "" BMS
 SG_ VCU_DrvSys_ERR : 1|1@0+ (1,0) [0|1] "" BMS
 SG_ VCU_PackSys_ERR : 2|1@0+ (1,0) [0|1] "" BMS
 SG_ VCU_TBOX_Veh_STS_Reserved : 15|2@0+ (1,0) [0|3] "" BMS
 SG_ VCU_VehChg_STS : 13|3@0+ (1,0) [0|7] "" BMS
 SG_ VCU_BatterVoltage_Reserved : 23|8@0+ (0.07,0) [0|17.85] "V" BMS
 SG_ VCU_BatteryVoltErr_Reserved : 57|1@0+ (1,0) [0|1] "" BMS
 SG_ VCU_MotorCoolingCircuitErr_Reserved : 58|1@0+ (1,0) [0|1] "" BMS
 SG_ VCU_PackCoolingCircuitErr_Reserved : 59|1@0+ (1,0) [0|1] "" BMS
 SG_ VCU_VehicleHVStatus : 61|2@0+ (1,0) [0|3] "" BMS
 SG_ VCU_InstantPowerConsump : 25|10@0+ (0.1,0) [0|100] "kwh/100km" BMS
 SG_ VCU_AveragePowerConsump : 41|10@0+ (0.1,0) [0|100] "kwh/100km" BMS
 SG_ VCU_BrakePedalSts : 63|2@0+ (1,0) [0|3] "" BMS
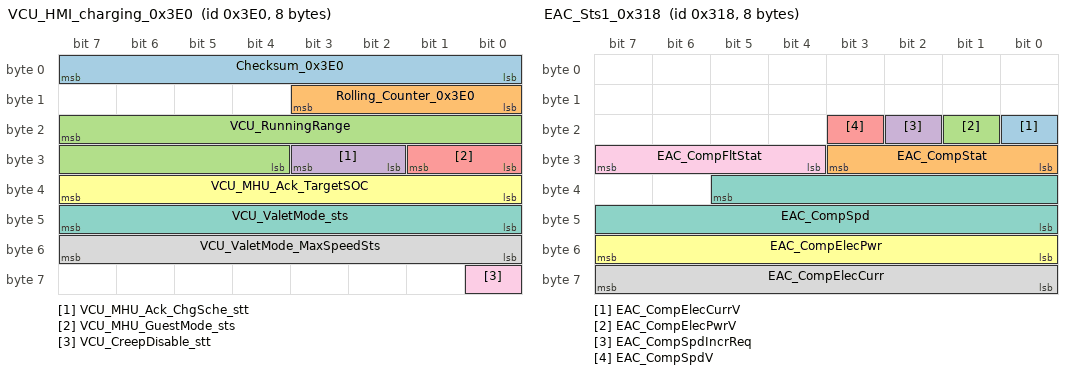
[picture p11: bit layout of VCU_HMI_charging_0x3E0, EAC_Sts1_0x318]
BO_ 992 VCU_HMI_charging_0x3E0: 8 Vector__XXX
 SG_ Checksum_0x3E0 : 7|8@0+ (1,0) [0|255] "" Vector__XXX
 SG_ Rolling_Counter_0x3E0 : 11|4@0+ (1,0) [0|15] "" Vector__XXX
 SG_ VCU_RunningRange : 23|12@0+ (0.5,0) [0|2047] "km" Vector__XXX
 SG_ VCU_MHU_Ack_ChgSche_stt : 27|2@0+ (1,0) [0|3] "" Vector__XXX
 SG_ VCU_MHU_GuestMode_sts : 25|2@0+ (1,0) [0|3] "" Vector__XXX
 SG_ VCU_MHU_Ack_TargetSOC : 39|8@0+ (1,0) [0|100] "%" BMS
 SG_ VCU_ValetMode_sts : 47|8@0+ (1,0) [0|255] "" Vector__XXX
 SG_ VCU_ValetMode_MaxSpeedSts : 55|8@0+ (1,0) [0|255] "kph" Vector__XXX
 SG_ VCU_CreepDisable_stt : 56|1@0+ (1,0) [0|1] "" Vector__XXX
BO_ 409 VCU_Sts_0x199: 8 Vector__XXX
 SG_ Checksum_0x199 : 7|8@0+ (1,0) [0|255] "" BMS
 SG_ Rolling_Counter_0x199 : 11|4@0+ (1,0) [0|15] "" BMS
 SG_ VCU_VehFailGrade_ERR : 22|3@0+ (1,0) [0|7] "" Vector__XXX
 SG_ VCU_BMS_HVOnOff_REQ : 19|2@0+ (1,0) [0|1] "" BMS
 SG_ VCU_Vehicle_Mode : 31|4@0+ (1,0) [0|15] "" BMS
BO_ 792 EAC_Sts1_0x318: 8 Vector__XXX
 SG_ EAC_CompElecCurrV : 16|1@0+ (1,0) [0|1] "" BMS
 SG_ EAC_CompStat : 27|4@0+ (1,0) [0|15] "" Vector__XXX
 SG_ EAC_CompElecPwrV : 17|1@0+ (1,0) [0|1] "" BMS
 SG_ EAC_CompSpdIncrReq : 18|1@0+ (1,0) [0|1] "" Vector__XXX
 SG_ EAC_CompSpdV : 19|1@0+ (1,0) [0|1] "" Vector__XXX
 SG_ EAC_CompElecPwr : 55|8@0+ (40,0) [0|10200] "W" BMS
 SG_ EAC_CompSpd : 37|14@0+ (1,0) [0|16383] "rpm" Vector__XXX
 SG_ EAC_CompElecCurr : 63|8@0+ (0.2,0) [0|51] "A" Vector__XXX
 SG_ EAC_CompFltStat : 31|4@0+ (1,0) [0|15] "" Vector__XXX
BO_ 524 GW_IPC_ODO_0x20C: 8 Vector__XXX
 SG_ Checksum_0x20C : 7|8@0+ (1,0) [0|255] "" BMS
 SG_ Rolling_Counter_0x20C : 11|4@0+ (1,0) [0|15] "" BMS
 SG_ IPC_ODO : 31|20@0+ (1,0) [0|999999] "km" BMS
BO_ 703 GW_IPC_Information_0x2BF: 8 Vector__XXX
 SG_ IPC_TripA : 7|16@0+ (0.1,0) [0|999.9] "km" Vector__XXX
 SG_ IPC_AverageSpeedTripA : 27|12@0+ (0.0625,0) [0|250] "km/h" Vector__XXX
 SG_ IPC_AverageConsumptionTripA : 23|10@0+ (0.1,0) [0|100] "kwh/100km" Vector__XXX
 SG_ IPC_ParkBrakeSts : 29|2@0+ (1,0) [0|3] "" Vector__XXX
 SG_ IPC_VehSpd : 54|15@0+ (0.01,0) [0|327.66] "kph" BMS
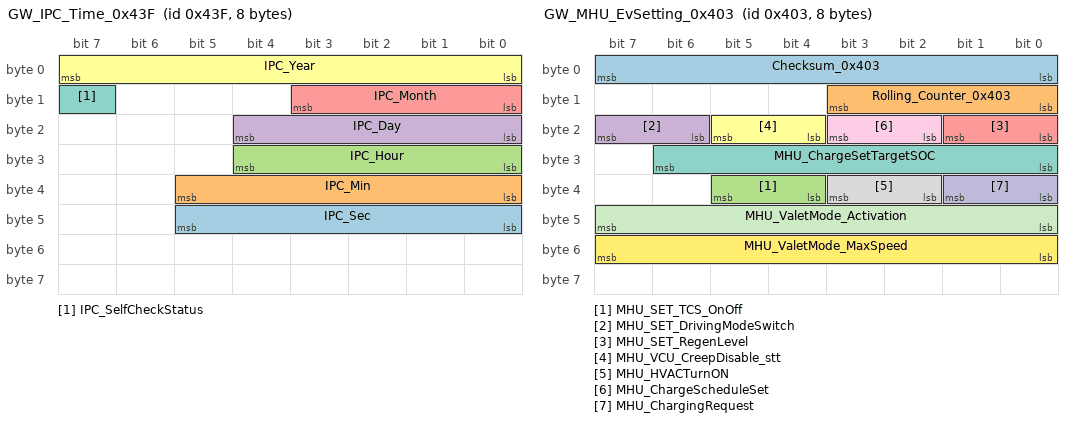
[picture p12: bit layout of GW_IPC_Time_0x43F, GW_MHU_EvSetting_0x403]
BO_ 1087 GW_IPC_Time_0x43F: 8 Vector__XXX
 SG_ IPC_Sec : 45|6@0+ (1,0) [0|59] "second" BMS
 SG_ IPC_Min : 37|6@0+ (1,0) [0|59] "min" BMS
 SG_ IPC_Hour : 28|5@0+ (1,0) [0|23] "hour" BMS
 SG_ IPC_Day : 20|5@0+ (1,0) [1|31] "" BMS
 SG_ IPC_Month : 11|4@0+ (1,0) [1|12] "" BMS
 SG_ IPC_Year : 7|8@0+ (1,2000) [2000|2255] "" BMS
 SG_ IPC_SelfCheckStatus : 15|1@0+ (1,0) [0|1] "" BMS
BO_ 1074 GW_TELEMATICS_SERVICES_0x432: 8 Vector__XXX
 SG_ Checksum_0x432 : 7|8@0+ (1,0) [0|255] "" BMS
 SG_ Rolling_Counter_0x432 : 11|4@0+ (1,0) [0|14] "" BMS
 SG_ MHU_FOTA_State : 15|4@0+ (1,0) [0|14] "" BMS
 SG_ MHU_FOTA_Error_Code : 23|8@0+ (1,0) [0|255] "" BMS
BO_ 1027 GW_MHU_EvSetting_0x403: 8 Vector__XXX
 SG_ Checksum_0x403 : 7|8@0+ (1,0) [0|255] "" BMS
 SG_ Rolling_Counter_0x403 : 11|4@0+ (1,0) [0|15] "" BMS
 SG_ MHU_SET_TCS_OnOff : 37|2@0+ (1,0) [0|3] "" BMS
 SG_ MHU_SET_DrivingModeSwitch : 23|2@0+ (1,0) [0|3] "" BMS
 SG_ MHU_SET_RegenLevel : 17|2@0+ (1,0) [0|3] "" BMS
 SG_ MHU_VCU_CreepDisable_stt : 21|2@0+ (1,0) [0|3] "" BMS
 SG_ MHU_ChargeSetTargetSOC : 30|7@0+ (1,0) [10|100] "Percentage" BMS
 SG_ MHU_HVACTurnON : 35|2@0+ (1,0) [0|3] "" BMS
 SG_ MHU_ChargeScheduleSet : 19|2@0+ (1,0) [0|3] "" BMS
 SG_ MHU_ChargingRequest : 33|2@0+ (1,0) [0|3] "" BMS
 SG_ MHU_ValetMode_Activation : 47|8@0+ (1,0) [0|254] "" BMS
 SG_ MHU_ValetMode_MaxSpeed : 55|8@0+ (1,0) [0|254] "kph" BMS
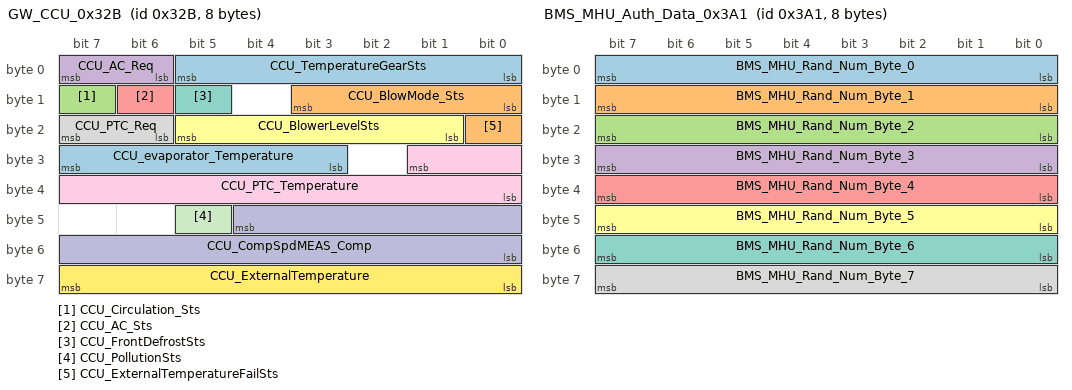
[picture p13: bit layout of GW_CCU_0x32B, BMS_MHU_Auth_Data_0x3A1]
BO_ 811 GW_CCU_0x32B: 8 Vector__XXX
 SG_ CCU_TemperatureGearSts : 5|6@0+ (1,0) [0|63] "" Vector__XXX
 SG_ CCU_BlowMode_Sts : 11|4@0+ (1,0) [0|15] "" Vector__XXX
 SG_ CCU_Circulation_Sts : 15|1@0+ (1,0) [0|1] "" Vector__XXX
 SG_ CCU_AC_Req : 7|2@0+ (1,0) [0|3] "" Vector__XXX
 SG_ CCU_AC_Sts : 14|1@0+ (1,0) [0|1] "" Vector__XXX
 SG_ CCU_BlowerLevelSts : 21|5@0+ (1,0) [0|9] "" Vector__XXX
 SG_ CCU_FrontDefrostSts : 13|1@0+ (1,0) [0|1] "" Vector__XXX
 SG_ CCU_PTC_Req : 23|2@0+ (1,0) [0|3] "" Vector__XXX
 SG_ CCU_PTC_Temperature : 25|10@0+ (0.1,0) [0|100] "°C" Vector__XXX
 SG_ CCU_CompSpdMEAS_Comp : 44|13@0+ (1,0) [0|8191] "rpm" Vector__XXX
 SG_ CCU_PollutionSts : 45|1@0+ (1,0) [0|1] "" Vector__XXX
 SG_ CCU_ExternalTemperature : 63|8@0+ (0.5,-40) [-40|87] "°C" BMS
 SG_ CCU_evaporator_Temperature : 31|5@0+ (1,-10) [-10|20] "°C" Vector__XXX
 SG_ CCU_ExternalTemperatureFailSts : 16|1@0+ (1,0) [0|1] "" BMS
BO_ 929  BMS_MHU_Auth_Data_0x3A1: 8 BMS
 SG_ BMS_MHU_Rand_Num_Byte_0 : 7|8@0+ (1,0) [0|255] "" Vector__XXX
 SG_ BMS_MHU_Rand_Num_Byte_1 : 15|8@0+ (1,0) [0|255] "" Vector__XXX
 SG_ BMS_MHU_Rand_Num_Byte_2 : 23|8@0+ (1,0) [0|255] "" Vector__XXX
 SG_ BMS_MHU_Rand_Num_Byte_3 : 31|8@0+ (1,0) [0|255] "" Vector__XXX
 SG_ BMS_MHU_Rand_Num_Byte_4 : 39|8@0+ (1,0) [0|255] "" Vector__XXX
 SG_ BMS_MHU_Rand_Num_Byte_5 : 47|8@0+ (1,0) [0|255] "" Vector__XXX
 SG_ BMS_MHU_Rand_Num_Byte_6 : 55|8@0+ (1,0) [0|255] "" Vector__XXX
 SG_ BMS_MHU_Rand_Num_Byte_7 : 63|8@0+ (1,0) [0|255] "" Vector__XXX
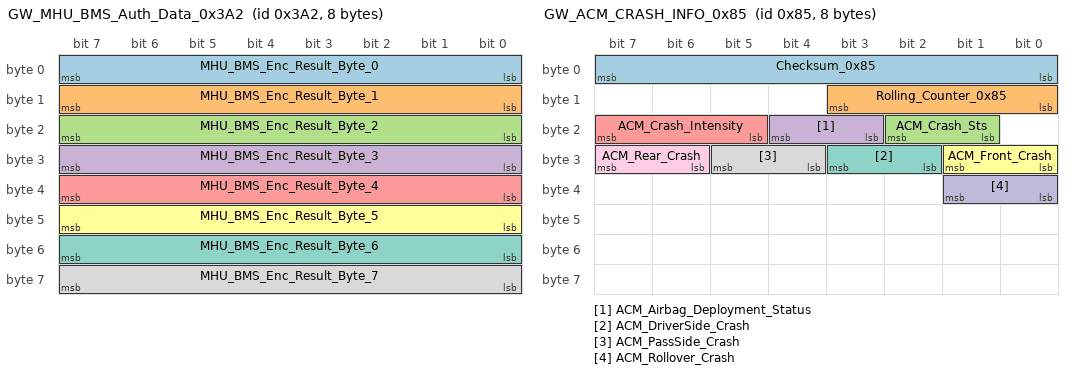
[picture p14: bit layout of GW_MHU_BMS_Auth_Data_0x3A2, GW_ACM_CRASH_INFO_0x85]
BO_ 930 GW_MHU_BMS_Auth_Data_0x3A2: 8 Vector__XXX
 SG_ MHU_BMS_Enc_Result_Byte_0 : 7|8@0+ (1,0) [0|255] "" BMS
 SG_ MHU_BMS_Enc_Result_Byte_1 : 15|8@0+ (1,0) [0|255] "" BMS
 SG_ MHU_BMS_Enc_Result_Byte_2 : 23|8@0+ (1,0) [0|255] "" BMS
 SG_ MHU_BMS_Enc_Result_Byte_3 : 31|8@0+ (1,0) [0|255] "" BMS
 SG_ MHU_BMS_Enc_Result_Byte_4 : 39|8@0+ (1,0) [0|255] "" BMS
 SG_ MHU_BMS_Enc_Result_Byte_5 : 47|8@0+ (1,0) [0|255] "" BMS
 SG_ MHU_BMS_Enc_Result_Byte_6 : 55|8@0+ (1,0) [0|255] "" BMS
 SG_ MHU_BMS_Enc_Result_Byte_7 : 63|8@0+ (1,0) [0|255] "" BMS
BO_ 274 GW_BCM_CLAMP_STAT_0x112: 8 Vector__XXX
 SG_ Checksum_0x112 : 7|8@0+ (1,0) [0|255] "" BMS
 SG_ Rolling_Counter_0x112 : 11|4@0+ (1,0) [0|15] "" BMS
 SG_ STAT_Terminal : 34|3@0+ (1,0) [0|7] "Bit" BMS
 SG_ STAT_CL30s_L_Reserved : 41|2@0+ (1,0) [0|3] "Bit" Vector__XXX
BO_ 266 GW_BCM_VOLTAGE_0x10a: 8 Vector__XXX
 SG_ Checksum_0x10a : 7|8@0+ (1,0) [0|255] "" BMS
 SG_ Rolling_Counter_0x10a : 11|4@0+ (1,0) [0|15] "" BMS
 SG_ BCM_LVTop_up : 24|1@0+ (1,0) [0|1] "" Vector__XXX
 SG_ Ubatt_Reserved : 23|14@0+ (0.001,3) [3|18] "V" BMS
BO_ 133 GW_ACM_CRASH_INFO_0x85: 8 Vector__XXX
 SG_ Checksum_0x85 : 7|8@0+ (1,0) [0|255] "" BMS
 SG_ Rolling_Counter_0x85 : 11|4@0+ (1,0) [0|15] "" BMS
 SG_ ACM_Crash_Sts : 18|2@0+ (1,0) [0|3] "" BMS
 SG_ ACM_Airbag_Deployment_Status : 20|2@0+ (1,0) [0|3] "" Vector__XXX
 SG_ ACM_Crash_Intensity : 23|3@0+ (1,0) [0|7] "" BMS
 SG_ ACM_Front_Crash : 25|2@0+ (1,0) [0|3] "" Vector__XXX
 SG_ ACM_DriverSide_Crash : 27|2@0+ (1,0) [0|3] "" Vector__XXX
 SG_ ACM_PassSide_Crash : 29|2@0+ (1,0) [0|3] "" Vector__XXX
 SG_ ACM_Rear_Crash : 31|2@0+ (1,0) [0|3] "" Vector__XXX
 SG_ ACM_Rollover_Crash : 33|2@0+ (1,0) [0|3] "" Vector__XXX
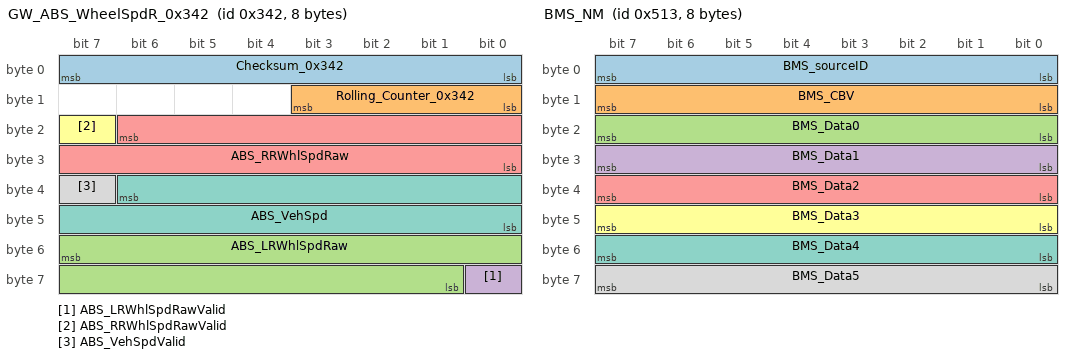
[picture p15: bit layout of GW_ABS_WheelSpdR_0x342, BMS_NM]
BO_ 834 GW_ABS_WheelSpdR_0x342: 8 Vector__XXX
 SG_ Checksum_0x342 : 7|8@0+ (1,0) [0|255] "" BMS
 SG_ Rolling_Counter_0x342 : 11|4@0+ (1,0) [0|15] "" BMS
 SG_ ABS_LRWhlSpdRaw : 55|15@0+ (0.01,0) [0|327.66] "kph" Vector__XXX
 SG_ ABS_LRWhlSpdRawValid : 56|1@0+ (1,0) [0|1] "" Vector__XXX
 SG_ ABS_RRWhlSpdRaw : 22|15@0+ (0.01,0) [0|327.66] "kph" Vector__XXX
 SG_ ABS_RRWhlSpdRawValid : 23|1@0+ (1,0) [0|1] "" Vector__XXX
 SG_ ABS_VehSpd : 38|15@0+ (0.01,0) [0|327.66] "kph" BMS
 SG_ ABS_VehSpdValid : 39|1@0+ (1,0) [0|1] "" BMS
BO_ 1299 BMS_NM: 8 BMS
 SG_ BMS_sourceID : 7|8@0+ (1,0) [0|255] "" Vector__XXX
 SG_ BMS_CBV : 15|8@0+ (1,0) [0|255] "" Vector__XXX
 SG_ BMS_Data0 : 23|8@0+ (1,0) [0|255] "" Vector__XXX
 SG_ BMS_Data1 : 31|8@0+ (1,0) [0|255] "" Vector__XXX
 SG_ BMS_Data2 : 39|8@0+ (1,0) [0|255] "" Vector__XXX
 SG_ BMS_Data3 : 47|8@0+ (1,0) [0|255] "" Vector__XXX
 SG_ BMS_Data4 : 55|8@0+ (1,0) [0|255] "" Vector__XXX
 SG_ BMS_Data5 : 63|8@0+ (1,0) [0|255] "" Vector__XXX
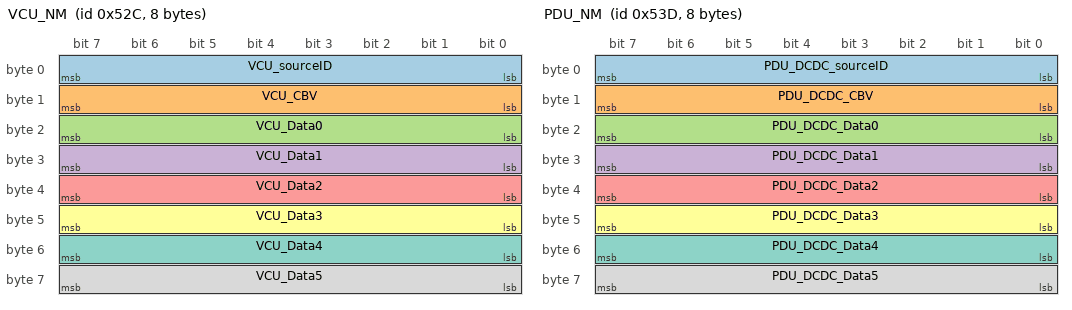
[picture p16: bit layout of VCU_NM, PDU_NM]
BO_ 1324 VCU_NM: 8 Vector__XXX
 SG_ VCU_sourceID : 7|8@0+ (1,0) [0|255] "" BMS
 SG_ VCU_CBV : 15|8@0+ (1,0) [0|255] "" BMS
 SG_ VCU_Data0 : 23|8@0+ (1,0) [0|255] "" BMS
 SG_ VCU_Data1 : 31|8@0+ (1,0) [0|255] "" BMS
 SG_ VCU_Data2 : 39|8@0+ (1,0) [0|255] "" BMS
 SG_ VCU_Data3 : 47|8@0+ (1,0) [0|255] "" BMS
 SG_ VCU_Data4 : 55|8@0+ (1,0) [0|255] "" BMS
 SG_ VCU_Data5 : 63|8@0+ (1,0) [0|255] "" BMS
BO_ 1341 PDU_NM: 8 Vector__XXX
 SG_ PDU_DCDC_sourceID : 7|8@0+ (1,0) [0|255] "" BMS
 SG_ PDU_DCDC_CBV : 15|8@0+ (1,0) [0|255] "" BMS
 SG_ PDU_DCDC_Data0 : 23|8@0+ (1,0) [0|255] "" BMS
 SG_ PDU_DCDC_Data1 : 31|8@0+ (1,0) [0|255] "" BMS
 SG_ PDU_DCDC_Data2 : 39|8@0+ (1,0) [0|255] "" BMS
 SG_ PDU_DCDC_Data3 : 47|8@0+ (1,0) [0|255] "" BMS
 SG_ PDU_DCDC_Data4 : 55|8@0+ (1,0) [0|255] "" BMS
 SG_ PDU_DCDC_Data5 : 63|8@0+ (1,0) [0|255] "" BMS
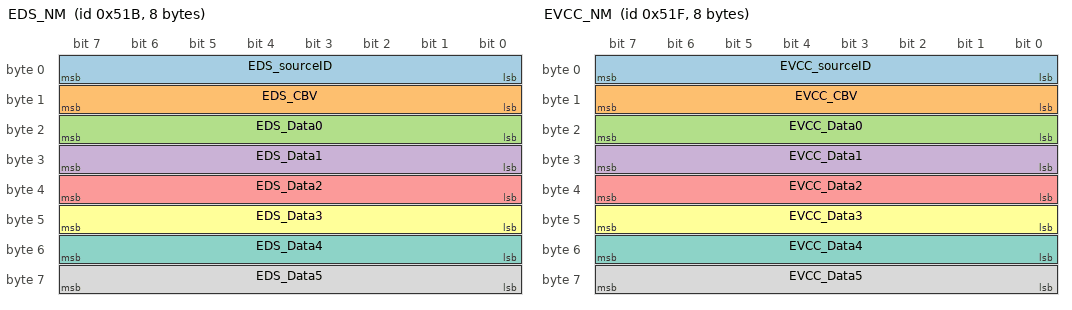
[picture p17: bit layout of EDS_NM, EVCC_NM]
BO_ 1307 EDS_NM: 8 Vector__XXX
 SG_ EDS_sourceID : 7|8@0+ (1,0) [0|255] "" BMS
 SG_ EDS_CBV : 15|8@0+ (1,0) [0|255] "" BMS
 SG_ EDS_Data0 : 23|8@0+ (1,0) [0|255] "" BMS
 SG_ EDS_Data1 : 31|8@0+ (1,0) [0|255] "" BMS
 SG_ EDS_Data2 : 39|8@0+ (1,0) [0|255] "" BMS
 SG_ EDS_Data3 : 47|8@0+ (1,0) [0|255] "" BMS
 SG_ EDS_Data4 : 55|8@0+ (1,0) [0|255] "" BMS
 SG_ EDS_Data5 : 63|8@0+ (1,0) [0|255] "" BMS
BO_ 1311 EVCC_NM: 8 Vector__XXX
 SG_ EVCC_sourceID : 7|8@0+ (1,0) [0|255] "" BMS
 SG_ EVCC_CBV : 15|8@0+ (1,0) [0|255] "" BMS
 SG_ EVCC_Data0 : 23|8@0+ (1,0) [0|255] "" BMS
 SG_ EVCC_Data1 : 31|8@0+ (1,0) [0|255] "" BMS
 SG_ EVCC_Data2 : 39|8@0+ (1,0) [0|255] "" BMS
 SG_ EVCC_Data3 : 47|8@0+ (1,0) [0|255] "" BMS
 SG_ EVCC_Data4 : 55|8@0+ (1,0) [0|255] "" BMS
 SG_ EVCC_Data5 : 63|8@0+ (1,0) [0|255] "" BMS
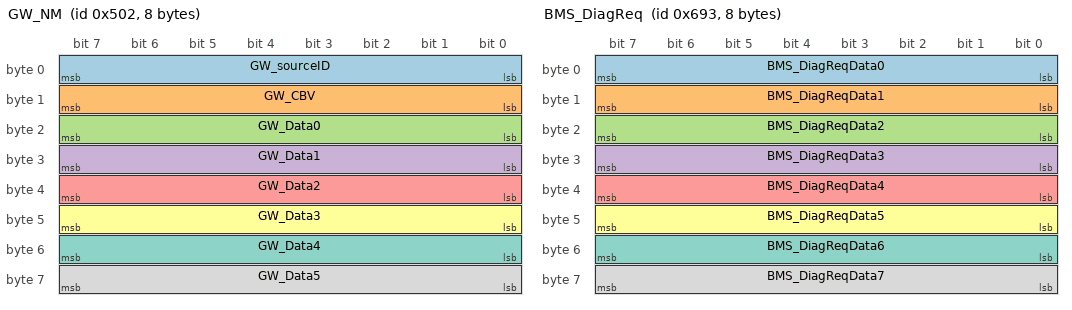
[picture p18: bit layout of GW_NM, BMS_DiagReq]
BO_ 1282 GW_NM: 8 Vector__XXX
 SG_ GW_sourceID : 7|8@0+ (1,0) [0|255] "" BMS
 SG_ GW_CBV : 15|8@0+ (1,0) [0|255] "" BMS
 SG_ GW_Data0 : 23|8@0+ (1,0) [0|255] "" BMS
 SG_ GW_Data1 : 31|8@0+ (1,0) [0|255] "" BMS
 SG_ GW_Data2 : 39|8@0+ (1,0) [0|255] "" BMS
 SG_ GW_Data3 : 47|8@0+ (1,0) [0|255] "" BMS
 SG_ GW_Data4 : 55|8@0+ (1,0) [0|255] "" BMS
 SG_ GW_Data5 : 63|8@0+ (1,0) [0|255] "" BMS
BO_ 1683 BMS_DiagReq: 8 Vector__XXX
 SG_ BMS_DiagReqData0 : 7|8@0+ (1,0) [0|255] "" BMS
 SG_ BMS_DiagReqData1 : 15|8@0+ (1,0) [0|255] "" BMS
 SG_ BMS_DiagReqData2 : 23|8@0+ (1,0) [0|255] "" BMS
 SG_ BMS_DiagReqData3 : 31|8@0+ (1,0) [0|255] "" BMS
 SG_ BMS_DiagReqData4 : 39|8@0+ (1,0) [0|255] "" BMS
 SG_ BMS_DiagReqData5 : 47|8@0+ (1,0) [0|255] "" BMS
 SG_ BMS_DiagReqData6 : 55|8@0+ (1,0) [0|255] "" BMS
 SG_ BMS_DiagReqData7 : 63|8@0+ (1,0) [0|255] "" BMS
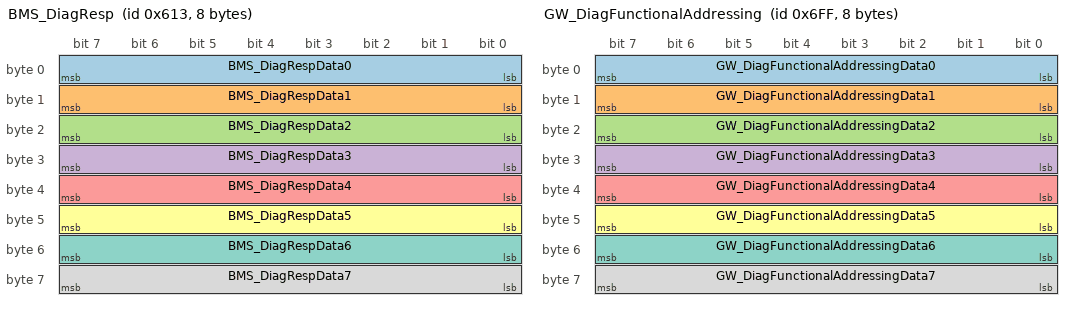
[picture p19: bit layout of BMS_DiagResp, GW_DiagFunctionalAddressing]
BO_ 1555 BMS_DiagResp: 8 BMS
 SG_ BMS_DiagRespData0 : 7|8@0+ (1,0) [0|255] "" Vector__XXX
 SG_ BMS_DiagRespData1 : 15|8@0+ (1,0) [0|255] "" Vector__XXX
 SG_ BMS_DiagRespData2 : 23|8@0+ (1,0) [0|255] "" Vector__XXX
 SG_ BMS_DiagRespData3 : 31|8@0+ (1,0) [0|255] "" Vector__XXX
 SG_ BMS_DiagRespData4 : 39|8@0+ (1,0) [0|255] "" Vector__XXX
 SG_ BMS_DiagRespData5 : 47|8@0+ (1,0) [0|255] "" Vector__XXX
 SG_ BMS_DiagRespData6 : 55|8@0+ (1,0) [0|255] "" Vector__XXX
 SG_ BMS_DiagRespData7 : 63|8@0+ (1,0) [0|255] "" Vector__XXX
BO_ 1791 GW_DiagFunctionalAddressing: 8 Vector__XXX
 SG_ GW_DiagFunctionalAddressingData0 : 7|8@0+ (1,0) [0|255] "" BMS
 SG_ GW_DiagFunctionalAddressingData1 : 15|8@0+ (1,0) [0|255] "" BMS
 SG_ GW_DiagFunctionalAddressingData2 : 23|8@0+ (1,0) [0|255] "" BMS
 SG_ GW_DiagFunctionalAddressingData3 : 31|8@0+ (1,0) [0|255] "" BMS
 SG_ GW_DiagFunctionalAddressingData4 : 39|8@0+ (1,0) [0|255] "" BMS
 SG_ GW_DiagFunctionalAddressingData5 : 47|8@0+ (1,0) [0|255] "" BMS
 SG_ GW_DiagFunctionalAddressingData6 : 55|8@0+ (1,0) [0|255] "" BMS
 SG_ GW_DiagFunctionalAddressingData7 : 63|8@0+ (1,0) [0|255] "" BMS
CM_ SG_ 673 Checksum_0x2A1 "Checksum";
CM_ SG_ 673 Rolling_Counter_0x2A1 "Rolling_Counter";
CM_ SG_ 673 ODS_Status "Status of ODS";
CM_ SG_ 673 EVCC_MHU_CharSchSetFeedBack "MHU ChargeScheduleSet Feedback";
CM_ SG_ 673 EVCC_ChargeGunSts "charge gun statue";
CM_ SG_ 673 EVCC_ChargeMode "change mode AC or DC";
CM_ SG_ 673 EVCC_CP_Value "CP dutyvalue";
CM_ SG_ 673 EVCC_CP_Sts "CP State";
CM_ SG_ 673 EVCC_PP_Value "PP resistance value or state";
CM_ SG_ 673 EVCC_Lock_Sts "lock state";
CM_ SG_ 673 EVCC_ErrCode "EVCC Error code";
CM_ SG_ 682 Checksum_0x2AA "Checksum";
CM_ SG_ 682 Rolling_Counter_0x2AA "Rolling_Counter";
CM_ SG_ 682 EVCC_PLC_CommSts "PLC communication states";
CM_ SG_ 682 EVCC_DC_ChargeProcess "DC charge process";
CM_ SG_ 682 EVCC_BMS_InsulationMonReq "When DC charging, close the BMS insulation detection command";
CM_ SG_ 683 Checksum_0x2AB "Checksum";
CM_ SG_ 683 Rolling_Counter_0x2AB "Rolling_Counter";
CM_ SG_ 683 EVCC_OBC_PowerReq "require power for OBC";
CM_ SG_ 683 EVCC_OBC_VoltageReq "require voltage for OBC";
CM_ SG_ 683 EVCC_OBC_CurrentReq "require current for OBC";
CM_ SG_ 683 EVCC_OBC_Control "Enable/Disable OBC command";
CM_ SG_ 683 EVCC_AC_ChargeSts "AC Charge state";
CM_ SG_ 536 Checksum_0x218 "Checksum";
CM_ SG_ 536 Rolling_Counter_0x218 "Rolling_Counter";
CM_ SG_ 536 BMS_DC_Charge_input "BMS DC Charge input statue";
CM_ SG_ 536 BMS_DC_Charge_Req "BMS DC Charge request";
CM_ SG_ 536 BMS_DC_ChargeRelay_Sts "BMS DC Charge relay statue";
CM_ SG_ 534 Checksum_0x216 "Checksum";
CM_ SG_ 534 Rolling_Counter_0x216 "Rolling_Counter";
CM_ SG_ 534 BMS_RemainChargeTime "Charge remaining time (XGW - IPC)";
CM_ SG_ 534 BMS_ChgVoltage_REQ "BMS requires charging voltage";
CM_ SG_ 534 BMS_ChgCurrent_REQ "BMS requires charging current";
CM_ SG_ 294 Checksum_0x126 "Checksum";
CM_ SG_ 294 Rolling_Counter_0x126 "Rolling_Counter";
CM_ SG_ 294 BMS_AllowChgCurrPeak "Peak allowable charge current of battery";
CM_ SG_ 294 BMS_AllowChgCurr "Continuous maximum allowable charge current of battery";
CM_ SG_ 521 Checksum_0x209 "Checksum";
CM_ SG_ 521 Rolling_Counter_0x209 "Rolling_Counter";
CM_ SG_ 521 BMS_MaxDischgPwr_ALW "Allow Max Discharge Power";
CM_ SG_ 521 BMS_MaxChgPwr_ALW "Allow Max Regenerative Power";
CM_ SG_ 521 BMS_MaxDischgPwr_Peak "Peak Discharge Power";
CM_ SG_ 521 BMS_MaxChgPwr_Peak "Peak Regenerative Power";
CM_ SG_ 585 Checksum_0x249 "Checksum";
CM_ SG_ 585 Rolling_Counter_0x249 "Rolling Counter";
CM_ SG_ 585 BMS_CoolantOutletTemp "Temperature of Battery Coolant Outlet";
CM_ SG_ 585 BMS_CoolantInletTemp "Temperature of Battery Coolant Inlet";
CM_ SG_ 584 Checksum_0x248 "Checksum";
CM_ SG_ 584 Rolling_Counter_0x248 "Rolling Counter";
CM_ SG_ 584 BMS_FlowRate_Req "Flow rate required";
CM_ SG_ 584 BMS_CoolPwrDemand "requesting the cooling power required fro the battery pack";
CM_ SG_ 584 BMS_VCU_ValveOnOff_Req "requesting VCU to turn on and off the valve";
CM_ SG_ 584 BMS_HeatPwrDemand "requesting the heating power required fro the battery pack";
CM_ SG_ 584 BMS_VCU_PTCOnOff_Req "PTC Heater turn on and off request";
CM_ SG_ 518 Checksum_0x206 "Checksum";
CM_ SG_ 518 Rolling_Counter_0x206 "Rolling Counter";
CM_ SG_ 518 BMS_MaxMinDiffCellVol "max and min cell voltage differences";
CM_ SG_ 818 Checksum_0x332 "Rolling Counter";
CM_ SG_ 818 Rolling_Counter_0x332 "Checksum";
CM_ SG_ 818 BMS_PackTemp_Infor "Pack Temperature";
CM_ SG_ 818 BMS_PackCNom "Nominal capacity of the battery pack";
CM_ SG_ 816 Checksum_0x330 "Rolling Counter";
CM_ SG_ 816 Rolling_Counter_0x330 "Checksum";
CM_ SG_ 816 BMS_ContactorAging "Aging condition of contactor";
CM_ SG_ 374 Checksum_0x176 "Checksum";
CM_ SG_ 374 Rolling_Counter_0x176 "Rolling Counter";
CM_ SG_ 374 BMS_HVLinkVol_MEAS "Link Voltage";
CM_ SG_ 374 BMS_HVPackVol_MEAS "Pack Voltage";
CM_ SG_ 375 Checksum_0x177 "Checksum";
CM_ SG_ 375 Rolling_Counter_0x177 "Rolling Counter";
CM_ SG_ 375 BMS_HVBusVol_MEAS "BUS Voltage, it is informative";
CM_ SG_ 375 BMS_HVFuseVol_MEAS "Measure voltage after fuse to identify the fuse is blown or not";
CM_ SG_ 372 Checksum_0x174 "Checksum";
CM_ SG_ 372 Rolling_Counter_0x174 "Rolling_Counter";
CM_ SG_ 372 BMS_PackCur_MEAS "Pack Current";
CM_ SG_ 533 Checksum_0x215 "Checksum";
CM_ SG_ 533 Rolling_Counter_0x215 "Rolling Counter";
CM_ SG_ 533 BMS_SOE "BMS State Of Enegy";
CM_ SG_ 533 BMS_HWCrash_Sts "Battery Pack Hardware Crash signal Status";
CM_ SG_ 533 BMS_HVIL_STS "The HVIL state of BMS";
CM_ SG_ 533 BMS_IGN_Sts "the ignition signal status (on/off)";
CM_ SG_ 533 BMS_Sys_STS "BMS_Status(Self-test after BMS wake-up)";
CM_ SG_ 533 BMS_HVOnOff_STS "BMS High Voltage Status(BMS_HVOnOff_STS to be received by all modules,Used as a flash programming pre-condition (replacement for engine running)";
CM_ SG_ 533 BMS_Balance_STS "BMS Balance Status";
CM_ SG_ 533 BMS_SocActual_EST "Actual SOC";
CM_ SG_ 533 BMS_BatBalance_ERR "Battery Balance Error indicates Balancing switch is short or open";
CM_ SG_ 533 BMS_ISU_Status "Insulation status";
CM_ SG_ 533 BMS_ERR_LEV "BMS requesting VCU to operate at the limited operating strategy (LOS)";
CM_ SG_ 533 BMS_SOH "BMS State Of Health";
CM_ SG_ 533 BMS_HV_Sts "BMS High Voltage Status";
CM_ SG_ 931 BMS_MHU_Auth_Sts "BMS and MHU Authentication status";
CM_ SG_ 532 Checksum_0x214 "Checksum";
CM_ SG_ 532 Rolling_Counter_0x214 "Rolling Counter";
CM_ SG_ 532 BMS_Display_SOC "Display SOC";
CM_ SG_ 549 Checksum_0x225 "Checksum";
CM_ SG_ 549 Rolling_Counter_0x225 "Rolling Counter";
CM_ SG_ 549 CDM_bAcvCanComStblMon "Monitored flag indicating active stable CAN communication.";
CM_ SG_ 549 FRMo_bErrHvbatStReqExtMon "Collective error flag indicating HV battery state request E2E fault.";
CM_ SG_ 549 FRMo_bErrChrgnAllwdExtMon "Collective error flag indicating charging allowed E2E fault.";
CM_ SG_ 549 FRMo_bErrVehCrashStExtMon "Collective error flag indicating vehicle crash state E2E fault.";
CM_ SG_ 549 CDM_bErrComctnLossCanMon "Error flag indicating total loss of CAN communication fault.";
CM_ SG_ 549 CTCMon_bErrCtctrSopcMon "Error flag indicating contactor switch-off path test fault.";
CM_ SG_ 549 CTCMon_bInvldCtctrHisdIFbMon "Error flag indicating high-side feedback current invalidity.";
CM_ SG_ 549 CTCMon_bInvldCtctrLosdUFbMon "Error flag indicating low-side feedback voltage invalidity.";
CM_ SG_ 549 CTM_bErrCellTDifMaxMon "Error flag indicating maximum cell temperature difference fault.";
CM_ SG_ 549 CTM_bErrCellTMaxMon "Error flag indicating maximum cell temperature limit fault.";
CM_ SG_ 549 CTM_bErrCellTMinMon "Error flag indicating minimum cell temperature limit fault.";
CM_ SG_ 549 CTM_bErrThrwyPredMon "Error flag indicating thermal runaway fault.";
CM_ SG_ 549 CUM_bErrCellUDifMaxMon "Error flag indicating maximum cell voltage difference fault.";
CM_ SG_ 549 CUM_bErrCellUMaxMon "Error flag indicating cell overvoltage fault.";
CM_ SG_ 549 CUM_bErrCellUMinMon "Error flag indicating cell undervoltage fault.";
CM_ SG_ 549 CUM_bErrCellUProtnMaxNvMon "Non-volatile error flag indicating cell overvoltage protection limit fault.";
CM_ SG_ 549 CUM_bErrCellUProtnMinNvMon "Non-volatile error flag indicating cell overvoltage protection limit fault.";
CM_ SG_ 549 CUM_bErrPackUImplyMon "Error flag indicating pack voltage implausibility.";
CM_ SG_ 549 EHPMon_bRdyHvilMon "Ready flag indicating operational HVIL circuit.";
CM_ SG_ 549 EHPMon_bErrWlddNegNvMon "Non-volatile error flag indicating welded negative contactor fault.";
CM_ SG_ 549 EHPMon_bErrWlddPosNvMon "Non-volatile error flag indicating welded positive contactor fault.";
CM_ SG_ 549 EHPMon_bErrWlddPrechNvMon "Non-volatile error flag indicating welded precharge contactor fault.";
CM_ SG_ 549 EHPMon_bErrHvilMon "Error flag indicating HVIL open line fault.";
CM_ SG_ 549 EHPMon_bErrHvilShoMon "Error flag indicating HVIL invalidity (ScG/ScB) fault.";
CM_ SG_ 549 EHPMon_bErrPackIslnRNvMon "Non-volatile error flag indicating pack level isolation resistance fault.";
CM_ SG_ 549 EHPMon_bErrVehCrashNvMon "Non-volatile error flag indicating vehicle crash fault .";
CM_ SG_ 549 EHPMon_bErrVehIslnRNvMon "Non-volatile error flag indicating vehicle level isolation resistance fault.";
CM_ SG_ 549 FRMo_bErrMemStorgNvMon "Error flag indicating storage fault in the non-volatile memory.";
CM_ SG_ 549 L1IM_bErrClmp30MaxMonInp "Error flag indicating Level 1 KL30 overvoltage fault.";
CM_ SG_ 549 L1IM_bErrClmp30MinMonInp "Error flag indicating Level 1 KL30 undervoltage fault.";
CM_ SG_ 549 L1IM_bErrCtctrDtrtMonInp "Error flag indicating Level 1 contactor deterioration fault.";
CM_ SG_ 549 L1IM_bErrUActImplyMonInp "Error flag indicating Level 1 high voltage implausibility.";
CM_ SG_ 549 MCCM_bAcvMdulCtlrStsMon "Active flag indicating operational module controller status.";
CM_ SG_ 549 MCCM_bErrLntecSngFltMon "Error flag indicating single-point safety mechanism fault of the Multi-Stack Battery Monitor.";
CM_ SG_ 549 MCCM_bErrLntecLtntFltMon "Error flag indicating latent safety mechanism fault of the Multi-Stack Battery Monitor.";
CM_ SG_ 549 MCCM_bErrMdulCellSnsrCfgMon "Error flag indicating module/cell/temperature sensor configuration fault.";
CM_ SG_ 549 MCCM_bErrMdulCtlrComMon "Error flag indicating module controller communication status fault.";
CM_ SG_ 549 MCCM_bErrSnsrTEltlMon "Error flag indicating multiple temperature sensor in a module fault.";
CM_ SG_ 549 MCCM_bWarnSnsrTEltlMon "Error flag indicating single temperature sensor in a module fault.";
CM_ SG_ 549 PCM_bRdySnsrIMon "Ready flag indicating operational current sensors.";
CM_ SG_ 549 PCM_bErrPackEFlowMaxLimMon "Error flag indicating energy flow limit fault.";
CM_ SG_ 549 PCM_bErrPackIChDchaMaxLimMon "Error flag indicating pack current charging/discharging limit fault.";
CM_ SG_ 549 PCM_bErrSnsrIImplyMon "Error flag indicating current sensor implausibility fault.";
CM_ SG_ 549 FRMo_bErrSnsrI1ExtMon "Collective error flag indicating current sensor 1 (CAN-based shunt sensor) E2E fault.";
CM_ SG_ 549 PCM_bInvldSnsrI1Mon "Error flag indicating current sensor 1 invalidity fault.";
CM_ SG_ 549 PCM_bInvldSnsrI2Mon "Error flag indicating current sensor 2 invalidity fault.";
CM_ SG_ 549 FRMo_bErrSopcLvl3Mon "Error flag indicating Level 3 switch-off path test fault.";
CM_ SG_ 549 BMS_FRMo_Reserved_1 "Fault monitor signal";
CM_ SG_ 549 BMS_FRMo_Reserved_2 "Fault monitor signal";
CM_ SG_ 549 BMS_FRMo_Reserved_3 "Fault monitor signal";
CM_ SG_ 549 BMS_FRMo_Reserved_4 "Fault monitor signal";
CM_ SG_ 549 BMS_FRMo_Reserved_5 "Fault monitor signal";
CM_ SG_ 293 Checksum_0x125 "Checksum";
CM_ SG_ 293 Rolling_Counter_0x125 "Rolling Counter";
CM_ SG_ 293 BMS_AllowDischgCurr "continuous maximum allowable discharge current of battery";
CM_ SG_ 293 BMS_AllowDischgCurrPeak "Peak maximum allowable discharge current of battery";
CM_ SG_ 885 Checksum_0x375 "Checksum";
CM_ SG_ 885 Rolling_Counter_0x375 "Rolling Counter";
CM_ SG_ 885 BMS_MainPosRelay_ERR "Main Position Relay Error";
CM_ SG_ 885 BMS_MainPosRelay_STS "Main Positive Relay Status";
CM_ SG_ 885 BMS_PreChgRelay_ERR "Precahrge relay is not working properly";
CM_ SG_ 885 BMS_PreChgRelay_STS "PreCharge Relay Status";
CM_ SG_ 885 BMS_TotalNegRelay_STS "Main Negative Relay Status";
CM_ SG_ 885 BMS_TotalNegRelay_ERR "Main Negative Relay Error";
CM_ SG_ 517 Checksum_0x205 "Checksum";
CM_ SG_ 517 Rolling_Counter_0x205 "Rolling Counter";
CM_ SG_ 517 BMS_MaxCellVol "Max Cell Voltage";
CM_ SG_ 517 BMS_CellNumMaxCellVol "Cell Number of Max Cell Voltage";
CM_ SG_ 517 BMS_MinCellVol "Min Cell Voltage";
CM_ SG_ 517 BMS_CellNumMinCellVol "Cell Number of Min Cell Voltage";
CM_ SG_ 581 Checksum_0x245 "Checksum";
CM_ SG_ 581 Rolling_Counter_0x245 "Rolling Counter";
CM_ SG_ 581 BMS_PackTemp "Pack Temperature";
CM_ SG_ 581 BMS_MaxMinDiffCellTemp "max and min cell temperature differences";
CM_ SG_ 581 BMS_MaxCellTemp "Max Cell Temperature";
CM_ SG_ 581 BMS_MinCellTemp "Min Cell Temperature";
CM_ SG_ 581 BMS_ProbeNumMaxCellTemp "Probe Number of Max Cell Temperature";
CM_ SG_ 581 BMS_ProbeNumMinCellTemp "Probe Number of Min Cell Temperature";
CM_ SG_ 773 Checksum_0x305 "Checksum";
CM_ SG_ 773 Rolling_Counter_0x305 "Rolling Counter";
CM_ SG_ 773 BMS_VCU_Insulation_Mon_Sts "Feedback for the Insulation Monitoring signal";
CM_ SG_ 773 BMS_PackInsuRes "Minimum value of BCU_PosInsuRes and BCU_NegInsuRes";
CM_ SG_ 1171 BMS_DischargeCurrent_Limited "Battery Discharge current limited due to BMS-MHU authentication failure.";
CM_ SG_ 1171 BMS_Warning_Flag_Reserved_07 "Warning signal";
CM_ SG_ 1171 BMS_Warning_Flag_Reserved_11 "Warning signal";
CM_ SG_ 1171 BMS_Warning_Flag_Reserved_10 "Warning signal";
CM_ SG_ 1171 BMS_Warning_Flag_Reserved_09 "Warning signal";
CM_ SG_ 1171 BMS_Warning_Flag_Reserved_13 "Warning signal";
CM_ SG_ 1171 BMS_Warning_Flag_Reserved_12 "Warning signal";
CM_ SG_ 1171 BMS_Warning_Flag_Reserved_06 "Warning signal";
CM_ SG_ 1171 BMS_Warning_Flag_Reserved_05 "Warning signal";
CM_ SG_ 1171 BMS_Warning_Flag_Reserved_04 "Warning signal";
CM_ SG_ 1171 BMS_MalfunctionSts "Malfunction status of battery for MHU display";
CM_ SG_ 1171 BMS_LowBattery "Low Battery Warning";
CM_ SG_ 1171 BMS_BatteryReplacement "Separate signal to indicate the battery replacement information(Battery replacement MHU)";
CM_ SG_ 1171 BMS_PackTempSts "Pack temperature warning";
CM_ SG_ 1171 BMS_ThermalRunaway "Thermalrunaway";
CM_ SG_ 1171 Rolling_Counter_0x493 "Rolling Counter";
CM_ SG_ 1171 Checksum_0x493 "Checksum";
CM_ SG_ 550 BMS_QMMo_Reserved_9 "QM fault monitoring signals";
CM_ SG_ 550 BMS_QMMo_Reserved_8 "QM fault monitoring signals";
CM_ SG_ 550 BMS_QMMo_Reserved_7 "QM fault monitoring signals";
CM_ SG_ 550 BMS_QMMo_Reserved_6 "QM fault monitoring signals";
CM_ SG_ 550 BMS_QMMo_Reserved_5 "QM fault monitoring signals";
CM_ SG_ 550 BMS_QMMo_Reserved_4 "QM fault monitoring signals";
CM_ SG_ 550 BMS_QMMo_Reserved_3 "QM fault monitoring signals";
CM_ SG_ 550 BMS_QMMo_Reserved_2 "QM fault monitoring signals";
CM_ SG_ 550 BMS_QMMo_Reserved_11 "QM fault monitoring signals";
CM_ SG_ 550 BMS_QMMo_Reserved_10 "QM fault monitoring signals";
CM_ SG_ 550 BMS_QMMo_Reserved_1 "QM fault monitoring signals";
CM_ SG_ 550 BMS_QMMo_Reserved_0 "QM fault monitoring signals";
CM_ SG_ 550 Rolling_Counter_0x226 "Rolling Counter";
CM_ SG_ 550 Checksum_0x226 "Checksum";
CM_ SG_ 1109 Checksum_0x455 "Checksum";
CM_ SG_ 1109 Rolling_Counter_0x455 "Rolling Counter";
CM_ SG_ 1109 BMS_PackInsu_ERR "Insulation check lines have problems, short to ground or short to bat";
CM_ SG_ 1109 BMS_CellVoltDiff_ERR "max and min cell voltage difference is too large";
CM_ SG_ 1109 BMS_PackOverCurr_ERR "When the over current is detected during charging and discharging for the given period of time, then the BMS_Packovercurr_err will set";
CM_ SG_ 1109 BMS_HVIL_Err "High Voltage Interlock loop circuit error";
CM_ SG_ 1109 BMS_CellHighVol_ERR "Over voltage of the cell is detected";
CM_ SG_ 1109 BMS_CellLowVol_ERR "under voltage of the cell is detected";
CM_ SG_ 1109 BMS_PackLowVol_ERR "Pack voltage is lower than the permittable values";
CM_ SG_ 1109 BMS_PackHighVol_ERR "Pack voltage is higher than the permittable values";
CM_ SG_ 1109 BMS_ProbeHighTemp_ERR "Over temperature of the cell is detected";
CM_ SG_ 1109 BMS_ProbeTempDiff_ERR "The difference in temperture between max and min is beyound the permissable limit";
CM_ SG_ 1109 BMS_FuseStatus_ERR "Fuse and Pyro fuse blowup status";
CM_ SG_ 1109 BMS_ProbeLowTemp_ERR "Under Temperature of the cell is detected";
CM_ SG_ 1504 BMS_Voltage_FrameNumber "BMS Voltage FrameNumber";
CM_ SG_ 1504 BMS_Voltage_Value1 "BMS Voltage Value1";
CM_ SG_ 1504 BMS_Voltage_Value2 "BMS Voltage Value2";
CM_ SG_ 1504 BMS_Voltage_Value3 "BMS Voltage Value3";
CM_ SG_ 1504 softwore_version "Current Raw wheel speed information valid flag of rear left wheel.";
CM_ SG_ 1505 BMS_Temp_FrameNumber "BMS Temperature FrameNumber";
CM_ SG_ 1505 BMS_Temp_Value1 "BMS Temperature Value1";
CM_ SG_ 1505 BMS_Temp_Value2 "BMS Temperature Value2";
CM_ SG_ 1505 BMS_Temp_Value3 "BMS Temperature Value3";
CM_ SG_ 1505 BMS_Temp_Value4 "BMS Temperature Value4";
CM_ SG_ 1505 BMS_Temp_Value5 "BMS Temperature Value5";
CM_ SG_ 1505 BMS_Temp_Value6 "BMS Temperature Value6";
CM_ SG_ 1505 BMS_Temp_Value7 "BMS Temperature Value7";
CM_ SG_ 1506 BMS_Test_Runaway "BMS Test Runaway";
CM_ SG_ 1506 BMS_Test_shunt_Temp "BMS Test shunt Temperature";
CM_ SG_ 1506 BMS_Test_V4_Volt "BMS Test V4 Volt";
CM_ SG_ 1506 BMS_Test_L2ErrNum "BMS Test L2ErrNum";
CM_ SG_ 1507 Error_Information "Error Information";
CM_ SG_ 1507 HVIL_HS_Volt "HVIL HS Volt";
CM_ SG_ 1507 HVIL_LS_Volt "HVIL LS Volt";
CM_ SG_ 1507 FCHVIL_HS_Volt "FCHVIL HS Volt";
CM_ SG_ 1507 FCHVIL_LS_Volt "FCHVIL LS Volt";
CM_ SG_ 1507 HVIL_HS_Inv "HVIL HS Inv";
CM_ SG_ 1507 HVIL_LS_Inv "HVIL LS Inv";
CM_ SG_ 1507 FCHVIL_HS_Inv "FCHVIL HS Inv";
CM_ SG_ 1507 FCHVIL_LS_Inv "FCHVIL LS Inv";
CM_ SG_ 1507 HVIL_Fault "HVIL Fault";
CM_ SG_ 1507 HallError "Hall Error";
CM_ SG_ 523 Checksum_0x20B "Checksum";
CM_ SG_ 523 Rolling_Counter_0x20B "Rolling counter";
CM_ SG_ 523 DCDC_Sys_STS "DCDC System Status(Self-test after DCDC wake-up)";
CM_ SG_ 523 DCDC_Voltage_Input "DCDC Input Voltage";
CM_ SG_ 523 DCDC_Current_Input "DCDC Input Current";
CM_ SG_ 523 DCDC_Voltage_Output "DCDC Output Voltage";
CM_ SG_ 523 DCDC_Current_Output "DCDC Output Current";
CM_ SG_ 523 DCDC_Output_STS "DCDC Output Status";
CM_ SG_ 523 DCDC_Temp "DCDC Work Temperature";
CM_ SG_ 854 Checksum_0x356 "Checksum";
CM_ SG_ 854 Rolling_Counter_0x356 "Rolling counter";
CM_ SG_ 854 OBC_WorkStatus "OBC working status";
CM_ SG_ 854 OBC_Sys_STS "OBC System Status";
CM_ SG_ 854 OBC_StartStatus "Output state of the charging machine";
CM_ SG_ 854 OBC_ChargeConnetState "OBC Charge Connet State";
CM_ SG_ 870 Checksum_0x366 "Checksum";
CM_ SG_ 870 Rolling_Counter_0x366 "Rolling counter";
CM_ SG_ 870 CurrentLimit_reserved "Current Limit";
CM_ SG_ 870 OBC_CP_State_reserved "CP State";
CM_ SG_ 870 OBC_Charge_air_temp "Air temperature of OBC";
CM_ SG_ 870 OBC_Temp_Reserved "Control board Temperature";
CM_ SG_ 646 Checksum_0x286 "Checksum";
CM_ SG_ 646 Rolling_Counter_0x286 "Rolling counter";
CM_ SG_ 646 OBC_OUT_DC_V "Output Voltage Value of DC High Voltage";
CM_ SG_ 646 OBC_OUT_DC_I "Output Current Value of DC Hight Voltage";
CM_ SG_ 646 OBC_DCCharge_line_V "The voltage between positive and negative DC fast charging high voltage lines";
CM_ SG_ 630 Checksum_0x276 "Checksum";
CM_ SG_ 630 Rolling_Counter_0x276 "Rolling counter";
CM_ SG_ 630 OBC_Input_U "OBC input voltage";
CM_ SG_ 630 OBC_IN_Main_V_Reserved "The Input Voltage value of OBC (Reserved)";
CM_ SG_ 630 OBC_IN_Main_I_Reserved "The Input Current value of OBC (Reserved)";
CM_ SG_ 662 Checksum_0x296 "Checksum";
CM_ SG_ 662 Rolling_Counter_0x296 "Rolling counter";
CM_ SG_ 662 OBC_MaxOutputChgU "Maximum output voltage of OBC";
CM_ SG_ 662 OBC_MaxOutputChgI "Maximum output current of OBC";
CM_ SG_ 662 OBC_MaxOutputPwr "Maximum output power of OBC";
CM_ SG_ 1142 OBC_FailGrade_ERR "OBC Fault Status";
CM_ SG_ 1142 OBC_ErrorFlag_Reserved "Error Flag (Reserved)";
CM_ SG_ 1142 OBC_Hardware_ERR "Hardware Fault";
CM_ SG_ 1142 OBC_OTemp_ERR "Charger Over Temperature Fault";
CM_ SG_ 1142 OBC_OCofOut_ERR_Reserved "Output Over Current Fault (Reserved)";
CM_ SG_ 1142 OBC_SlwChgSktOTemp_ERR_Reserved "OBC Slow Charger Socket Over Temp error";
CM_ SG_ 1142 OBC_CANcomoverT_ERR "CAN Communication Over Time Fault(LossBMSNote)";
CM_ SG_ 1142 OBC_UVofIn_ERR_Reserved "Input Under Voltage Fault  (Reserved)";
CM_ SG_ 1142 OBC_OVofIn_ERR_Reserved "Input Over Voltage Fault (Reserved)";
CM_ SG_ 1142 OBC_OVofPFC_ERR_Reserved "PFC Over Voltage Fault  (Reserved)";
CM_ SG_ 1142 OBC_UVofPFC_ERR_Reserved "PFC Under Voltage Fault (Reserved)";
CM_ SG_ 1142 OBC_UVofOut_ERR "Output Under Voltage Fault";
CM_ SG_ 1142 OBC_OVofOut_ERR "Output Over Voltage Fault";
CM_ SG_ 840 EDS_bus_Volt_FWD "Bus voltage of current EDS";
CM_ SG_ 840 EDS_bus_Curr_FWD "Bus current of current EDS";
CM_ SG_ 840 EDS_MtrNumb_FWD "Motor Number";
CM_ SG_ 840 EDS_DriveMtrNmb_FWD "DriveMotorNumber";
CM_ SG_ 840 EDS_HVIL_STS_FWD "FWD EDS HighVoltage state";
CM_ SG_ 504 Checksum_0x1F8 "Check sum";
CM_ SG_ 504 Rolling_Counter_0x1F8 "Rolling counter";
CM_ SG_ 504 EDS_output_trq_FR "Actual output torque of current EDS";
CM_ SG_ 504 EDS_output_trqValid_FR "Indicate the valid flag of current motor torque";
CM_ SG_ 504 EDS_Spd_FR "current motor speed";
CM_ SG_ 504 EDS_SpdValid_FR "Indicate the valid flag of current motor speed";
CM_ SG_ 504 EDS_MotorDriveSts_FR "The drive state of EDS";
CM_ SG_ 504 EDS_Work_STS_FR "EDS Work status";
CM_ SG_ 504 EDS_powoff_req_FR "If there is a serious failure in the running process of EDS, the high voltage of VCU will be requested";
CM_ SG_ 1080 EDS_FailNum_ERR_FWD "FaultNumber";
CM_ SG_ 1080 EDS_FailGrade_ERR_FWD "Fault level of EDS system";
CM_ SG_ 1080 EDS_MotOverTempAlarm_FWD "Motor over temperture alarm";
CM_ SG_ 1080 EDS_MotOverTempFault_FWD "Motor over temperture fault";
CM_ SG_ 1080 EDS_MotTempSenFault_FWD "Motor temperature sensor fault";
CM_ SG_ 1080 EDS_EDSOverTempUFault_FWD "EDS Upha Over temperature fault";
CM_ SG_ 1080 EDS_EDSOverTempVFault_FWD "EDS Vpha Over temperature fault";
CM_ SG_ 1080 EDS_EDSOverTempWFault_FWD "EDS Wpha Over temperature fault";
CM_ SG_ 1080 EDS_EDSOverTempAlarm_FWD "EDS over temperture alarm";
CM_ SG_ 1080 EDS_TCoolantOvHi_FWD "Alarm  when Cooling water temperature is too high";
CM_ SG_ 1080 EDS_EDSTempCmpAlarm_FWD "EDS temp offset checkout alarm";
CM_ SG_ 1080 EDS_EDSPhaOvCurentHWFault_FWD "Phase Current Overcurrent hardware fault";
CM_ SG_ 1080 EDS_EDSphaOffCalFault_FWD "EDS phase Current Offset Calibration Fault";
CM_ SG_ 1080 EDS_EDSOverIdcLnkAlarm_FWD "EDS IdcLnk Overcurrent alarm";
CM_ SG_ 1080 EDS_EDSHVOverVoltageAlarm_FWD "EDS high voltage over voltage alarm";
CM_ SG_ 1080 EDS_EDSHVOverVoltageFault_FWD "EDS high voltage over voltage fault";
CM_ SG_ 1080 EDS_EDSHVUnderVoltageAlarm_FWD "EDS high voltage under voltage alarm";
CM_ SG_ 1080 EDS_EDSHVUnderVoltageFault_FWD "EDS high voltage under voltage fault";
CM_ SG_ 1080 EDS_RunToDischaErr_FWD "Stateflow fail to enter avtive discharge";
CM_ SG_ 1080 EDS_12VOverVoltageAlarm_FWD "12V Power over voltage alarm";
CM_ SG_ 1080 EDS_12VUnderVoltageAlarm_FWD "12V Power under voltage alarm";
CM_ SG_ 1080 EDS_MotOverAlarm_FWD "Motor overspeed fault alarm";
CM_ SG_ 1080 EDS_MotOverFault_FWD "Motor overspeed fault fault";
CM_ SG_ 1080 EDS_iDcLnkOvCLimFail_FWD "Bus current over-current fault";
CM_ SG_ 1080 EDS_MotBlockedFault_FWD "Motor blocked fault";
CM_ SG_ 1080 EDS_RSLErr_FWD "Rotary transformer signal fault";
CM_ SG_ 1080 EDS_MotTrqLimFault_FWD "Motor torque limit fault";
CM_ SG_ 1080 EDS_ResolverOffsetAngle_FWD "EDS offset angle check fault";
CM_ SG_ 1080 EDS_EDSDisChgFault_FWD "EDS Active discharge fault";
CM_ SG_ 1080 EDS_IGBTFault_FWD "IGBT fault";
CM_ SG_ 1080 EDS_CANBusoffFault_FWD "CAN busoff fault";
CM_ SG_ 1080 EDS_TDrvBoardOvHiWarn_FWD "Alarm when drive plate temperature is too high";
CM_ SG_ 1080 EDS_TIGBTOvHiFault_FWD "IGBT junction temperature over temperature fault";
CM_ SG_ 1080 EDS_TIGBTOvHiWarn_FWD "IGBT junction temperature over temperature alarm";
CM_ SG_ 1080 EDS_IOHWABSampFail_FWD "Chip control power sampling failure";
CM_ SG_ 1080 EDS_EDSOpenFault_FWD "EDS open plate fault";
CM_ SG_ 1080 EDS_MotorOpenFault_FWD "Motor open plate fault";
CM_ SG_ 1080 EDS_EmacBlkdWarn_FWD "Motor locked rotor warning";
CM_ SG_ 1080 EDS_VerMatchFailureErr_FWD "EDS Software Version match Failure Fault";
CM_ SG_ 1080 EDS_DiashCirNoPsblErr_FWD "Unable to active short circuit fault";
CM_ SG_ 1080 EDS_OperOutdRngErr_FWD "Short circuit over temperature operation diagnosis";
CM_ SG_ 1080 EDS_PhaseLossFaultErr_FWD "Missing phase fault";
CM_ SG_ 1080 EDS_CPLDFault_FWD "CPLD Fault";
CM_ SG_ 1080 EDS_CPLDFaultBaseSpd_FWD "CPLD enter ASC fault based on motor speed";
CM_ SG_ 1080 EDS_IOHWABNen33Fail_FWD "Feedback NEN33 fault";
CM_ SG_ 1080 EDS_HvMcuSlightFault_RWD "HvMcu Slight fault";
CM_ SG_ 1080 EDS_HvMcuSevFault_FWD "HvMcu serious fault";
CM_ SG_ 1080 EDS_EDSPhaSampHWFault_FWD "UVW phase current monitoring sampling hard wire fault";
CM_ SG_ 1080 EDS_IsOvHiErr_FWD "Phase current overcurrent diagnosis";
CM_ SG_ 1080 EDS_CanRollingCounterErr_FWD "Receive count error";
CM_ SG_ 1080 EDS_CanTimeoutErr_FWD "Receive timeout error";
CM_ SG_ 1080 EDS_CrashFault_FWD "Crash signal fault";
CM_ SG_ 537 Checksum_0x219 "Checksum";
CM_ SG_ 537 Rolling_Counter_0x219 "Rolling Counter";
CM_ SG_ 537 VCU_VehicleDischargePower "Discharge Power";
CM_ SG_ 537 VCU_VehicleChargePower "Charge Power";
CM_ SG_ 537 VCU_ChargeAllow "The flag of VCU allows BMS charging";
CM_ SG_ 544 Checksum_0x220 "Checksum";
CM_ SG_ 544 Rolling_Counter_0x220 "Rolling Counter";
CM_ SG_ 544 VCU_BMS_PTCOnOff_Sts "VCU sends the status of the PTC Heater(for C-Car)";
CM_ SG_ 544 VCU_BMS_ValveOnOff_Sts "VCU sends the status of the valve";
CM_ SG_ 544 VCU_BMS_PumpFB "VCU sends the PUMP feedback";
CM_ SG_ 757 VCU_Charge_Control "Charging allow or forbid";
CM_ SG_ 757 VCU_AC_chargeSock_temp1 "AC Charge SOCK temp";
CM_ SG_ 757 VCU_DC_chargeSock_temp1 "DC charge SOCK temp1";
CM_ SG_ 757 VCU_DC_chargeSock_temp2 "DC charge SOCK temp2";
CM_ SG_ 937 VCU_PTC_RelaySts "PTC Relayopen or close state";
CM_ SG_ 937 VCU_EACEnbReq "The command of compressor,AC enable signal";
CM_ SG_ 937 VCU_EACAllowedPower "EAC Allowed Power";
CM_ SG_ 937 VCU_EAC_CompSpdReq "Compressor Speed Request";
CM_ SG_ 937 VCU_DriveCoolWaterFlowRate "Actual drive cool water flow rate";
CM_ SG_ 937 VCU_DriveCoolInletWaterTemp "The temperature of inlet radiator";
CM_ SG_ 425 VCU_RegenLevel_Feed "VCU current Feedback Set power regenerative level";
CM_ SG_ 425 VCU_RBCSts "Regenerative Braking";
CM_ SG_ 425 VCU_RDCSts "Regenerative coasted";
CM_ SG_ 425 VCU_Veh_ERR "Vehicle System Error";
CM_ SG_ 425 VCU_DrvSys_ERR "DriveSystemError";
CM_ SG_ 425 VCU_PackSys_ERR "StoredEnergySystemError";
CM_ SG_ 425 VCU_TBOX_Veh_STS_Reserved "Vehicle Status";
CM_ SG_ 425 VCU_VehChg_STS "Vehicle Charge Status";
CM_ SG_ 425 VCU_BatterVoltage_Reserved "BetteryVoltage";
CM_ SG_ 425 VCU_BatteryVoltErr_Reserved "Indicate the generator is warning when Mechanical flag or Electrical flag is active (Reserved)（）";
CM_ SG_ 425 VCU_MotorCoolingCircuitErr_Reserved "Motor cooling loop failure state (Reserved)";
CM_ SG_ 425 VCU_PackCoolingCircuitErr_Reserved "Battery pack cooling loop failure state (Reserved)";
CM_ SG_ 425 VCU_VehicleHVStatus "Vehicle High voltage Ready State(VCU_VehicleHVStatus to be received by all modules,Used as a flash programming pre-condition (replacement for engine running)";
CM_ SG_ 425 VCU_InstantPowerConsump "Instant power consumption";
CM_ SG_ 425 VCU_AveragePowerConsump "Average power comsumption";
CM_ SG_ 425 VCU_BrakePedalSts "Brake Pedal Sts";
CM_ SG_ 992 Checksum_0x3E0 "Checksum";
CM_ SG_ 992 Rolling_Counter_0x3E0 "Rolling counter";
CM_ SG_ 992 VCU_RunningRange "Estimated running range ( at present )";
CM_ SG_ 992 VCU_MHU_Ack_ChgSche_stt "Status Enabled/ Disabled of Schedule Charging acknowledged by VCU base on request from MHU 0x403 MHU_ChargeScheduleSet.When this signal value = Enabled, VCU to follow 0x403 MHU_ChargingRequest = Start / Stop to start/ stop charging or stop charging when reach target SOC / battery full / chag.error.";
CM_ SG_ 992 VCU_MHU_GuestMode_sts "Feedback from VCU of Guest Mode ON/ OFF.Refer to Guest Mode definition document for more detail.";
CM_ SG_ 992 VCU_MHU_Ack_TargetSOC "Target SOC acknowledged by VCU base on request from MHU";
CM_ SG_ 992 VCU_ValetMode_sts "Status indicate valet mode is effected to VCU";
CM_ SG_ 992 VCU_ValetMode_MaxSpeedSts "Max speed setting of Valet mode";
CM_ SG_ 992 VCU_CreepDisable_stt "Feedback for Creep disable request";
CM_ SG_ 409 Checksum_0x199 "Checksum";
CM_ SG_ 409 Rolling_Counter_0x199 "Rolling Counter";
CM_ SG_ 409 VCU_VehFailGrade_ERR "VehicleFaultLevel";
CM_ SG_ 409 VCU_BMS_HVOnOff_REQ "BMS decides whether to close or disconnect the primary and negative relays by judging this command";
CM_ SG_ 409 VCU_Vehicle_Mode "Vehicle Mode of EV";
CM_ SG_ 792 EAC_CompElecCurrV "Compressor Electrical Current Validity";
CM_ SG_ 792 EAC_CompStat "Compressor status";
CM_ SG_ 792 EAC_CompElecPwrV "Compressor Electrical Power Validity";
CM_ SG_ 792 EAC_CompSpdIncrReq "Compressor Speed Increasing Request";
CM_ SG_ 792 EAC_CompSpdV "Compressor Actual Speed Validity";
CM_ SG_ 792 EAC_CompElecPwr "Compressor Electrical Power";
CM_ SG_ 792 EAC_CompSpd "Compressor Actual Speed";
CM_ SG_ 792 EAC_CompElecCurr "Compressor Electrical Current";
CM_ SG_ 792 EAC_CompFltStat "Compressor Fault Status";
CM_ SG_ 524 Checksum_0x20C "Checksum";
CM_ SG_ 524 Rolling_Counter_0x20C "Rolling_Counter";
CM_ SG_ 524 IPC_ODO "odograph";
CM_ SG_ 703 IPC_TripA "Set Trip A";
CM_ SG_ 703 IPC_AverageSpeedTripA "Average Speed of TripA";
CM_ SG_ 703 IPC_AverageConsumptionTripA "Average Consumption of TripA";
CM_ SG_ 703 IPC_ParkBrakeSts "Park Brake Status";
CM_ SG_ 703 IPC_VehSpd "Current Displayed Longitudinal Vehicle Speed";
CM_ SG_ 1087 IPC_Sec "Represents the current second.60 - 63 = Invalid";
CM_ SG_ 1087 IPC_Min "Represents the current minute. 60 - 63 = Invalid";
CM_ SG_ 1087 IPC_Hour "Represents the current hour, 24 - 30 = not used";
CM_ SG_ 1087 IPC_Day "Represents the current dayInvalid value = 0";
CM_ SG_ 1087 IPC_Month "Represents the current month.0, 13 to 15 = Invalid";
CM_ SG_ 1087 IPC_Year "Represents the current year.";
CM_ SG_ 1087 IPC_SelfCheckStatus "Power on self check status";
CM_ SG_ 1074 Checksum_0x432 "Checksum";
CM_ SG_ 1074 Rolling_Counter_0x432 "Rolling_Counter";
CM_ SG_ 1074 MHU_FOTA_State "FOTA global status";
CM_ SG_ 1074 MHU_FOTA_Error_Code "FOTA Error Code";
CM_ SG_ 1027 Checksum_0x403 "Checksum";
CM_ SG_ 1027 Rolling_Counter_0x403 "Rolling_Counter";
CM_ SG_ 1027 MHU_SET_TCS_OnOff "Change TCS mode ON/OFF";
CM_ SG_ 1027 MHU_SET_DrivingModeSwitch "Change vehicle driving mode";
CM_ SG_ 1027 MHU_SET_RegenLevel "Set power regenerative level";
CM_ SG_ 1027 MHU_VCU_CreepDisable_stt "Request for VCU to disable creep function";
CM_ SG_ 1027 MHU_ChargeSetTargetSOC "Request for VCU to set target HV SOC";
CM_ SG_ 1027 MHU_HVACTurnON "Turning ON HVAC remotely";
CM_ SG_ 1027 MHU_ChargeScheduleSet "Request for VCU to enable/disable Charging Scheduling";
CM_ SG_ 1027 MHU_ChargingRequest "Request for VCU to ON/OFF Charging when schedule is reached";
CM_ SG_ 1027 MHU_ValetMode_Activation "Activate Valet mode from MHU";
CM_ SG_ 1027 MHU_ValetMode_MaxSpeed "Setting of maximum allowable in valet mode";
CM_ SG_ 811 CCU_TemperatureGearSts "Temperature Gear Status";
CM_ SG_ 811 CCU_BlowMode_Sts "Blow Mode_Status";
CM_ SG_ 811 CCU_Circulation_Sts "CCU intake cycle state";
CM_ SG_ 811 CCU_AC_Req "Compressor request switch signal";
CM_ SG_ 811 CCU_AC_Sts "AC Status";
CM_ SG_ 811 CCU_BlowerLevelSts "Blower_Level";
CM_ SG_ 811 CCU_FrontDefrostSts "Defrost_Status";
CM_ SG_ 811 CCU_PTC_Req "CCU request VCU to enable or disable PTC";
CM_ SG_ 811 CCU_PTC_Temperature "PTC Temperature";
CM_ SG_ 811 CCU_CompSpdMEAS_Comp "Compressor speed signal";
CM_ SG_ 811 CCU_PollutionSts "Pollution mode state";
CM_ SG_ 811 CCU_ExternalTemperature "External Temperature";
CM_ SG_ 811 CCU_evaporator_Temperature "evaporator Temperature";
CM_ SG_ 811 CCU_ExternalTemperatureFailSts "External Temperature Fail Sts";
CM_ SG_ 929 BMS_MHU_Rand_Num_Byte_0 "Random number sent by BMS";
CM_ SG_ 929 BMS_MHU_Rand_Num_Byte_1 "Random number sent by BMS";
CM_ SG_ 929 BMS_MHU_Rand_Num_Byte_2 "Random number sent by BMS";
CM_ SG_ 929 BMS_MHU_Rand_Num_Byte_3 "Random number sent by BMS";
CM_ SG_ 929 BMS_MHU_Rand_Num_Byte_4 "Random number sent by BMS";
CM_ SG_ 929 BMS_MHU_Rand_Num_Byte_5 "Random number sent by BMS";
CM_ SG_ 929 BMS_MHU_Rand_Num_Byte_6 "Random number sent by BMS";
CM_ SG_ 929 BMS_MHU_Rand_Num_Byte_7 "Random number sent by BMS";
CM_ SG_ 930 MHU_BMS_Enc_Result_Byte_0 "MHU Encryption result";
CM_ SG_ 930 MHU_BMS_Enc_Result_Byte_1 "MHU Encryption result";
CM_ SG_ 930 MHU_BMS_Enc_Result_Byte_2 "MHU Encryption result";
CM_ SG_ 930 MHU_BMS_Enc_Result_Byte_3 "MHU Encryption result";
CM_ SG_ 930 MHU_BMS_Enc_Result_Byte_4 "MHU Encryption result";
CM_ SG_ 930 MHU_BMS_Enc_Result_Byte_5 "MHU Encryption result";
CM_ SG_ 930 MHU_BMS_Enc_Result_Byte_6 "MHU Encryption result";
CM_ SG_ 930 MHU_BMS_Enc_Result_Byte_7 "MHU Encryption result";
CM_ SG_ 274 Checksum_0x112 "Checksum";
CM_ SG_ 274 Rolling_Counter_0x112 "Rolling_Counter";
CM_ SG_ 274 STAT_Terminal "Represent the status of physical terminal(STAT_Terminal to be received by all modules,Required for DTC snapshots and for FOTA)";
CM_ SG_ 274 STAT_CL30s_L_Reserved "Status Clamp 30s Logical ON/OFF";
CM_ SG_ 266 Checksum_0x10a "Checksum";
CM_ SG_ 266 Rolling_Counter_0x10a "Rolling_Counter";
CM_ SG_ 266 BCM_LVTop_up "LV  battery top up requice signal";
CM_ SG_ 266 Ubatt_Reserved "Battery Voltage(UBatt to be received by all modules,Required for DTC snapshots)";
CM_ SG_ 133 Checksum_0x85 "Checksum";
CM_ SG_ 133 Rolling_Counter_0x85 "Rolling Counter";
CM_ SG_ 133 ACM_Crash_Sts "Crash status";
CM_ SG_ 133 ACM_Airbag_Deployment_Status "Signal to indicate if airbag/pretensioner/pyrofuse is deployed";
CM_ SG_ 133 ACM_Crash_Intensity "Indicate crash intensity level";
CM_ SG_ 133 ACM_Front_Crash "Output information for direction of crash";
CM_ SG_ 133 ACM_DriverSide_Crash "Output information for direction of crash";
CM_ SG_ 133 ACM_PassSide_Crash "Output information for direction of crash";
CM_ SG_ 133 ACM_Rear_Crash "Output information for direction of crash";
CM_ SG_ 133 ACM_Rollover_Crash "Output information for direction of crash";
CM_ SG_ 834 Checksum_0x342 "Check sum";
CM_ SG_ 834 Rolling_Counter_0x342 "Rolling Counter";
CM_ SG_ 834 ABS_LRWhlSpdRaw "Current Raw wheel speed information of rear left wheel.";
CM_ SG_ 834 ABS_LRWhlSpdRawValid "Current Raw wheel speed information valid flag of rear left wheel.";
CM_ SG_ 834 ABS_RRWhlSpdRaw "Current Raw wheel speed information of rear right wheel.,";
CM_ SG_ 834 ABS_RRWhlSpdRawValid "Current Raw wheel speed information valid flag of rear right wheel";
CM_ SG_ 834 ABS_VehSpd "Current Longitudinal Vehicle Speed";
CM_ SG_ 834 ABS_VehSpdValid "Speed Valid Flag";
CM_ SG_ 1299 BMS_sourceID "source ID";
CM_ SG_ 1299 BMS_CBV "CBV";
CM_ SG_ 1299 BMS_Data0 "Data0";
CM_ SG_ 1299 BMS_Data1 "Data1";
CM_ SG_ 1299 BMS_Data2 "Data2";
CM_ SG_ 1299 BMS_Data3 "Data3";
CM_ SG_ 1299 BMS_Data4 "Data4";
CM_ SG_ 1299 BMS_Data5 "Data5";
CM_ SG_ 1324 VCU_sourceID "source ID";
CM_ SG_ 1324 VCU_CBV "CBV";
CM_ SG_ 1324 VCU_Data0 "Data0";
CM_ SG_ 1324 VCU_Data1 "Data1";
CM_ SG_ 1324 VCU_Data2 "Data2";
CM_ SG_ 1324 VCU_Data3 "Data3";
CM_ SG_ 1324 VCU_Data4 "Data4";
CM_ SG_ 1324 VCU_Data5 "Data5";
CM_ SG_ 1341 PDU_DCDC_sourceID "source ID";
CM_ SG_ 1341 PDU_DCDC_CBV "CBV";
CM_ SG_ 1341 PDU_DCDC_Data0 "Data0";
CM_ SG_ 1341 PDU_DCDC_Data1 "Data1";
CM_ SG_ 1341 PDU_DCDC_Data2 "Data2";
CM_ SG_ 1341 PDU_DCDC_Data3 "Data3";
CM_ SG_ 1341 PDU_DCDC_Data4 "Data4";
CM_ SG_ 1341 PDU_DCDC_Data5 "Data5";
CM_ SG_ 1307 EDS_sourceID "source ID";
CM_ SG_ 1307 EDS_CBV "CBV";
CM_ SG_ 1307 EDS_Data0 "Data0";
CM_ SG_ 1307 EDS_Data1 "Data1";
CM_ SG_ 1307 EDS_Data2 "Data2";
CM_ SG_ 1307 EDS_Data3 "Data3";
CM_ SG_ 1307 EDS_Data4 "Data4";
CM_ SG_ 1307 EDS_Data5 "Data5";
CM_ SG_ 1311 EVCC_sourceID "source ID";
CM_ SG_ 1311 EVCC_CBV "CBV";
CM_ SG_ 1311 EVCC_Data0 "Data0";
CM_ SG_ 1311 EVCC_Data1 "Data1";
CM_ SG_ 1311 EVCC_Data2 "Data2";
CM_ SG_ 1311 EVCC_Data3 "Data3";
CM_ SG_ 1311 EVCC_Data4 "Data4";
CM_ SG_ 1311 EVCC_Data5 "Data5";
CM_ SG_ 1282 GW_sourceID "source ID";
CM_ SG_ 1282 GW_CBV "CBV";
CM_ SG_ 1282 GW_Data0 "Data0";
CM_ SG_ 1282 GW_Data1 "Data1";
CM_ SG_ 1282 GW_Data2 "Data2";
CM_ SG_ 1282 GW_Data3 "Data3";
CM_ SG_ 1282 GW_Data4 "Data4";
CM_ SG_ 1282 GW_Data5 "Data5";
CM_ SG_ 1683 BMS_DiagReqData0 "Data0";
CM_ SG_ 1683 BMS_DiagReqData1 "Data1";
CM_ SG_ 1683 BMS_DiagReqData2 "Data2";
CM_ SG_ 1683 BMS_DiagReqData3 "Data3";
CM_ SG_ 1683 BMS_DiagReqData4 "Data4";
CM_ SG_ 1683 BMS_DiagReqData5 "Data5";
CM_ SG_ 1683 BMS_DiagReqData6 "Data6";
CM_ SG_ 1683 BMS_DiagReqData7 "Data7";
CM_ SG_ 1555 BMS_DiagRespData0 "Data0";
CM_ SG_ 1555 BMS_DiagRespData1 "Data1";
CM_ SG_ 1555 BMS_DiagRespData2 "Data2";
CM_ SG_ 1555 BMS_DiagRespData3 "Data3";
CM_ SG_ 1555 BMS_DiagRespData4 "Data4";
CM_ SG_ 1555 BMS_DiagRespData5 "Data5";
CM_ SG_ 1555 BMS_DiagRespData6 "Data6";
CM_ SG_ 1555 BMS_DiagRespData7 "Data7";
CM_ SG_ 1791 GW_DiagFunctionalAddressingData0 "Data0";
CM_ SG_ 1791 GW_DiagFunctionalAddressingData1 "Data1";
CM_ SG_ 1791 GW_DiagFunctionalAddressingData2 "Data2";
CM_ SG_ 1791 GW_DiagFunctionalAddressingData3 "Data3";
CM_ SG_ 1791 GW_DiagFunctionalAddressingData4 "Data4";
CM_ SG_ 1791 GW_DiagFunctionalAddressingData5 "Data5";
CM_ SG_ 1791 GW_DiagFunctionalAddressingData6 "Data6";
CM_ SG_ 1791 GW_DiagFunctionalAddressingData7 "Data7";
BA_DEF_ BO_ "DiagRequest" ENUM "No","Yes";
BA_DEF_ BO_ "DiagResponse" ENUM "No","Yes";
BA_DEF_ BO_ "DiagState" ENUM "No","Yes";
BA_DEF_ BO_ "GenMsgCycleTime" INT 0 65535;
BA_DEF_ BO_ "GenMsgCycleTimeFast" INT 0 65535;
BA_DEF_ BO_ "GenMsgDelayTime" INT 0 65535;
BA_DEF_ BO_ "GenMsgILSupport" ENUM "No","Yes";
BA_DEF_ BO_ "GenMsgNrOfRepetition" INT 0 65535;
BA_DEF_ BO_ "GenMsgSendType" ENUM  "Cycle","Event","IfActive","CE","CA";
BA_DEF_ BO_ "NmAsrMessage" ENUM "No","Yes";
BA_DEF_ BO_ "NmMessage" ENUM "No","Yes";
BA_DEF_ SG_ "GenSigSendType" ENUM  "Cycle","OnWrite","OnWriteWithRepetition","OnChange","OnChangeWithRepetition","IfActive","IfActiveWithRepetition";
BA_DEF_ SG_ "GenSigStartValue" INT 0 2147483647;
BA_DEF_ SG_ "GenSigInvalidValue" INT 0 2147483647;
BA_DEF_ SG_ "GenSigInactiveValue" INT 0 2147483647;
BA_DEF_ BU_ "ILUsed" ENUM  "No","Yes";
BA_DEF_ BU_ "NmAsrCanMsgReducedTime" INT 320 640;
BA_DEF_ BU_ "NmAsrNode" ENUM  "No","Yes";
BA_DEF_  "Baudrate" INT 0 1000000;
BA_DEF_  "BusType" STRING;
BA_DEF_  "Manufacturer" STRING;
BA_DEF_  "NmAsrBaseAddress" HEX 0 2047;
BA_DEF_  "NmAsrCanMsgCycleTime" INT 0 65535;
BA_DEF_  "NmAsrMessageCount" INT 1 256;
BA_DEF_  "NmAsrRepeatMessageTime" INT 0 65535;
BA_DEF_  "NmAsrTimeoutTime" INT 0 65535;
BA_DEF_  "NmAsrWaitBusSleepTime" INT 0 65535;
BA_DEF_  "NmType" STRING;
BA_DEF_DEF_ "Baudrate" 500000;
BA_DEF_DEF_ "BusType" "CAN";
BA_DEF_DEF_ "DiagRequest" "No";
BA_DEF_DEF_ "DiagResponse" "No";
BA_DEF_DEF_ "DiagState" "No";
BA_DEF_DEF_ "GenMsgCycleTime" 0;
BA_DEF_DEF_ "GenMsgCycleTimeFast" 0;
BA_DEF_DEF_ "GenMsgDelayTime" 0;
BA_DEF_DEF_ "GenMsgILSupport" "Yes";
BA_DEF_DEF_ "GenMsgNrOfRepetition" 0;
BA_DEF_DEF_ "GenMsgSendType" "NoMsgSendType";
BA_DEF_DEF_ "GenSigSendType" "NoSigSendType";
BA_DEF_DEF_ "GenSigStartValue" 0;
BA_DEF_DEF_  "GenSigInvalidValue" 0;
BA_DEF_DEF_ "GenSigInactiveValue" 0;
BA_DEF_DEF_ "ILUsed" "Yes";
BA_DEF_DEF_ "Manufacturer" "Launch";
BA_DEF_DEF_ "NmAsrBaseAddress" 1280;
BA_DEF_DEF_ "NmAsrCanMsgCycleTime" 640;
BA_DEF_DEF_ "NmAsrCanMsgReducedTime" 320;
BA_DEF_DEF_ "NmAsrMessage" "No";
BA_DEF_DEF_ "NmAsrMessageCount" 128;
BA_DEF_DEF_ "NmAsrNode" "No";
BA_DEF_DEF_ "NmAsrRepeatMessageTime" 3200;
BA_DEF_DEF_ "NmAsrTimeoutTime" 2000;
BA_DEF_DEF_ "NmAsrWaitBusSleepTime" 1500;
BA_DEF_DEF_ "NmMessage" "No";
BA_DEF_DEF_ "NmType" "NmAsr";

BA_ "NmAsrNode" BU_ BMS 1;
BA_ "GenMsgSendType" BO_ 673 0;
BA_ "GenMsgCycleTime" BO_ 673 100;
BA_ "GenMsgSendType" BO_ 682 0;
BA_ "GenMsgCycleTime" BO_ 682 100;
BA_ "GenMsgSendType" BO_ 683 0;
BA_ "GenMsgCycleTime" BO_ 683 100;
BA_ "GenMsgSendType" BO_ 536 0;
BA_ "GenMsgCycleTime" BO_ 536 50;
BA_ "GenMsgSendType" BO_ 534 0;
BA_ "GenMsgCycleTime" BO_ 534 50;
BA_ "GenMsgSendType" BO_ 294 0;
BA_ "GenMsgCycleTime" BO_ 294 20;
BA_ "GenMsgSendType" BO_ 521 0;
BA_ "GenMsgCycleTime" BO_ 521 20;
BA_ "GenMsgSendType" BO_ 585 0;
BA_ "GenMsgCycleTime" BO_ 585 100;
BA_ "GenMsgSendType" BO_ 584 0;
BA_ "GenMsgCycleTime" BO_ 584 100;
BA_ "GenMsgSendType" BO_ 518 0;
BA_ "GenMsgCycleTime" BO_ 518 20;
BA_ "GenMsgSendType" BO_ 818 0;
BA_ "GenMsgCycleTime" BO_ 818 100;
BA_ "GenMsgSendType" BO_ 816 0;
BA_ "GenMsgCycleTime" BO_ 816 100;
BA_ "GenMsgSendType" BO_ 374 0;
BA_ "GenMsgCycleTime" BO_ 374 50;
BA_ "GenMsgSendType" BO_ 375 0;
BA_ "GenMsgCycleTime" BO_ 375 50;
BA_ "GenMsgSendType" BO_ 372 0;
BA_ "GenMsgCycleTime" BO_ 372 20;
BA_ "GenMsgSendType" BO_ 533 0;
BA_ "GenMsgCycleTime" BO_ 533 50;
BA_ "GenMsgSendType" BO_ 931 1;
BA_ "GenMsgNrOfRepetition" BO_ 931 3;
BA_ "GenMsgDelayTime" BO_ 931 10;
BA_ "GenMsgSendType" BO_ 532 0;
BA_ "GenMsgCycleTime" BO_ 532 50;
BA_ "GenMsgSendType" BO_ 549 0;
BA_ "GenMsgCycleTime" BO_ 549 100;
BA_ "GenMsgSendType" BO_ 293 0;
BA_ "GenMsgCycleTime" BO_ 293 20;
BA_ "GenMsgSendType" BO_ 885 0;
BA_ "GenMsgCycleTime" BO_ 885 50;
BA_ "GenMsgSendType" BO_ 517 0;
BA_ "GenMsgCycleTime" BO_ 517 20;
BA_ "GenMsgSendType" BO_ 581 0;
BA_ "GenMsgCycleTime" BO_ 581 20;
BA_ "GenMsgSendType" BO_ 773 0;
BA_ "GenMsgCycleTime" BO_ 773 100;
BA_ "GenMsgSendType" BO_ 1171 0;
BA_ "GenMsgCycleTime" BO_ 1171 1000;
BA_ "GenMsgSendType" BO_ 550 0;
BA_ "GenMsgCycleTime" BO_ 550 100;
BA_ "GenMsgSendType" BO_ 1109 0;
BA_ "GenMsgCycleTime" BO_ 1109 100;
BA_ "GenMsgSendType" BO_ 1504 0;
BA_ "GenMsgCycleTime" BO_ 1504 10;
BA_ "GenMsgSendType" BO_ 1505 0;
BA_ "GenMsgCycleTime" BO_ 1505 100;
BA_ "GenMsgSendType" BO_ 1506 0;
BA_ "GenMsgCycleTime" BO_ 1506 100;
BA_ "GenMsgSendType" BO_ 1507 0;
BA_ "GenMsgCycleTime" BO_ 1507 100;
BA_ "GenMsgSendType" BO_ 523 0;
BA_ "GenMsgCycleTime" BO_ 523 50;
BA_ "GenMsgSendType" BO_ 854 0;
BA_ "GenMsgCycleTime" BO_ 854 50;
BA_ "GenMsgSendType" BO_ 870 0;
BA_ "GenMsgCycleTime" BO_ 870 20;
BA_ "GenMsgSendType" BO_ 646 0;
BA_ "GenMsgCycleTime" BO_ 646 20;
BA_ "GenMsgSendType" BO_ 630 0;
BA_ "GenMsgCycleTime" BO_ 630 20;
BA_ "GenMsgSendType" BO_ 662 0;
BA_ "GenMsgCycleTime" BO_ 662 20;
BA_ "GenMsgSendType" BO_ 1142 0;
BA_ "GenMsgCycleTime" BO_ 1142 100;
BA_ "GenMsgSendType" BO_ 840 0;
BA_ "GenMsgCycleTime" BO_ 840 50;
BA_ "GenMsgSendType" BO_ 504 0;
BA_ "GenMsgCycleTime" BO_ 504 10;
BA_ "GenMsgSendType" BO_ 1080 0;
BA_ "GenMsgCycleTime" BO_ 1080 100;
BA_ "GenMsgSendType" BO_ 537 0;
BA_ "GenMsgCycleTime" BO_ 537 20;
BA_ "GenMsgSendType" BO_ 544 0;
BA_ "GenMsgCycleTime" BO_ 544 100;
BA_ "GenMsgSendType" BO_ 757 0;
BA_ "GenMsgCycleTime" BO_ 757 50;
BA_ "GenMsgSendType" BO_ 937 0;
BA_ "GenMsgCycleTime" BO_ 937 20;
BA_ "GenMsgSendType" BO_ 425 0;
BA_ "GenMsgCycleTime" BO_ 425 20;
BA_ "GenMsgSendType" BO_ 992 0;
BA_ "GenMsgCycleTime" BO_ 992 100;
BA_ "GenMsgSendType" BO_ 409 0;
BA_ "GenMsgCycleTime" BO_ 409 50;
BA_ "GenMsgSendType" BO_ 792 0;
BA_ "GenMsgCycleTime" BO_ 792 50;
BA_ "GenMsgSendType" BO_ 524 0;
BA_ "GenMsgCycleTime" BO_ 524 100;
BA_ "GenMsgSendType" BO_ 703 0;
BA_ "GenMsgCycleTime" BO_ 703 50;
BA_ "GenMsgSendType" BO_ 1087 0;
BA_ "GenMsgCycleTime" BO_ 1087 1000;
BA_ "GenMsgSendType" BO_ 1074 0;
BA_ "GenMsgDelayTime" BO_ 1074 50;
BA_ "GenMsgCycleTime" BO_ 1074 100;
BA_ "GenMsgSendType" BO_ 1027 3;
BA_ "GenMsgNrOfRepetition" BO_ 1027 5;
BA_ "GenMsgCycleTimeFast" BO_ 1027 20;
BA_ "GenMsgCycleTime" BO_ 1027 100;
BA_ "GenMsgSendType" BO_ 811 0;
BA_ "GenMsgCycleTime" BO_ 811 50;
BA_ "GenMsgSendType" BO_ 929 1;
BA_ "GenMsgDelayTime" BO_ 929 10;
BA_ "GenMsgSendType" BO_ 930 1;
BA_ "GenMsgDelayTime" BO_ 930 10;
BA_ "GenMsgSendType" BO_ 274 0;
BA_ "GenMsgCycleTime" BO_ 274 100;
BA_ "GenMsgSendType" BO_ 266 0;
BA_ "GenMsgCycleTime" BO_ 266 100;
BA_ "GenMsgSendType" BO_ 133 0;
BA_ "GenMsgCycleTime" BO_ 133 20;
BA_ "GenMsgSendType" BO_ 834 0;
BA_ "GenMsgCycleTime" BO_ 834 10;
BA_ "GenMsgSendType" BO_ 1299 2;
BA_ "GenMsgCycleTime" BO_ 1299 640;
BA_ "NmAsrMessage" BO_ 1299 1;
BA_ "NmMessage" BO_ 1299 1;
BA_ "GenMsgSendType" BO_ 1324 2;
BA_ "GenMsgCycleTime" BO_ 1324 640;
BA_ "NmAsrMessage" BO_ 1324 1;
BA_ "NmMessage" BO_ 1324 1;
BA_ "GenMsgSendType" BO_ 1341 2;
BA_ "GenMsgCycleTime" BO_ 1341 640;
BA_ "NmAsrMessage" BO_ 1341 1;
BA_ "NmMessage" BO_ 1341 1;
BA_ "GenMsgSendType" BO_ 1307 2;
BA_ "GenMsgCycleTime" BO_ 1307 640;
BA_ "NmAsrMessage" BO_ 1307 1;
BA_ "NmMessage" BO_ 1307 1;
BA_ "GenMsgSendType" BO_ 1311 2;
BA_ "GenMsgCycleTime" BO_ 1311 640;
BA_ "NmAsrMessage" BO_ 1311 1;
BA_ "NmMessage" BO_ 1311 1;
BA_ "GenMsgSendType" BO_ 1282 2;
BA_ "GenMsgCycleTime" BO_ 1282 640;
BA_ "NmAsrMessage" BO_ 1282 1;
BA_ "NmMessage" BO_ 1282 1;
BA_ "GenMsgSendType" BO_ 1683 1;
BA_ "DiagRequest" BO_ 1683 1;
BA_ "GenMsgSendType" BO_ 1555 1;
BA_ "DiagResponse" BO_ 1555 1;
BA_ "GenMsgSendType" BO_ 1791 1;
BA_ "DiagState" BO_ 1791 1;
BA_ "GenSigSendType" SG_ 673 Checksum_0x2A1 0;
BA_ "GenSigSendType" SG_ 673 Rolling_Counter_0x2A1 0;
BA_ "GenSigInvalidValue" SG_ 673 Rolling_Counter_0x2A1 15;
BA_ "GenSigSendType" SG_ 673 ODS_Status 0;
BA_ "GenSigSendType" SG_ 673 EVCC_MHU_CharSchSetFeedBack 0;
BA_ "GenSigInvalidValue" SG_ 673 EVCC_MHU_CharSchSetFeedBack 3;
BA_ "GenSigSendType" SG_ 673 EVCC_ChargeGunSts 0;
BA_ "GenSigSendType" SG_ 673 EVCC_ChargeMode 0;
BA_ "GenSigSendType" SG_ 673 EVCC_CP_Value 0;
BA_ "GenSigInvalidValue" SG_ 673 EVCC_CP_Value 255;
BA_ "GenSigSendType" SG_ 673 EVCC_CP_Sts 0;
BA_ "GenSigInvalidValue" SG_ 673 EVCC_CP_Sts 15;
BA_ "GenSigSendType" SG_ 673 EVCC_PP_Value 0;
BA_ "GenSigSendType" SG_ 673 EVCC_Lock_Sts 0;
BA_ "GenSigSendType" SG_ 673 EVCC_ErrCode 0;
BA_ "GenSigSendType" SG_ 682 Checksum_0x2AA 0;
BA_ "GenSigSendType" SG_ 682 Rolling_Counter_0x2AA 0;
BA_ "GenSigInvalidValue" SG_ 682 Rolling_Counter_0x2AA 15;
BA_ "GenSigSendType" SG_ 682 EVCC_PLC_CommSts 0;
BA_ "GenSigSendType" SG_ 682 EVCC_DC_ChargeProcess 0;
BA_ "GenSigInvalidValue" SG_ 682 EVCC_DC_ChargeProcess 15;
BA_ "GenSigSendType" SG_ 682 EVCC_BMS_InsulationMonReq 0;
BA_ "GenSigSendType" SG_ 683 Checksum_0x2AB 0;
BA_ "GenSigSendType" SG_ 683 Rolling_Counter_0x2AB 0;
BA_ "GenSigInvalidValue" SG_ 683 Rolling_Counter_0x2AB 15;
BA_ "GenSigSendType" SG_ 683 EVCC_OBC_PowerReq 0;
BA_ "GenSigInvalidValue" SG_ 683 EVCC_OBC_PowerReq 127;
BA_ "GenSigSendType" SG_ 683 EVCC_OBC_VoltageReq 0;
BA_ "GenSigInvalidValue" SG_ 683 EVCC_OBC_VoltageReq 8191;
BA_ "GenSigSendType" SG_ 683 EVCC_OBC_CurrentReq 0;
BA_ "GenSigInvalidValue" SG_ 683 EVCC_OBC_CurrentReq 1023;
BA_ "GenSigSendType" SG_ 683 EVCC_OBC_Control 0;
BA_ "GenSigSendType" SG_ 683 EVCC_AC_ChargeSts 0;
BA_ "GenSigSendType" SG_ 536 Checksum_0x218 0;
BA_ "GenSigSendType" SG_ 536 Rolling_Counter_0x218 0;
BA_ "GenSigInvalidValue" SG_ 536 Rolling_Counter_0x218 15;
BA_ "GenSigSendType" SG_ 536 BMS_DC_Charge_input 0;
BA_ "GenSigSendType" SG_ 536 BMS_DC_Charge_Req 0;
BA_ "GenSigSendType" SG_ 536 BMS_DC_ChargeRelay_Sts 0;
BA_ "GenSigSendType" SG_ 534 Checksum_0x216 0;
BA_ "GenSigSendType" SG_ 534 Rolling_Counter_0x216 0;
BA_ "GenSigInvalidValue" SG_ 534 Rolling_Counter_0x216 15;
BA_ "GenSigSendType" SG_ 534 BMS_RemainChargeTime 0;
BA_ "GenSigInvalidValue" SG_ 534 BMS_RemainChargeTime 16383;
BA_ "GenSigSendType" SG_ 534 BMS_ChgVoltage_REQ 0;
BA_ "GenSigInvalidValue" SG_ 534 BMS_ChgVoltage_REQ 16383;
BA_ "GenSigSendType" SG_ 534 BMS_ChgCurrent_REQ 0;
BA_ "GenSigInvalidValue" SG_ 534 BMS_ChgCurrent_REQ 65535;
BA_ "GenSigSendType" SG_ 294 Checksum_0x126 0;
BA_ "GenSigSendType" SG_ 294 Rolling_Counter_0x126 0;
BA_ "GenSigInvalidValue" SG_ 294 Rolling_Counter_0x126 15;
BA_ "GenSigSendType" SG_ 294 BMS_AllowChgCurrPeak 0;
BA_ "GenSigInvalidValue" SG_ 294 BMS_AllowChgCurrPeak 65535;
BA_ "GenSigSendType" SG_ 294 BMS_AllowChgCurr 0;
BA_ "GenSigInvalidValue" SG_ 294 BMS_AllowChgCurr 65535;
BA_ "GenSigSendType" SG_ 521 Checksum_0x209 0;
BA_ "GenSigSendType" SG_ 521 Rolling_Counter_0x209 0;
BA_ "GenSigInvalidValue" SG_ 521 Rolling_Counter_0x209 15;
BA_ "GenSigSendType" SG_ 521 BMS_MaxDischgPwr_ALW 0;
BA_ "GenSigInvalidValue" SG_ 521 BMS_MaxDischgPwr_ALW 4095;
BA_ "GenSigSendType" SG_ 521 BMS_MaxChgPwr_ALW 0;
BA_ "GenSigInvalidValue" SG_ 521 BMS_MaxChgPwr_ALW 4095;
BA_ "GenSigSendType" SG_ 521 BMS_MaxDischgPwr_Peak 0;
BA_ "GenSigInvalidValue" SG_ 521 BMS_MaxDischgPwr_Peak 4095;
BA_ "GenSigSendType" SG_ 521 BMS_MaxChgPwr_Peak 0;
BA_ "GenSigInvalidValue" SG_ 521 BMS_MaxChgPwr_Peak 4095;
BA_ "GenSigSendType" SG_ 585 Checksum_0x249 0;
BA_ "GenSigSendType" SG_ 585 Rolling_Counter_0x249 0;
BA_ "GenSigInvalidValue" SG_ 585 Rolling_Counter_0x249 15;
BA_ "GenSigSendType" SG_ 585 BMS_CoolantOutletTemp 0;
BA_ "GenSigInvalidValue" SG_ 585 BMS_CoolantOutletTemp 255;
BA_ "GenSigStartValue" SG_ 585 BMS_CoolantOutletTemp 80;
BA_ "GenSigSendType" SG_ 585 BMS_CoolantInletTemp 0;
BA_ "GenSigInvalidValue" SG_ 585 BMS_CoolantInletTemp 255;
BA_ "GenSigStartValue" SG_ 585 BMS_CoolantInletTemp 80;
BA_ "GenSigSendType" SG_ 584 Checksum_0x248 0;
BA_ "GenSigSendType" SG_ 584 Rolling_Counter_0x248 0;
BA_ "GenSigInvalidValue" SG_ 584 Rolling_Counter_0x248 15;
BA_ "GenSigSendType" SG_ 584 BMS_FlowRate_Req 0;
BA_ "GenSigInvalidValue" SG_ 584 BMS_FlowRate_Req 255;
BA_ "GenSigSendType" SG_ 584 BMS_CoolPwrDemand 0;
BA_ "GenSigInvalidValue" SG_ 584 BMS_CoolPwrDemand 4095;
BA_ "GenSigSendType" SG_ 584 BMS_VCU_ValveOnOff_Req 0;
BA_ "GenSigSendType" SG_ 584 BMS_HeatPwrDemand 0;
BA_ "GenSigInvalidValue" SG_ 584 BMS_HeatPwrDemand 4095;
BA_ "GenSigSendType" SG_ 584 BMS_VCU_PTCOnOff_Req 0;
BA_ "GenSigSendType" SG_ 518 Checksum_0x206 0;
BA_ "GenSigSendType" SG_ 518 Rolling_Counter_0x206 0;
BA_ "GenSigInvalidValue" SG_ 518 Rolling_Counter_0x206 15;
BA_ "GenSigSendType" SG_ 518 BMS_MaxMinDiffCellVol 0;
BA_ "GenSigInvalidValue" SG_ 518 BMS_MaxMinDiffCellVol 8191;
BA_ "GenSigSendType" SG_ 818 Checksum_0x332 0;
BA_ "GenSigSendType" SG_ 818 Rolling_Counter_0x332 0;
BA_ "GenSigInvalidValue" SG_ 818 Rolling_Counter_0x332 15;
BA_ "GenSigSendType" SG_ 818 BMS_PackTemp_Infor 0;
BA_ "GenSigInvalidValue" SG_ 818 BMS_PackTemp_Infor 255;
BA_ "GenSigStartValue" SG_ 818 BMS_PackTemp_Infor 80;
BA_ "GenSigSendType" SG_ 818 BMS_PackCNom 0;
BA_ "GenSigInvalidValue" SG_ 818 BMS_PackCNom 65535;
BA_ "GenSigSendType" SG_ 816 Checksum_0x330 0;
BA_ "GenSigSendType" SG_ 816 Rolling_Counter_0x330 0;
BA_ "GenSigInvalidValue" SG_ 816 Rolling_Counter_0x330 15;
BA_ "GenSigSendType" SG_ 816 BMS_ContactorAging 0;
BA_ "GenSigInvalidValue" SG_ 816 BMS_ContactorAging 255;
BA_ "GenSigSendType" SG_ 374 Checksum_0x176 0;
BA_ "GenSigSendType" SG_ 374 Rolling_Counter_0x176 0;
BA_ "GenSigInvalidValue" SG_ 374 Rolling_Counter_0x176 15;
BA_ "GenSigSendType" SG_ 374 BMS_HVLinkVol_MEAS 0;
BA_ "GenSigInvalidValue" SG_ 374 BMS_HVLinkVol_MEAS 65535;
BA_ "GenSigSendType" SG_ 374 BMS_HVPackVol_MEAS 0;
BA_ "GenSigInvalidValue" SG_ 374 BMS_HVPackVol_MEAS 65535;
BA_ "GenSigSendType" SG_ 375 Checksum_0x177 0;
BA_ "GenSigSendType" SG_ 375 Rolling_Counter_0x177 0;
BA_ "GenSigInvalidValue" SG_ 375 Rolling_Counter_0x177 15;
BA_ "GenSigSendType" SG_ 375 BMS_HVBusVol_MEAS 0;
BA_ "GenSigInvalidValue" SG_ 375 BMS_HVBusVol_MEAS 65535;
BA_ "GenSigSendType" SG_ 375 BMS_HVFuseVol_MEAS 0;
BA_ "GenSigInvalidValue" SG_ 375 BMS_HVFuseVol_MEAS 65535;
BA_ "GenSigSendType" SG_ 372 Checksum_0x174 0;
BA_ "GenSigSendType" SG_ 372 Rolling_Counter_0x174 0;
BA_ "GenSigInvalidValue" SG_ 372 Rolling_Counter_0x174 15;
BA_ "GenSigSendType" SG_ 372 BMS_PackCur_MEAS 0;
BA_ "GenSigInvalidValue" SG_ 372 BMS_PackCur_MEAS 65535;
BA_ "GenSigStartValue" SG_ 372 BMS_PackCur_MEAS 32768;
BA_ "GenSigSendType" SG_ 533 Checksum_0x215 0;
BA_ "GenSigSendType" SG_ 533 Rolling_Counter_0x215 0;
BA_ "GenSigInvalidValue" SG_ 533 Rolling_Counter_0x215 15;
BA_ "GenSigSendType" SG_ 533 BMS_SOE 0;
BA_ "GenSigStartValue" SG_ 533 BMS_SOE 54;
BA_ "GenSigSendType" SG_ 533 BMS_HWCrash_Sts 0;
BA_ "GenSigSendType" SG_ 533 BMS_HVIL_STS 0;
BA_ "GenSigSendType" SG_ 533 BMS_IGN_Sts 0;
BA_ "GenSigSendType" SG_ 533 BMS_Sys_STS 0;
BA_ "GenSigSendType" SG_ 533 BMS_HVOnOff_STS 0;
BA_ "GenSigSendType" SG_ 533 BMS_Balance_STS 0;
BA_ "GenSigSendType" SG_ 533 BMS_SocActual_EST 0;
BA_ "GenSigSendType" SG_ 533 BMS_BatBalance_ERR 0;
BA_ "GenSigSendType" SG_ 533 BMS_ISU_Status 0;
BA_ "GenSigSendType" SG_ 533 BMS_ERR_LEV 0;
BA_ "GenSigSendType" SG_ 533 BMS_SOH 0;
BA_ "GenSigStartValue" SG_ 533 BMS_SOH 54;
BA_ "GenSigSendType" SG_ 533 BMS_HV_Sts 0;
BA_ "GenSigSendType" SG_ 931 BMS_MHU_Auth_Sts 1;
BA_ "GenSigSendType" SG_ 532 Checksum_0x214 0;
BA_ "GenSigSendType" SG_ 532 Rolling_Counter_0x214 0;
BA_ "GenSigInvalidValue" SG_ 532 Rolling_Counter_0x214 15;
BA_ "GenSigSendType" SG_ 532 BMS_Display_SOC 0;
BA_ "GenSigInvalidValue" SG_ 532 BMS_Display_SOC 1023;
BA_ "GenSigSendType" SG_ 549 Checksum_0x225 0;
BA_ "GenSigSendType" SG_ 549 Rolling_Counter_0x225 0;
BA_ "GenSigInvalidValue" SG_ 549 Rolling_Counter_0x225 15;
BA_ "GenSigSendType" SG_ 549 CDM_bAcvCanComStblMon 0;
BA_ "GenSigSendType" SG_ 549 FRMo_bErrHvbatStReqExtMon 0;
BA_ "GenSigSendType" SG_ 549 FRMo_bErrChrgnAllwdExtMon 0;
BA_ "GenSigSendType" SG_ 549 FRMo_bErrVehCrashStExtMon 0;
BA_ "GenSigSendType" SG_ 549 CDM_bErrComctnLossCanMon 0;
BA_ "GenSigSendType" SG_ 549 CTCMon_bErrCtctrSopcMon 0;
BA_ "GenSigSendType" SG_ 549 CTCMon_bInvldCtctrHisdIFbMon 0;
BA_ "GenSigSendType" SG_ 549 CTCMon_bInvldCtctrLosdUFbMon 0;
BA_ "GenSigSendType" SG_ 549 CTM_bErrCellTDifMaxMon 0;
BA_ "GenSigSendType" SG_ 549 CTM_bErrCellTMaxMon 0;
BA_ "GenSigSendType" SG_ 549 CTM_bErrCellTMinMon 0;
BA_ "GenSigSendType" SG_ 549 CTM_bErrThrwyPredMon 0;
BA_ "GenSigSendType" SG_ 549 CUM_bErrCellUDifMaxMon 0;
BA_ "GenSigSendType" SG_ 549 CUM_bErrCellUMaxMon 0;
BA_ "GenSigSendType" SG_ 549 CUM_bErrCellUMinMon 0;
BA_ "GenSigSendType" SG_ 549 CUM_bErrCellUProtnMaxNvMon 0;
BA_ "GenSigSendType" SG_ 549 CUM_bErrCellUProtnMinNvMon 0;
BA_ "GenSigSendType" SG_ 549 CUM_bErrPackUImplyMon 0;
BA_ "GenSigSendType" SG_ 549 EHPMon_bRdyHvilMon 0;
BA_ "GenSigSendType" SG_ 549 EHPMon_bErrWlddNegNvMon 0;
BA_ "GenSigSendType" SG_ 549 EHPMon_bErrWlddPosNvMon 0;
BA_ "GenSigSendType" SG_ 549 EHPMon_bErrWlddPrechNvMon 0;
BA_ "GenSigSendType" SG_ 549 EHPMon_bErrHvilMon 0;
BA_ "GenSigSendType" SG_ 549 EHPMon_bErrHvilShoMon 0;
BA_ "GenSigSendType" SG_ 549 EHPMon_bErrPackIslnRNvMon 0;
BA_ "GenSigSendType" SG_ 549 EHPMon_bErrVehCrashNvMon 0;
BA_ "GenSigSendType" SG_ 549 EHPMon_bErrVehIslnRNvMon 0;
BA_ "GenSigSendType" SG_ 549 FRMo_bErrMemStorgNvMon 0;
BA_ "GenSigSendType" SG_ 549 L1IM_bErrClmp30MaxMonInp 0;
BA_ "GenSigSendType" SG_ 549 L1IM_bErrClmp30MinMonInp 0;
BA_ "GenSigSendType" SG_ 549 L1IM_bErrCtctrDtrtMonInp 0;
BA_ "GenSigSendType" SG_ 549 L1IM_bErrUActImplyMonInp 0;
BA_ "GenSigSendType" SG_ 549 MCCM_bAcvMdulCtlrStsMon 0;
BA_ "GenSigSendType" SG_ 549 MCCM_bErrLntecSngFltMon 0;
BA_ "GenSigSendType" SG_ 549 MCCM_bErrLntecLtntFltMon 0;
BA_ "GenSigSendType" SG_ 549 MCCM_bErrMdulCellSnsrCfgMon 0;
BA_ "GenSigSendType" SG_ 549 MCCM_bErrMdulCtlrComMon 0;
BA_ "GenSigSendType" SG_ 549 MCCM_bErrSnsrTEltlMon 0;
BA_ "GenSigSendType" SG_ 549 MCCM_bWarnSnsrTEltlMon 0;
BA_ "GenSigSendType" SG_ 549 PCM_bRdySnsrIMon 0;
BA_ "GenSigSendType" SG_ 549 PCM_bErrPackEFlowMaxLimMon 0;
BA_ "GenSigSendType" SG_ 549 PCM_bErrPackIChDchaMaxLimMon 0;
BA_ "GenSigSendType" SG_ 549 PCM_bErrSnsrIImplyMon 0;
BA_ "GenSigSendType" SG_ 549 FRMo_bErrSnsrI1ExtMon 0;
BA_ "GenSigSendType" SG_ 549 PCM_bInvldSnsrI1Mon 0;
BA_ "GenSigSendType" SG_ 549 PCM_bInvldSnsrI2Mon 0;
BA_ "GenSigSendType" SG_ 549 FRMo_bErrSopcLvl3Mon 0;
BA_ "GenSigSendType" SG_ 549 BMS_FRMo_Reserved_1 0;
BA_ "GenSigSendType" SG_ 549 BMS_FRMo_Reserved_2 0;
BA_ "GenSigSendType" SG_ 549 BMS_FRMo_Reserved_3 0;
BA_ "GenSigSendType" SG_ 549 BMS_FRMo_Reserved_4 0;
BA_ "GenSigSendType" SG_ 549 BMS_FRMo_Reserved_5 0;
BA_ "GenSigSendType" SG_ 293 Checksum_0x125 0;
BA_ "GenSigSendType" SG_ 293 Rolling_Counter_0x125 0;
BA_ "GenSigInvalidValue" SG_ 293 Rolling_Counter_0x125 15;
BA_ "GenSigSendType" SG_ 293 BMS_AllowDischgCurr 0;
BA_ "GenSigInvalidValue" SG_ 293 BMS_AllowDischgCurr 65535;
BA_ "GenSigSendType" SG_ 293 BMS_AllowDischgCurrPeak 0;
BA_ "GenSigInvalidValue" SG_ 293 BMS_AllowDischgCurrPeak 65535;
BA_ "GenSigSendType" SG_ 885 Checksum_0x375 0;
BA_ "GenSigSendType" SG_ 885 Rolling_Counter_0x375 0;
BA_ "GenSigInvalidValue" SG_ 885 Rolling_Counter_0x375 15;
BA_ "GenSigSendType" SG_ 885 BMS_MainPosRelay_ERR 0;
BA_ "GenSigSendType" SG_ 885 BMS_MainPosRelay_STS 0;
BA_ "GenSigInvalidValue" SG_ 885 BMS_MainPosRelay_STS 7;
BA_ "GenSigSendType" SG_ 885 BMS_PreChgRelay_ERR 0;
BA_ "GenSigSendType" SG_ 885 BMS_PreChgRelay_STS 0;
BA_ "GenSigInvalidValue" SG_ 885 BMS_PreChgRelay_STS 7;
BA_ "GenSigSendType" SG_ 885 BMS_TotalNegRelay_STS 0;
BA_ "GenSigInvalidValue" SG_ 885 BMS_TotalNegRelay_STS 7;
BA_ "GenSigSendType" SG_ 885 BMS_TotalNegRelay_ERR 0;
BA_ "GenSigSendType" SG_ 517 Checksum_0x205 0;
BA_ "GenSigSendType" SG_ 517 Rolling_Counter_0x205 0;
BA_ "GenSigInvalidValue" SG_ 517 Rolling_Counter_0x205 15;
BA_ "GenSigSendType" SG_ 517 BMS_MaxCellVol 0;
BA_ "GenSigInvalidValue" SG_ 517 BMS_MaxCellVol 8191;
BA_ "GenSigSendType" SG_ 517 BMS_CellNumMaxCellVol 0;
BA_ "GenSigSendType" SG_ 517 BMS_MinCellVol 0;
BA_ "GenSigInvalidValue" SG_ 517 BMS_MinCellVol 8191;
BA_ "GenSigSendType" SG_ 517 BMS_CellNumMinCellVol 0;
BA_ "GenSigSendType" SG_ 581 Checksum_0x245 0;
BA_ "GenSigSendType" SG_ 581 Rolling_Counter_0x245 0;
BA_ "GenSigInvalidValue" SG_ 581 Rolling_Counter_0x245 15;
BA_ "GenSigSendType" SG_ 581 BMS_PackTemp 0;
BA_ "GenSigInvalidValue" SG_ 581 BMS_PackTemp 255;
BA_ "GenSigStartValue" SG_ 581 BMS_PackTemp 80;
BA_ "GenSigSendType" SG_ 581 BMS_MaxMinDiffCellTemp 0;
BA_ "GenSigInvalidValue" SG_ 581 BMS_MaxMinDiffCellTemp 255;
BA_ "GenSigStartValue" SG_ 581 BMS_MaxMinDiffCellTemp 80;
BA_ "GenSigSendType" SG_ 581 BMS_MaxCellTemp 0;
BA_ "GenSigInvalidValue" SG_ 581 BMS_MaxCellTemp 255;
BA_ "GenSigStartValue" SG_ 581 BMS_MaxCellTemp 80;
BA_ "GenSigSendType" SG_ 581 BMS_MinCellTemp 0;
BA_ "GenSigInvalidValue" SG_ 581 BMS_MinCellTemp 255;
BA_ "GenSigStartValue" SG_ 581 BMS_MinCellTemp 80;
BA_ "GenSigSendType" SG_ 581 BMS_ProbeNumMaxCellTemp 0;
BA_ "GenSigStartValue" SG_ 581 BMS_ProbeNumMaxCellTemp 1;
BA_ "GenSigSendType" SG_ 581 BMS_ProbeNumMinCellTemp 0;
BA_ "GenSigSendType" SG_ 773 Checksum_0x305 0;
BA_ "GenSigSendType" SG_ 773 Rolling_Counter_0x305 0;
BA_ "GenSigInvalidValue" SG_ 773 Rolling_Counter_0x305 15;
BA_ "GenSigSendType" SG_ 773 BMS_VCU_Insulation_Mon_Sts 0;
BA_ "GenSigSendType" SG_ 773 BMS_PackInsuRes 0;
BA_ "GenSigStartValue" SG_ 773 BMS_PackInsuRes 5535;
BA_ "GenSigSendType" SG_ 1171 BMS_DischargeCurrent_Limited 0;
BA_ "GenSigSendType" SG_ 1171 BMS_Warning_Flag_Reserved_07 0;
BA_ "GenSigSendType" SG_ 1171 BMS_Warning_Flag_Reserved_11 0;
BA_ "GenSigSendType" SG_ 1171 BMS_Warning_Flag_Reserved_10 0;
BA_ "GenSigSendType" SG_ 1171 BMS_Warning_Flag_Reserved_09 0;
BA_ "GenSigSendType" SG_ 1171 BMS_Warning_Flag_Reserved_13 0;
BA_ "GenSigSendType" SG_ 1171 BMS_Warning_Flag_Reserved_12 0;
BA_ "GenSigSendType" SG_ 1171 BMS_Warning_Flag_Reserved_06 0;
BA_ "GenSigSendType" SG_ 1171 BMS_Warning_Flag_Reserved_05 0;
BA_ "GenSigSendType" SG_ 1171 BMS_Warning_Flag_Reserved_04 0;
BA_ "GenSigSendType" SG_ 1171 BMS_MalfunctionSts 0;
BA_ "GenSigSendType" SG_ 1171 BMS_LowBattery 0;
BA_ "GenSigInvalidValue" SG_ 1171 BMS_LowBattery 3;
BA_ "GenSigSendType" SG_ 1171 BMS_BatteryReplacement 0;
BA_ "GenSigSendType" SG_ 1171 BMS_PackTempSts 0;
BA_ "GenSigSendType" SG_ 1171 BMS_ThermalRunaway 0;
BA_ "GenSigSendType" SG_ 1171 Rolling_Counter_0x493 0;
BA_ "GenSigInvalidValue" SG_ 1171 Rolling_Counter_0x493 15;
BA_ "GenSigSendType" SG_ 1171 Checksum_0x493 0;
BA_ "GenSigSendType" SG_ 550 BMS_QMMo_Reserved_9 0;
BA_ "GenSigSendType" SG_ 550 BMS_QMMo_Reserved_8 0;
BA_ "GenSigSendType" SG_ 550 BMS_QMMo_Reserved_7 0;
BA_ "GenSigSendType" SG_ 550 BMS_QMMo_Reserved_6 0;
BA_ "GenSigSendType" SG_ 550 BMS_QMMo_Reserved_5 0;
BA_ "GenSigSendType" SG_ 550 BMS_QMMo_Reserved_4 0;
BA_ "GenSigSendType" SG_ 550 BMS_QMMo_Reserved_3 0;
BA_ "GenSigSendType" SG_ 550 BMS_QMMo_Reserved_2 0;
BA_ "GenSigSendType" SG_ 550 BMS_QMMo_Reserved_11 0;
BA_ "GenSigSendType" SG_ 550 BMS_QMMo_Reserved_10 0;
BA_ "GenSigSendType" SG_ 550 BMS_QMMo_Reserved_1 0;
BA_ "GenSigSendType" SG_ 550 BMS_QMMo_Reserved_0 0;
BA_ "GenSigSendType" SG_ 550 Rolling_Counter_0x226 0;
BA_ "GenSigInvalidValue" SG_ 550 Rolling_Counter_0x226 15;
BA_ "GenSigSendType" SG_ 550 Checksum_0x226 0;
BA_ "GenSigSendType" SG_ 1109 Checksum_0x455 0;
BA_ "GenSigSendType" SG_ 1109 Rolling_Counter_0x455 0;
BA_ "GenSigInvalidValue" SG_ 1109 Rolling_Counter_0x455 15;
BA_ "GenSigSendType" SG_ 1109 BMS_PackInsu_ERR 0;
BA_ "GenSigSendType" SG_ 1109 BMS_CellVoltDiff_ERR 0;
BA_ "GenSigSendType" SG_ 1109 BMS_PackOverCurr_ERR 0;
BA_ "GenSigSendType" SG_ 1109 BMS_HVIL_Err 0;
BA_ "GenSigSendType" SG_ 1109 BMS_CellHighVol_ERR 0;
BA_ "GenSigSendType" SG_ 1109 BMS_CellLowVol_ERR 0;
BA_ "GenSigSendType" SG_ 1109 BMS_PackLowVol_ERR 0;
BA_ "GenSigSendType" SG_ 1109 BMS_PackHighVol_ERR 0;
BA_ "GenSigSendType" SG_ 1109 BMS_ProbeHighTemp_ERR 0;
BA_ "GenSigSendType" SG_ 1109 BMS_ProbeTempDiff_ERR 0;
BA_ "GenSigSendType" SG_ 1109 BMS_FuseStatus_ERR 0;
BA_ "GenSigSendType" SG_ 1109 BMS_ProbeLowTemp_ERR 0;
BA_ "GenSigSendType" SG_ 1504 BMS_Voltage_FrameNumber 0;
BA_ "GenSigSendType" SG_ 1504 BMS_Voltage_Value1 0;
BA_ "GenSigSendType" SG_ 1504 BMS_Voltage_Value2 0;
BA_ "GenSigSendType" SG_ 1504 BMS_Voltage_Value3 0;
BA_ "GenSigSendType" SG_ 1504 softwore_version 0;
BA_ "GenSigSendType" SG_ 1505 BMS_Temp_FrameNumber 0;
BA_ "GenSigSendType" SG_ 1505 BMS_Temp_Value1 0;
BA_ "GenSigSendType" SG_ 1505 BMS_Temp_Value2 0;
BA_ "GenSigSendType" SG_ 1505 BMS_Temp_Value3 0;
BA_ "GenSigSendType" SG_ 1505 BMS_Temp_Value4 0;
BA_ "GenSigSendType" SG_ 1505 BMS_Temp_Value5 0;
BA_ "GenSigSendType" SG_ 1505 BMS_Temp_Value6 0;
BA_ "GenSigSendType" SG_ 1505 BMS_Temp_Value7 0;
BA_ "GenSigSendType" SG_ 1506 BMS_Test_Runaway 0;
BA_ "GenSigSendType" SG_ 1506 BMS_Test_shunt_Temp 0;
BA_ "GenSigSendType" SG_ 1506 BMS_Test_V4_Volt 0;
BA_ "GenSigSendType" SG_ 1506 BMS_Test_L2ErrNum 0;
BA_ "GenSigSendType" SG_ 1507 Error_Information 0;
BA_ "GenSigSendType" SG_ 1507 HVIL_HS_Volt 0;
BA_ "GenSigSendType" SG_ 1507 HVIL_LS_Volt 0;
BA_ "GenSigSendType" SG_ 1507 FCHVIL_HS_Volt 0;
BA_ "GenSigSendType" SG_ 1507 FCHVIL_LS_Volt 0;
BA_ "GenSigSendType" SG_ 1507 HVIL_HS_Inv 0;
BA_ "GenSigSendType" SG_ 1507 HVIL_LS_Inv 0;
BA_ "GenSigSendType" SG_ 1507 FCHVIL_HS_Inv 0;
BA_ "GenSigSendType" SG_ 1507 FCHVIL_LS_Inv 0;
BA_ "GenSigSendType" SG_ 1507 HVIL_Fault 0;
BA_ "GenSigSendType" SG_ 1507 HallError 0;
BA_ "GenSigSendType" SG_ 523 Checksum_0x20B 0;
BA_ "GenSigSendType" SG_ 523 Rolling_Counter_0x20B 0;
BA_ "GenSigInvalidValue" SG_ 523 Rolling_Counter_0x20B 15;
BA_ "GenSigSendType" SG_ 523 DCDC_Sys_STS 0;
BA_ "GenSigInvalidValue" SG_ 523 DCDC_Sys_STS 5;
BA_ "GenSigSendType" SG_ 523 DCDC_Voltage_Input 0;
BA_ "GenSigInvalidValue" SG_ 523 DCDC_Voltage_Input 1023;
BA_ "GenSigSendType" SG_ 523 DCDC_Current_Input 0;
BA_ "GenSigInvalidValue" SG_ 523 DCDC_Current_Input 255;
BA_ "GenSigSendType" SG_ 523 DCDC_Voltage_Output 0;
BA_ "GenSigInvalidValue" SG_ 523 DCDC_Voltage_Output 1023;
BA_ "GenSigSendType" SG_ 523 DCDC_Current_Output 0;
BA_ "GenSigInvalidValue" SG_ 523 DCDC_Current_Output 255;
BA_ "GenSigSendType" SG_ 523 DCDC_Output_STS 0;
BA_ "GenSigSendType" SG_ 523 DCDC_Temp 0;
BA_ "GenSigInvalidValue" SG_ 523 DCDC_Temp 255;
BA_ "GenSigStartValue" SG_ 523 DCDC_Temp 40;
BA_ "GenSigSendType" SG_ 854 Checksum_0x356 0;
BA_ "GenSigSendType" SG_ 854 Rolling_Counter_0x356 0;
BA_ "GenSigInvalidValue" SG_ 854 Rolling_Counter_0x356 15;
BA_ "GenSigSendType" SG_ 854 OBC_WorkStatus 0;
BA_ "GenSigSendType" SG_ 854 OBC_Sys_STS 0;
BA_ "GenSigInvalidValue" SG_ 854 OBC_Sys_STS 3;
BA_ "GenSigSendType" SG_ 854 OBC_StartStatus 0;
BA_ "GenSigSendType" SG_ 854 OBC_ChargeConnetState 0;
BA_ "GenSigInvalidValue" SG_ 854 OBC_ChargeConnetState 3;
BA_ "GenSigSendType" SG_ 870 Checksum_0x366 0;
BA_ "GenSigSendType" SG_ 870 Rolling_Counter_0x366 0;
BA_ "GenSigInvalidValue" SG_ 870 Rolling_Counter_0x366 15;
BA_ "GenSigSendType" SG_ 870 CurrentLimit_reserved 0;
BA_ "GenSigSendType" SG_ 870 OBC_CP_State_reserved 0;
BA_ "GenSigSendType" SG_ 870 OBC_Charge_air_temp 0;
BA_ "GenSigInvalidValue" SG_ 870 OBC_Charge_air_temp 255;
BA_ "GenSigStartValue" SG_ 870 OBC_Charge_air_temp 40;
BA_ "GenSigSendType" SG_ 870 OBC_Temp_Reserved 0;
BA_ "GenSigInvalidValue" SG_ 870 OBC_Temp_Reserved 255;
BA_ "GenSigStartValue" SG_ 870 OBC_Temp_Reserved 40;
BA_ "GenSigSendType" SG_ 646 Checksum_0x286 0;
BA_ "GenSigSendType" SG_ 646 Rolling_Counter_0x286 0;
BA_ "GenSigInvalidValue" SG_ 646 Rolling_Counter_0x286 15;
BA_ "GenSigSendType" SG_ 646 OBC_OUT_DC_V 0;
BA_ "GenSigInvalidValue" SG_ 646 OBC_OUT_DC_V 65535;
BA_ "GenSigSendType" SG_ 646 OBC_OUT_DC_I 0;
BA_ "GenSigInvalidValue" SG_ 646 OBC_OUT_DC_I 16383;
BA_ "GenSigSendType" SG_ 646 OBC_DCCharge_line_V 0;
BA_ "GenSigInvalidValue" SG_ 646 OBC_DCCharge_line_V 65535;
BA_ "GenSigSendType" SG_ 630 Checksum_0x276 0;
BA_ "GenSigSendType" SG_ 630 Rolling_Counter_0x276 0;
BA_ "GenSigInvalidValue" SG_ 630 Rolling_Counter_0x276 15;
BA_ "GenSigSendType" SG_ 630 OBC_Input_U 0;
BA_ "GenSigInvalidValue" SG_ 630 OBC_Input_U 65535;
BA_ "GenSigSendType" SG_ 630 OBC_IN_Main_V_Reserved 0;
BA_ "GenSigInvalidValue" SG_ 630 OBC_IN_Main_V_Reserved 65535;
BA_ "GenSigSendType" SG_ 630 OBC_IN_Main_I_Reserved 0;
BA_ "GenSigInvalidValue" SG_ 630 OBC_IN_Main_I_Reserved 1023;
BA_ "GenSigSendType" SG_ 662 Checksum_0x296 0;
BA_ "GenSigSendType" SG_ 662 Rolling_Counter_0x296 0;
BA_ "GenSigInvalidValue" SG_ 662 Rolling_Counter_0x296 15;
BA_ "GenSigSendType" SG_ 662 OBC_MaxOutputChgU 0;
BA_ "GenSigInvalidValue" SG_ 662 OBC_MaxOutputChgU 8191;
BA_ "GenSigSendType" SG_ 662 OBC_MaxOutputChgI 0;
BA_ "GenSigInvalidValue" SG_ 662 OBC_MaxOutputChgI 511;
BA_ "GenSigSendType" SG_ 662 OBC_MaxOutputPwr 0;
BA_ "GenSigInvalidValue" SG_ 662 OBC_MaxOutputPwr 127;
BA_ "GenSigSendType" SG_ 1142 OBC_FailGrade_ERR 0;
BA_ "GenSigSendType" SG_ 1142 OBC_ErrorFlag_Reserved 0;
BA_ "GenSigSendType" SG_ 1142 OBC_Hardware_ERR 0;
BA_ "GenSigSendType" SG_ 1142 OBC_OTemp_ERR 0;
BA_ "GenSigSendType" SG_ 1142 OBC_OCofOut_ERR_Reserved 0;
BA_ "GenSigSendType" SG_ 1142 OBC_SlwChgSktOTemp_ERR_Reserved 0;
BA_ "GenSigSendType" SG_ 1142 OBC_CANcomoverT_ERR 0;
BA_ "GenSigSendType" SG_ 1142 OBC_UVofIn_ERR_Reserved 0;
BA_ "GenSigSendType" SG_ 1142 OBC_OVofIn_ERR_Reserved 0;
BA_ "GenSigSendType" SG_ 1142 OBC_OVofPFC_ERR_Reserved 0;
BA_ "GenSigSendType" SG_ 1142 OBC_UVofPFC_ERR_Reserved 0;
BA_ "GenSigSendType" SG_ 1142 OBC_UVofOut_ERR 0;
BA_ "GenSigSendType" SG_ 1142 OBC_OVofOut_ERR 0;
BA_ "GenSigSendType" SG_ 840 EDS_bus_Volt_FWD 0;
BA_ "GenSigInvalidValue" SG_ 840 EDS_bus_Volt_FWD 16383;
BA_ "GenSigSendType" SG_ 840 EDS_bus_Curr_FWD 0;
BA_ "GenSigInvalidValue" SG_ 840 EDS_bus_Curr_FWD 65535;
BA_ "GenSigStartValue" SG_ 840 EDS_bus_Curr_FWD 10000;
BA_ "GenSigSendType" SG_ 840 EDS_MtrNumb_FWD 0;
BA_ "GenSigSendType" SG_ 840 EDS_DriveMtrNmb_FWD 0;
BA_ "GenSigSendType" SG_ 840 EDS_HVIL_STS_FWD 0;
BA_ "GenSigSendType" SG_ 504 Checksum_0x1F8 0;
BA_ "GenSigSendType" SG_ 504 Rolling_Counter_0x1F8 0;
BA_ "GenSigInvalidValue" SG_ 504 Rolling_Counter_0x1F8 15;
BA_ "GenSigSendType" SG_ 504 EDS_output_trq_FR 0;
BA_ "GenSigInvalidValue" SG_ 504 EDS_output_trq_FR 65535;
BA_ "GenSigStartValue" SG_ 504 EDS_output_trq_FR 2000;
BA_ "GenSigSendType" SG_ 504 EDS_output_trqValid_FR 0;
BA_ "GenSigSendType" SG_ 504 EDS_Spd_FR 0;
BA_ "GenSigInvalidValue" SG_ 504 EDS_Spd_FR 65535;
BA_ "GenSigStartValue" SG_ 504 EDS_Spd_FR 20000;
BA_ "GenSigSendType" SG_ 504 EDS_SpdValid_FR 0;
BA_ "GenSigSendType" SG_ 504 EDS_MotorDriveSts_FR 0;
BA_ "GenSigInvalidValue" SG_ 504 EDS_MotorDriveSts_FR 3;
BA_ "GenSigSendType" SG_ 504 EDS_Work_STS_FR 0;
BA_ "GenSigInvalidValue" SG_ 504 EDS_Work_STS_FR 15;
BA_ "GenSigSendType" SG_ 504 EDS_powoff_req_FR 0;
BA_ "GenSigSendType" SG_ 1080 EDS_FailNum_ERR_FWD 0;
BA_ "GenSigSendType" SG_ 1080 EDS_FailGrade_ERR_FWD 0;
BA_ "GenSigSendType" SG_ 1080 EDS_MotOverTempAlarm_FWD 0;
BA_ "GenSigSendType" SG_ 1080 EDS_MotOverTempFault_FWD 0;
BA_ "GenSigSendType" SG_ 1080 EDS_MotTempSenFault_FWD 0;
BA_ "GenSigSendType" SG_ 1080 EDS_EDSOverTempUFault_FWD 0;
BA_ "GenSigSendType" SG_ 1080 EDS_EDSOverTempVFault_FWD 0;
BA_ "GenSigSendType" SG_ 1080 EDS_EDSOverTempWFault_FWD 0;
BA_ "GenSigSendType" SG_ 1080 EDS_EDSOverTempAlarm_FWD 0;
BA_ "GenSigSendType" SG_ 1080 EDS_TCoolantOvHi_FWD 0;
BA_ "GenSigSendType" SG_ 1080 EDS_EDSTempCmpAlarm_FWD 0;
BA_ "GenSigSendType" SG_ 1080 EDS_EDSPhaOvCurentHWFault_FWD 0;
BA_ "GenSigSendType" SG_ 1080 EDS_EDSphaOffCalFault_FWD 0;
BA_ "GenSigSendType" SG_ 1080 EDS_EDSOverIdcLnkAlarm_FWD 0;
BA_ "GenSigSendType" SG_ 1080 EDS_EDSHVOverVoltageAlarm_FWD 0;
BA_ "GenSigSendType" SG_ 1080 EDS_EDSHVOverVoltageFault_FWD 0;
BA_ "GenSigSendType" SG_ 1080 EDS_EDSHVUnderVoltageAlarm_FWD 0;
BA_ "GenSigSendType" SG_ 1080 EDS_EDSHVUnderVoltageFault_FWD 0;
BA_ "GenSigSendType" SG_ 1080 EDS_RunToDischaErr_FWD 0;
BA_ "GenSigSendType" SG_ 1080 EDS_12VOverVoltageAlarm_FWD 0;
BA_ "GenSigSendType" SG_ 1080 EDS_12VUnderVoltageAlarm_FWD 0;
BA_ "GenSigSendType" SG_ 1080 EDS_MotOverAlarm_FWD 0;
BA_ "GenSigSendType" SG_ 1080 EDS_MotOverFault_FWD 0;
BA_ "GenSigSendType" SG_ 1080 EDS_iDcLnkOvCLimFail_FWD 0;
BA_ "GenSigSendType" SG_ 1080 EDS_MotBlockedFault_FWD 0;
BA_ "GenSigSendType" SG_ 1080 EDS_RSLErr_FWD 0;
BA_ "GenSigSendType" SG_ 1080 EDS_MotTrqLimFault_FWD 0;
BA_ "GenSigSendType" SG_ 1080 EDS_ResolverOffsetAngle_FWD 0;
BA_ "GenSigSendType" SG_ 1080 EDS_EDSDisChgFault_FWD 0;
BA_ "GenSigSendType" SG_ 1080 EDS_IGBTFault_FWD 0;
BA_ "GenSigSendType" SG_ 1080 EDS_CANBusoffFault_FWD 0;
BA_ "GenSigSendType" SG_ 1080 EDS_TDrvBoardOvHiWarn_FWD 0;
BA_ "GenSigSendType" SG_ 1080 EDS_TIGBTOvHiFault_FWD 0;
BA_ "GenSigSendType" SG_ 1080 EDS_TIGBTOvHiWarn_FWD 0;
BA_ "GenSigSendType" SG_ 1080 EDS_IOHWABSampFail_FWD 0;
BA_ "GenSigSendType" SG_ 1080 EDS_EDSOpenFault_FWD 0;
BA_ "GenSigSendType" SG_ 1080 EDS_MotorOpenFault_FWD 0;
BA_ "GenSigSendType" SG_ 1080 EDS_EmacBlkdWarn_FWD 0;
BA_ "GenSigSendType" SG_ 1080 EDS_VerMatchFailureErr_FWD 0;
BA_ "GenSigSendType" SG_ 1080 EDS_DiashCirNoPsblErr_FWD 0;
BA_ "GenSigSendType" SG_ 1080 EDS_OperOutdRngErr_FWD 0;
BA_ "GenSigSendType" SG_ 1080 EDS_PhaseLossFaultErr_FWD 0;
BA_ "GenSigSendType" SG_ 1080 EDS_CPLDFault_FWD 0;
BA_ "GenSigSendType" SG_ 1080 EDS_CPLDFaultBaseSpd_FWD 0;
BA_ "GenSigSendType" SG_ 1080 EDS_IOHWABNen33Fail_FWD 0;
BA_ "GenSigSendType" SG_ 1080 EDS_HvMcuSlightFault_RWD 0;
BA_ "GenSigSendType" SG_ 1080 EDS_HvMcuSevFault_FWD 0;
BA_ "GenSigSendType" SG_ 1080 EDS_EDSPhaSampHWFault_FWD 0;
BA_ "GenSigSendType" SG_ 1080 EDS_IsOvHiErr_FWD 0;
BA_ "GenSigSendType" SG_ 1080 EDS_CanRollingCounterErr_FWD 0;
BA_ "GenSigSendType" SG_ 1080 EDS_CanTimeoutErr_FWD 0;
BA_ "GenSigSendType" SG_ 1080 EDS_CrashFault_FWD 0;
BA_ "GenSigSendType" SG_ 537 Checksum_0x219 0;
BA_ "GenSigSendType" SG_ 537 Rolling_Counter_0x219 0;
BA_ "GenSigInvalidValue" SG_ 537 Rolling_Counter_0x219 15;
BA_ "GenSigSendType" SG_ 537 VCU_VehicleDischargePower 0;
BA_ "GenSigInvalidValue" SG_ 537 VCU_VehicleDischargePower 127;
BA_ "GenSigSendType" SG_ 537 VCU_VehicleChargePower 0;
BA_ "GenSigInvalidValue" SG_ 537 VCU_VehicleChargePower 127;
BA_ "GenSigSendType" SG_ 537 VCU_ChargeAllow 0;
BA_ "GenSigSendType" SG_ 544 Checksum_0x220 0;
BA_ "GenSigSendType" SG_ 544 Rolling_Counter_0x220 0;
BA_ "GenSigInvalidValue" SG_ 544 Rolling_Counter_0x220 15;
BA_ "GenSigSendType" SG_ 544 VCU_BMS_PTCOnOff_Sts 0;
BA_ "GenSigSendType" SG_ 544 VCU_BMS_ValveOnOff_Sts 0;
BA_ "GenSigSendType" SG_ 544 VCU_BMS_PumpFB 0;
BA_ "GenSigSendType" SG_ 757 VCU_Charge_Control 0;
BA_ "GenSigSendType" SG_ 757 VCU_AC_chargeSock_temp1 0;
BA_ "GenSigInvalidValue" SG_ 757 VCU_AC_chargeSock_temp1 2047;
BA_ "GenSigSendType" SG_ 757 VCU_DC_chargeSock_temp1 0;
BA_ "GenSigInvalidValue" SG_ 757 VCU_DC_chargeSock_temp1 2047;
BA_ "GenSigSendType" SG_ 757 VCU_DC_chargeSock_temp2 0;
BA_ "GenSigInvalidValue" SG_ 757 VCU_DC_chargeSock_temp2 2047;
BA_ "GenSigSendType" SG_ 937 VCU_PTC_RelaySts 0;
BA_ "GenSigSendType" SG_ 937 VCU_EACEnbReq 0;
BA_ "GenSigSendType" SG_ 937 VCU_EACAllowedPower 0;
BA_ "GenSigInvalidValue" SG_ 937 VCU_EACAllowedPower 1023;
BA_ "GenSigSendType" SG_ 937 VCU_EAC_CompSpdReq 0;
BA_ "GenSigInvalidValue" SG_ 937 VCU_EAC_CompSpdReq 16383;
BA_ "GenSigSendType" SG_ 937 VCU_DriveCoolWaterFlowRate 0;
BA_ "GenSigSendType" SG_ 937 VCU_DriveCoolInletWaterTemp 0;
BA_ "GenSigSendType" SG_ 425 VCU_RegenLevel_Feed 0;
BA_ "GenSigStartValue" SG_ 425 VCU_RegenLevel_Feed 2;
BA_ "GenSigSendType" SG_ 425 VCU_RBCSts 0;
BA_ "GenSigSendType" SG_ 425 VCU_RDCSts 0;
BA_ "GenSigSendType" SG_ 425 VCU_Veh_ERR 0;
BA_ "GenSigSendType" SG_ 425 VCU_DrvSys_ERR 0;
BA_ "GenSigSendType" SG_ 425 VCU_PackSys_ERR 0;
BA_ "GenSigSendType" SG_ 425 VCU_TBOX_Veh_STS_Reserved 0;
BA_ "GenSigSendType" SG_ 425 VCU_VehChg_STS 0;
BA_ "GenSigSendType" SG_ 425 VCU_BatterVoltage_Reserved 0;
BA_ "GenSigInvalidValue" SG_ 425 VCU_BatterVoltage_Reserved 255;
BA_ "GenSigStartValue" SG_ 425 VCU_BatterVoltage_Reserved 171;
BA_ "GenSigSendType" SG_ 425 VCU_BatteryVoltErr_Reserved 0;
BA_ "GenSigSendType" SG_ 425 VCU_MotorCoolingCircuitErr_Reserved 0;
BA_ "GenSigSendType" SG_ 425 VCU_PackCoolingCircuitErr_Reserved 0;
BA_ "GenSigSendType" SG_ 425 VCU_VehicleHVStatus 0;
BA_ "GenSigInvalidValue" SG_ 425 VCU_VehicleHVStatus 3;
BA_ "GenSigSendType" SG_ 425 VCU_InstantPowerConsump 0;
BA_ "GenSigInvalidValue" SG_ 425 VCU_InstantPowerConsump 1023;
BA_ "GenSigSendType" SG_ 425 VCU_AveragePowerConsump 0;
BA_ "GenSigInvalidValue" SG_ 425 VCU_AveragePowerConsump 1023;
BA_ "GenSigSendType" SG_ 425 VCU_BrakePedalSts 0;
BA_ "GenSigSendType" SG_ 992 Checksum_0x3E0 0;
BA_ "GenSigSendType" SG_ 992 Rolling_Counter_0x3E0 0;
BA_ "GenSigInvalidValue" SG_ 992 Rolling_Counter_0x3E0 15;
BA_ "GenSigSendType" SG_ 992 VCU_RunningRange 0;
BA_ "GenSigSendType" SG_ 992 VCU_MHU_Ack_ChgSche_stt 0;
BA_ "GenSigSendType" SG_ 992 VCU_MHU_GuestMode_sts 0;
BA_ "GenSigSendType" SG_ 992 VCU_MHU_Ack_TargetSOC 0;
BA_ "GenSigStartValue" SG_ 992 VCU_MHU_Ack_TargetSOC 100;
BA_ "GenSigSendType" SG_ 992 VCU_ValetMode_sts 0;
BA_ "GenSigSendType" SG_ 992 VCU_ValetMode_MaxSpeedSts 0;
BA_ "GenSigInvalidValue" SG_ 992 VCU_ValetMode_MaxSpeedSts 2;
BA_ "GenSigInactiveValue" SG_ 992 VCU_ValetMode_MaxSpeedSts 255;
BA_ "GenSigSendType" SG_ 992 VCU_CreepDisable_stt 0;
BA_ "GenSigSendType" SG_ 409 Checksum_0x199 0;
BA_ "GenSigSendType" SG_ 409 Rolling_Counter_0x199 0;
BA_ "GenSigInvalidValue" SG_ 409 Rolling_Counter_0x199 15;
BA_ "GenSigSendType" SG_ 409 VCU_VehFailGrade_ERR 0;
BA_ "GenSigSendType" SG_ 409 VCU_BMS_HVOnOff_REQ 0;
BA_ "GenSigSendType" SG_ 409 VCU_Vehicle_Mode 0;
BA_ "GenSigSendType" SG_ 792 EAC_CompElecCurrV 0;
BA_ "GenSigInvalidValue" SG_ 792 EAC_CompElecCurrV 1;
BA_ "GenSigSendType" SG_ 792 EAC_CompStat 0;
BA_ "GenSigInvalidValue" SG_ 792 EAC_CompStat 15;
BA_ "GenSigStartValue" SG_ 792 EAC_CompStat 2;
BA_ "GenSigSendType" SG_ 792 EAC_CompElecPwrV 0;
BA_ "GenSigInvalidValue" SG_ 792 EAC_CompElecPwrV 1;
BA_ "GenSigSendType" SG_ 792 EAC_CompSpdIncrReq 0;
BA_ "GenSigSendType" SG_ 792 EAC_CompSpdV 0;
BA_ "GenSigInvalidValue" SG_ 792 EAC_CompSpdV 1;
BA_ "GenSigSendType" SG_ 792 EAC_CompElecPwr 0;
BA_ "GenSigInvalidValue" SG_ 792 EAC_CompElecPwr 255;
BA_ "GenSigSendType" SG_ 792 EAC_CompSpd 0;
BA_ "GenSigInvalidValue" SG_ 792 EAC_CompSpd 16383;
BA_ "GenSigSendType" SG_ 792 EAC_CompElecCurr 0;
BA_ "GenSigInvalidValue" SG_ 792 EAC_CompElecCurr 255;
BA_ "GenSigSendType" SG_ 792 EAC_CompFltStat 0;
BA_ "GenSigInvalidValue" SG_ 792 EAC_CompFltStat 15;
BA_ "GenSigSendType" SG_ 524 Checksum_0x20C 0;
BA_ "GenSigSendType" SG_ 524 Rolling_Counter_0x20C 0;
BA_ "GenSigInvalidValue" SG_ 524 Rolling_Counter_0x20C 15;
BA_ "GenSigSendType" SG_ 524 IPC_ODO 0;
BA_ "GenSigInvalidValue" SG_ 524 IPC_ODO 1048575;
BA_ "GenSigSendType" SG_ 703 IPC_TripA 0;
BA_ "GenSigInvalidValue" SG_ 703 IPC_TripA 65535;
BA_ "GenSigSendType" SG_ 703 IPC_AverageSpeedTripA 0;
BA_ "GenSigInvalidValue" SG_ 703 IPC_AverageSpeedTripA 4095;
BA_ "GenSigSendType" SG_ 703 IPC_AverageConsumptionTripA 0;
BA_ "GenSigInvalidValue" SG_ 703 IPC_AverageConsumptionTripA 1023;
BA_ "GenSigSendType" SG_ 703 IPC_ParkBrakeSts 0;
BA_ "GenSigInvalidValue" SG_ 703 IPC_ParkBrakeSts 3;
BA_ "GenSigSendType" SG_ 703 IPC_VehSpd 0;
BA_ "GenSigInvalidValue" SG_ 703 IPC_VehSpd 32767;
BA_ "GenSigSendType" SG_ 1087 IPC_Sec 0;
BA_ "GenSigInvalidValue" SG_ 1087 IPC_Sec 63;
BA_ "GenSigSendType" SG_ 1087 IPC_Min 0;
BA_ "GenSigInvalidValue" SG_ 1087 IPC_Min 63;
BA_ "GenSigSendType" SG_ 1087 IPC_Hour 0;
BA_ "GenSigInvalidValue" SG_ 1087 IPC_Hour 31;
BA_ "GenSigSendType" SG_ 1087 IPC_Day 0;
BA_ "GenSigInvalidValue" SG_ 1087 IPC_Day 31;
BA_ "GenSigStartValue" SG_ 1087 IPC_Day 1;
BA_ "GenSigSendType" SG_ 1087 IPC_Month 0;
BA_ "GenSigInvalidValue" SG_ 1087 IPC_Month 15;
BA_ "GenSigStartValue" SG_ 1087 IPC_Month 1;
BA_ "GenSigSendType" SG_ 1087 IPC_Year 0;
BA_ "GenSigInvalidValue" SG_ 1087 IPC_Year 255;
BA_ "GenSigSendType" SG_ 1087 IPC_SelfCheckStatus 0;
BA_ "GenSigSendType" SG_ 1074 Checksum_0x432 0;
BA_ "GenSigSendType" SG_ 1074 Rolling_Counter_0x432 0;
BA_ "GenSigInvalidValue" SG_ 1074 Rolling_Counter_0x432 15;
BA_ "GenSigSendType" SG_ 1074 MHU_FOTA_State 0;
BA_ "GenSigSendType" SG_ 1074 MHU_FOTA_Error_Code 0;
BA_ "GenSigSendType" SG_ 1027 Checksum_0x403 0;
BA_ "GenSigSendType" SG_ 1027 Rolling_Counter_0x403 0;
BA_ "GenSigInvalidValue" SG_ 1027 Rolling_Counter_0x403 15;
BA_ "GenSigSendType" SG_ 1027 MHU_SET_TCS_OnOff 2;
BA_ "GenSigInvalidValue" SG_ 1027 MHU_SET_TCS_OnOff 3;
BA_ "GenSigStartValue" SG_ 1027 MHU_SET_TCS_OnOff 2;
BA_ "GenSigSendType" SG_ 1027 MHU_SET_DrivingModeSwitch 2;
BA_ "GenSigSendType" SG_ 1027 MHU_SET_RegenLevel 2;
BA_ "GenSigStartValue" SG_ 1027 MHU_SET_RegenLevel 3;
BA_ "GenSigSendType" SG_ 1027 MHU_VCU_CreepDisable_stt 2;
BA_ "GenSigInvalidValue" SG_ 1027 MHU_VCU_CreepDisable_stt 3;
BA_ "GenSigStartValue" SG_ 1027 MHU_VCU_CreepDisable_stt 2;
BA_ "GenSigSendType" SG_ 1027 MHU_ChargeSetTargetSOC 2;
BA_ "GenSigInvalidValue" SG_ 1027 MHU_ChargeSetTargetSOC 127;
BA_ "GenSigStartValue" SG_ 1027 MHU_ChargeSetTargetSOC 100;
BA_ "GenSigSendType" SG_ 1027 MHU_HVACTurnON 2;
BA_ "GenSigInvalidValue" SG_ 1027 MHU_HVACTurnON 3;
BA_ "GenSigSendType" SG_ 1027 MHU_ChargeScheduleSet 2;
BA_ "GenSigStartValue" SG_ 1027 MHU_ChargeScheduleSet 2;
BA_ "GenSigSendType" SG_ 1027 MHU_ChargingRequest 2;
BA_ "GenSigStartValue" SG_ 1027 MHU_ChargingRequest 3;
BA_ "GenSigSendType" SG_ 1027 MHU_ValetMode_Activation 2;
BA_ "GenSigInvalidValue" SG_ 1027 MHU_ValetMode_Activation 254;
BA_ "GenSigInactiveValue" SG_ 1027 MHU_ValetMode_Activation 255;
BA_ "GenSigSendType" SG_ 1027 MHU_ValetMode_MaxSpeed 2;
BA_ "GenSigInvalidValue" SG_ 1027 MHU_ValetMode_MaxSpeed 2;
BA_ "GenSigInactiveValue" SG_ 1027 MHU_ValetMode_MaxSpeed 255;
BA_ "GenSigSendType" SG_ 811 CCU_TemperatureGearSts 0;
BA_ "GenSigInvalidValue" SG_ 811 CCU_TemperatureGearSts 63;
BA_ "GenSigStartValue" SG_ 811 CCU_TemperatureGearSts 7;
BA_ "GenSigSendType" SG_ 811 CCU_BlowMode_Sts 0;
BA_ "GenSigInvalidValue" SG_ 811 CCU_BlowMode_Sts 7;
BA_ "GenSigStartValue" SG_ 811 CCU_BlowMode_Sts 2;
BA_ "GenSigSendType" SG_ 811 CCU_Circulation_Sts 0;
BA_ "GenSigSendType" SG_ 811 CCU_AC_Req 0;
BA_ "GenSigInvalidValue" SG_ 811 CCU_AC_Req 3;
BA_ "GenSigSendType" SG_ 811 CCU_AC_Sts 0;
BA_ "GenSigSendType" SG_ 811 CCU_BlowerLevelSts 0;
BA_ "GenSigStartValue" SG_ 811 CCU_BlowerLevelSts 1;
BA_ "GenSigSendType" SG_ 811 CCU_FrontDefrostSts 0;
BA_ "GenSigSendType" SG_ 811 CCU_PTC_Req 0;
BA_ "GenSigInvalidValue" SG_ 811 CCU_PTC_Req 3;
BA_ "GenSigSendType" SG_ 811 CCU_PTC_Temperature 0;
BA_ "GenSigInvalidValue" SG_ 811 CCU_PTC_Temperature 1023;
BA_ "GenSigSendType" SG_ 811 CCU_CompSpdMEAS_Comp 0;
BA_ "GenSigInvalidValue" SG_ 811 CCU_CompSpdMEAS_Comp 8191;
BA_ "GenSigSendType" SG_ 811 CCU_PollutionSts 0;
BA_ "GenSigSendType" SG_ 811 CCU_ExternalTemperature 0;
BA_ "GenSigInvalidValue" SG_ 811 CCU_ExternalTemperature 255;
BA_ "GenSigStartValue" SG_ 811 CCU_ExternalTemperature 80;
BA_ "GenSigSendType" SG_ 811 CCU_evaporator_Temperature 0;
BA_ "GenSigInvalidValue" SG_ 811 CCU_evaporator_Temperature 31;
BA_ "GenSigStartValue" SG_ 811 CCU_evaporator_Temperature 10;
BA_ "GenSigSendType" SG_ 811 CCU_ExternalTemperatureFailSts 0;
BA_ "GenSigInvalidValue" SG_ 811 CCU_ExternalTemperatureFailSts 1;
BA_ "GenSigStartValue" SG_ 811 CCU_ExternalTemperatureFailSts 1;
BA_ "GenSigSendType" SG_ 929 BMS_MHU_Rand_Num_Byte_0 1;
BA_ "GenSigSendType" SG_ 929 BMS_MHU_Rand_Num_Byte_1 1;
BA_ "GenSigSendType" SG_ 929 BMS_MHU_Rand_Num_Byte_2 1;
BA_ "GenSigSendType" SG_ 929 BMS_MHU_Rand_Num_Byte_3 1;
BA_ "GenSigSendType" SG_ 929 BMS_MHU_Rand_Num_Byte_4 1;
BA_ "GenSigSendType" SG_ 929 BMS_MHU_Rand_Num_Byte_5 1;
BA_ "GenSigSendType" SG_ 929 BMS_MHU_Rand_Num_Byte_6 1;
BA_ "GenSigSendType" SG_ 929 BMS_MHU_Rand_Num_Byte_7 1;
BA_ "GenSigSendType" SG_ 930 MHU_BMS_Enc_Result_Byte_0 1;
BA_ "GenSigSendType" SG_ 930 MHU_BMS_Enc_Result_Byte_1 1;
BA_ "GenSigSendType" SG_ 930 MHU_BMS_Enc_Result_Byte_2 1;
BA_ "GenSigSendType" SG_ 930 MHU_BMS_Enc_Result_Byte_3 1;
BA_ "GenSigSendType" SG_ 930 MHU_BMS_Enc_Result_Byte_4 1;
BA_ "GenSigSendType" SG_ 930 MHU_BMS_Enc_Result_Byte_5 1;
BA_ "GenSigSendType" SG_ 930 MHU_BMS_Enc_Result_Byte_6 1;
BA_ "GenSigSendType" SG_ 930 MHU_BMS_Enc_Result_Byte_7 1;
BA_ "GenSigSendType" SG_ 274 Checksum_0x112 0;
BA_ "GenSigSendType" SG_ 274 Rolling_Counter_0x112 0;
BA_ "GenSigInvalidValue" SG_ 274 Rolling_Counter_0x112 15;
BA_ "GenSigSendType" SG_ 274 STAT_Terminal 0;
BA_ "GenSigSendType" SG_ 274 STAT_CL30s_L_Reserved 0;
BA_ "GenSigStartValue" SG_ 274 STAT_CL30s_L_Reserved 3;
BA_ "GenSigSendType" SG_ 266 Checksum_0x10a 0;
BA_ "GenSigSendType" SG_ 266 Rolling_Counter_0x10a 0;
BA_ "GenSigInvalidValue" SG_ 266 Rolling_Counter_0x10a 15;
BA_ "GenSigSendType" SG_ 266 BCM_LVTop_up 0;
BA_ "GenSigSendType" SG_ 266 Ubatt_Reserved 0;
BA_ "GenSigInvalidValue" SG_ 266 Ubatt_Reserved 16383;
BA_ "GenSigStartValue" SG_ 266 Ubatt_Reserved 9000;
BA_ "GenSigSendType" SG_ 133 Checksum_0x85 0;
BA_ "GenSigSendType" SG_ 133 Rolling_Counter_0x85 0;
BA_ "GenSigInvalidValue" SG_ 133 Rolling_Counter_0x85 15;
BA_ "GenSigSendType" SG_ 133 ACM_Crash_Sts 0;
BA_ "GenSigSendType" SG_ 133 ACM_Airbag_Deployment_Status 0;
BA_ "GenSigSendType" SG_ 133 ACM_Crash_Intensity 0;
BA_ "GenSigSendType" SG_ 133 ACM_Front_Crash 0;
BA_ "GenSigSendType" SG_ 133 ACM_DriverSide_Crash 0;
BA_ "GenSigSendType" SG_ 133 ACM_PassSide_Crash 0;
BA_ "GenSigSendType" SG_ 133 ACM_Rear_Crash 0;
BA_ "GenSigSendType" SG_ 133 ACM_Rollover_Crash 0;
BA_ "GenSigSendType" SG_ 834 Checksum_0x342 0;
BA_ "GenSigSendType" SG_ 834 Rolling_Counter_0x342 0;
BA_ "GenSigInvalidValue" SG_ 834 Rolling_Counter_0x342 15;
BA_ "GenSigSendType" SG_ 834 ABS_LRWhlSpdRaw 0;
BA_ "GenSigInvalidValue" SG_ 834 ABS_LRWhlSpdRaw 32767;
BA_ "GenSigSendType" SG_ 834 ABS_LRWhlSpdRawValid 0;
BA_ "GenSigSendType" SG_ 834 ABS_RRWhlSpdRaw 0;
BA_ "GenSigInvalidValue" SG_ 834 ABS_RRWhlSpdRaw 32767;
BA_ "GenSigSendType" SG_ 834 ABS_RRWhlSpdRawValid 0;
BA_ "GenSigSendType" SG_ 834 ABS_VehSpd 0;
BA_ "GenSigInvalidValue" SG_ 834 ABS_VehSpd 32767;
BA_ "GenSigSendType" SG_ 834 ABS_VehSpdValid 0;
BA_ "GenSigSendType" SG_ 1299 BMS_sourceID 0;
BA_ "GenSigSendType" SG_ 1299 BMS_CBV 0;
BA_ "GenSigSendType" SG_ 1299 BMS_Data0 0;
BA_ "GenSigSendType" SG_ 1299 BMS_Data1 0;
BA_ "GenSigSendType" SG_ 1299 BMS_Data2 0;
BA_ "GenSigSendType" SG_ 1299 BMS_Data3 0;
BA_ "GenSigSendType" SG_ 1299 BMS_Data4 0;
BA_ "GenSigSendType" SG_ 1299 BMS_Data5 0;
BA_ "GenSigSendType" SG_ 1324 VCU_sourceID 0;
BA_ "GenSigSendType" SG_ 1324 VCU_CBV 0;
BA_ "GenSigSendType" SG_ 1324 VCU_Data0 0;
BA_ "GenSigSendType" SG_ 1324 VCU_Data1 0;
BA_ "GenSigSendType" SG_ 1324 VCU_Data2 0;
BA_ "GenSigSendType" SG_ 1324 VCU_Data3 0;
BA_ "GenSigSendType" SG_ 1324 VCU_Data4 0;
BA_ "GenSigSendType" SG_ 1324 VCU_Data5 0;
BA_ "GenSigSendType" SG_ 1341 PDU_DCDC_sourceID 0;
BA_ "GenSigSendType" SG_ 1341 PDU_DCDC_CBV 0;
BA_ "GenSigSendType" SG_ 1341 PDU_DCDC_Data0 0;
BA_ "GenSigSendType" SG_ 1341 PDU_DCDC_Data1 0;
BA_ "GenSigSendType" SG_ 1341 PDU_DCDC_Data2 0;
BA_ "GenSigSendType" SG_ 1341 PDU_DCDC_Data3 0;
BA_ "GenSigSendType" SG_ 1341 PDU_DCDC_Data4 0;
BA_ "GenSigSendType" SG_ 1341 PDU_DCDC_Data5 0;
BA_ "GenSigSendType" SG_ 1307 EDS_sourceID 0;
BA_ "GenSigSendType" SG_ 1307 EDS_CBV 0;
BA_ "GenSigSendType" SG_ 1307 EDS_Data0 0;
BA_ "GenSigSendType" SG_ 1307 EDS_Data1 0;
BA_ "GenSigSendType" SG_ 1307 EDS_Data2 0;
BA_ "GenSigSendType" SG_ 1307 EDS_Data3 0;
BA_ "GenSigSendType" SG_ 1307 EDS_Data4 0;
BA_ "GenSigSendType" SG_ 1307 EDS_Data5 0;
BA_ "GenSigSendType" SG_ 1311 EVCC_sourceID 0;
BA_ "GenSigSendType" SG_ 1311 EVCC_CBV 0;
BA_ "GenSigSendType" SG_ 1311 EVCC_Data0 0;
BA_ "GenSigSendType" SG_ 1311 EVCC_Data1 0;
BA_ "GenSigSendType" SG_ 1311 EVCC_Data2 0;
BA_ "GenSigSendType" SG_ 1311 EVCC_Data3 0;
BA_ "GenSigSendType" SG_ 1311 EVCC_Data4 0;
BA_ "GenSigSendType" SG_ 1311 EVCC_Data5 0;
BA_ "GenSigSendType" SG_ 1282 GW_sourceID 0;
BA_ "GenSigSendType" SG_ 1282 GW_CBV 0;
BA_ "GenSigSendType" SG_ 1282 GW_Data0 0;
BA_ "GenSigSendType" SG_ 1282 GW_Data1 0;
BA_ "GenSigSendType" SG_ 1282 GW_Data2 0;
BA_ "GenSigSendType" SG_ 1282 GW_Data3 0;
BA_ "GenSigSendType" SG_ 1282 GW_Data4 0;
BA_ "GenSigSendType" SG_ 1282 GW_Data5 0;
BA_ "GenSigSendType" SG_ 1683 BMS_DiagReqData0 0;
BA_ "GenSigSendType" SG_ 1683 BMS_DiagReqData1 0;
BA_ "GenSigSendType" SG_ 1683 BMS_DiagReqData2 0;
BA_ "GenSigSendType" SG_ 1683 BMS_DiagReqData3 0;
BA_ "GenSigSendType" SG_ 1683 BMS_DiagReqData4 0;
BA_ "GenSigSendType" SG_ 1683 BMS_DiagReqData5 0;
BA_ "GenSigSendType" SG_ 1683 BMS_DiagReqData6 0;
BA_ "GenSigSendType" SG_ 1683 BMS_DiagReqData7 0;
BA_ "GenSigSendType" SG_ 1555 BMS_DiagRespData0 0;
BA_ "GenSigSendType" SG_ 1555 BMS_DiagRespData1 0;
BA_ "GenSigSendType" SG_ 1555 BMS_DiagRespData2 0;
BA_ "GenSigSendType" SG_ 1555 BMS_DiagRespData3 0;
BA_ "GenSigSendType" SG_ 1555 BMS_DiagRespData4 0;
BA_ "GenSigSendType" SG_ 1555 BMS_DiagRespData5 0;
BA_ "GenSigSendType" SG_ 1555 BMS_DiagRespData6 0;
BA_ "GenSigSendType" SG_ 1555 BMS_DiagRespData7 0;
BA_ "GenSigSendType" SG_ 1791 GW_DiagFunctionalAddressingData0 0;
BA_ "GenSigSendType" SG_ 1791 GW_DiagFunctionalAddressingData1 0;
BA_ "GenSigSendType" SG_ 1791 GW_DiagFunctionalAddressingData2 0;
BA_ "GenSigSendType" SG_ 1791 GW_DiagFunctionalAddressingData3 0;
BA_ "GenSigSendType" SG_ 1791 GW_DiagFunctionalAddressingData4 0;
BA_ "GenSigSendType" SG_ 1791 GW_DiagFunctionalAddressingData5 0;
BA_ "GenSigSendType" SG_ 1791 GW_DiagFunctionalAddressingData6 0;
BA_ "GenSigSendType" SG_ 1791 GW_DiagFunctionalAddressingData7 0;
VAL_ 673 Rolling_Counter_0x2A1 15 "Invalid";
VAL_ 673 ODS_Status 3 "Reserved" 2 "ODS disconnected" 1 "Seat Occupied" 0 "Seat Not Occupied";
VAL_ 673 EVCC_MHU_CharSchSetFeedBack 3 "invalid " 2 "No Schedule" 1 "Schedule Success" 0 "No action";
VAL_ 673 EVCC_ChargeGunSts 1 "Plug In" 0 "no Plug in";
VAL_ 673 EVCC_ChargeMode 2 "DC Mode " 1 "AC Mode " 0 "Default";
VAL_ 673 EVCC_CP_Sts 12 "F~" 11 "E~" 10 "D~" 9 "C~" 8 "B~" 7 "A~" 6 "F" 5 "E" 4 "D" 3 "C" 2 "B" 1 "A" 0 "No CP";
VAL_ 673 EVCC_PP_Value 7 "CC GND" 6 "1500" 5 "680" 4 "220" 3 "100" 2 "Connection" 1 "Half Connection " 0 "No Connection";
VAL_ 673 EVCC_Lock_Sts 4 "Error" 3 "Unlocking" 2 "Locked" 1 "Locking " 0 "Unlock";
VAL_ 682 Rolling_Counter_0x2AA 15 "Invalid";
VAL_ 682 EVCC_PLC_CommSts 2 "PLC communication Fail" 1 "PLC communication Success" 0 "No PLC communication";
VAL_ 682 EVCC_DC_ChargeProcess 10 "Charge Error" 9 "After Charge" 8 "Charge Stoping" 7 "Charging" 6 "Precharge waiting" 5 "Insulation Monitor From Charge Station" 4 "Information exchange" 3 "Charging authentication" 2 "TCP Connecting" 1 "PLC Linking" 0 "No Charge";
VAL_ 682 EVCC_BMS_InsulationMonReq 1 "Close" 0 "invalid";
VAL_ 683 Rolling_Counter_0x2AB 15 "Invalid";
VAL_ 683 EVCC_OBC_PowerReq 127 "Invalid";
VAL_ 683 EVCC_OBC_VoltageReq 8191 "Invalid";
VAL_ 683 EVCC_OBC_CurrentReq 1023 "Invalid";
VAL_ 683 EVCC_OBC_Control 1 "enable" 0 "disable";
VAL_ 683 EVCC_AC_ChargeSts 4 "Charge Err" 3 "Afer Charge" 2 "Charge Stoping" 1 "Charging " 0 "No charge";
VAL_ 536 Rolling_Counter_0x218 15 "Invalid";
VAL_ 536 BMS_DC_Charge_input 1 "Valid" 0 "invalid";
VAL_ 536 BMS_DC_Charge_Req 1 "Valid" 0 "invalid";
VAL_ 536 BMS_DC_ChargeRelay_Sts 4 "stuck open" 3 "stuck closed" 2 "closed" 1 "open" 0 "reserved";
VAL_ 534 Rolling_Counter_0x216 15 "Invalid";
VAL_ 534 BMS_RemainChargeTime 16383 "Invalid";
VAL_ 534 BMS_ChgVoltage_REQ 16383 "Invalid";
VAL_ 534 BMS_ChgCurrent_REQ 65535 "Invalid";
VAL_ 294 Rolling_Counter_0x126 15 "Invalid";
VAL_ 294 BMS_AllowChgCurrPeak 65535 "Invalid";
VAL_ 294 BMS_AllowChgCurr 65535 "Invalid";
VAL_ 521 Rolling_Counter_0x209 15 "Invalid";
VAL_ 521 BMS_MaxDischgPwr_ALW 4095 "Invalid";
VAL_ 521 BMS_MaxChgPwr_ALW 4095 "Invalid";
VAL_ 521 BMS_MaxDischgPwr_Peak 4095 "Invalid";
VAL_ 521 BMS_MaxChgPwr_Peak 4095 "Invalid";
VAL_ 585 Rolling_Counter_0x249 15 "Invalid";
VAL_ 584 Rolling_Counter_0x248 15 "Invalid";
VAL_ 584 BMS_FlowRate_Req 255 "Invalid";
VAL_ 584 BMS_CoolPwrDemand 4095 "Invalid";
VAL_ 584 BMS_VCU_ValveOnOff_Req 1 "open " 0 "close";
VAL_ 584 BMS_HeatPwrDemand 4095 "Invalid";
VAL_ 584 BMS_VCU_PTCOnOff_Req 1 "ON" 0 "OFF";
VAL_ 518 Rolling_Counter_0x206 15 "Invalid";
VAL_ 518 BMS_MaxMinDiffCellVol 8191 "Invalid value if diff > 500mV";
VAL_ 818 Rolling_Counter_0x332 15 "Invalid";
VAL_ 818 BMS_PackTemp_Infor 255 "Invalid";
VAL_ 816 Rolling_Counter_0x330 15 "Invalid";
VAL_ 816 BMS_ContactorAging 2 "Fault: counter reach 98%" 1 "Warning: counter reach 90%" 0 "Normal";
VAL_ 374 Rolling_Counter_0x176 15 "Invalid";
VAL_ 374 BMS_HVLinkVol_MEAS 65535 "Invalid";
VAL_ 374 BMS_HVPackVol_MEAS 65535 "Invalid";
VAL_ 375 Rolling_Counter_0x177 15 "Invalid";
VAL_ 375 BMS_HVBusVol_MEAS 65535 "Invalid";
VAL_ 375 BMS_HVFuseVol_MEAS 65535 "Invalid";
VAL_ 372 Rolling_Counter_0x174 15 "Invalid";
VAL_ 372 BMS_PackCur_MEAS 65535 "Invalid";
VAL_ 533 Rolling_Counter_0x215 15 "Invalid";
VAL_ 533 BMS_HWCrash_Sts 1 "Crash " 0 "No Crash";
VAL_ 533 BMS_HVIL_STS 2 "short to ground" 1 "Open & short to battery" 0 "Closed";
VAL_ 533 BMS_IGN_Sts 1 "ON " 0 "OFF";
VAL_ 533 BMS_Sys_STS 8 "Invalid" 7 "Failure, unable to operate" 6 "BCU Sleep mode" 5 "Successful Power Down" 4 "Power Down process" 3 "Successful Power Down of HV" 2 "Successful High Voltage Power Up" 1 "Self-check passes, can be high-voltage" 0 "Initialization of power on, self-checking";
VAL_ 533 BMS_HVOnOff_STS 3 "Fail to HV on " 2 "HV On " 1 "Precharge " 0 "HV Off";
VAL_ 533 BMS_Balance_STS 1 "active " 0 "Inactive";
VAL_ 533 BMS_BatBalance_ERR 1 "normal " 0 "Error";
VAL_ 533 BMS_ISU_Status 3 "Level3(<100 Ohms/V)" 2 "Level2(<200 Ohms/V)" 1 "Level1 <500 Ohms/V ~ >200 Ohms/V" 0 "Normal (> 500 Ohms/V)";
VAL_ 533 BMS_ERR_LEV 7 "Battery locked -Reserved" 6 "Fault, needs Shutdown and Wakeup" 5 "Emergency off condition" 4 "Delayed power down with FTTI" 3 "Power down without FTTI" 2 "Limp Home" 1 " Warning (any warning in system)" 0 "No error";
VAL_ 533 BMS_HV_Sts 4 "AC Charging" 3 "DC Charging" 2 "HV ON" 1 "Precharge" 0 "HV Off";
VAL_ 931 BMS_MHU_Auth_Sts 2 "failed " 1 "pass " 0 "init";
VAL_ 532 Rolling_Counter_0x214 15 "Invalid";
VAL_ 532 BMS_Display_SOC 1023 "Invalid";
VAL_ 549 Rolling_Counter_0x225 15 "Invalid";
VAL_ 549 CDM_bAcvCanComStblMon 1 "Error" 0 "No error";
VAL_ 549 FRMo_bErrHvbatStReqExtMon 1 "Error" 0 "No error";
VAL_ 549 FRMo_bErrChrgnAllwdExtMon 1 "Error" 0 "No error";
VAL_ 549 FRMo_bErrVehCrashStExtMon 1 "Error" 0 "No error";
VAL_ 549 CDM_bErrComctnLossCanMon 1 "Error" 0 "No error";
VAL_ 549 CTCMon_bErrCtctrSopcMon 1 "Error" 0 "No error";
VAL_ 549 CTCMon_bInvldCtctrHisdIFbMon 1 "Error" 0 "No error";
VAL_ 549 CTCMon_bInvldCtctrLosdUFbMon 1 "Error" 0 "No error";
VAL_ 549 CTM_bErrCellTDifMaxMon 1 "Error" 0 "No error";
VAL_ 549 CTM_bErrCellTMaxMon 1 "Error" 0 "No error";
VAL_ 549 CTM_bErrCellTMinMon 1 "Error" 0 "No error";
VAL_ 549 CTM_bErrThrwyPredMon 1 "Error" 0 "No error";
VAL_ 549 CUM_bErrCellUDifMaxMon 1 "Error" 0 "No error";
VAL_ 549 CUM_bErrCellUMaxMon 1 "Error" 0 "No error";
VAL_ 549 CUM_bErrCellUMinMon 1 "Error" 0 "No error";
VAL_ 549 CUM_bErrCellUProtnMaxNvMon 1 "Error" 0 "No error";
VAL_ 549 CUM_bErrCellUProtnMinNvMon 1 "Error" 0 "No error";
VAL_ 549 CUM_bErrPackUImplyMon 1 "Error" 0 "No error";
VAL_ 549 EHPMon_bRdyHvilMon 1 "Error" 0 "No error";
VAL_ 549 EHPMon_bErrWlddNegNvMon 1 "Error" 0 "No error";
VAL_ 549 EHPMon_bErrWlddPosNvMon 1 "Error" 0 "No error";
VAL_ 549 EHPMon_bErrWlddPrechNvMon 1 "Error" 0 "No error";
VAL_ 549 EHPMon_bErrHvilMon 1 "Error" 0 "No error";
VAL_ 549 EHPMon_bErrHvilShoMon 1 "Error" 0 "No error";
VAL_ 549 EHPMon_bErrPackIslnRNvMon 1 "Error" 0 "No error";
VAL_ 549 EHPMon_bErrVehCrashNvMon 1 "Error" 0 "No error";
VAL_ 549 EHPMon_bErrVehIslnRNvMon 1 "Error" 0 "No error";
VAL_ 549 FRMo_bErrMemStorgNvMon 1 "Error" 0 "No error";
VAL_ 549 L1IM_bErrClmp30MaxMonInp 1 "Error" 0 "No error";
VAL_ 549 L1IM_bErrClmp30MinMonInp 1 "Error" 0 "No error";
VAL_ 549 L1IM_bErrCtctrDtrtMonInp 1 "Error" 0 "No error";
VAL_ 549 L1IM_bErrUActImplyMonInp 1 "Error" 0 "No error";
VAL_ 549 MCCM_bAcvMdulCtlrStsMon 1 "Error" 0 "No error";
VAL_ 549 MCCM_bErrLntecSngFltMon 1 "Error" 0 "No error";
VAL_ 549 MCCM_bErrLntecLtntFltMon 1 "Error" 0 "No error";
VAL_ 549 MCCM_bErrMdulCellSnsrCfgMon 1 "Error" 0 "No error";
VAL_ 549 MCCM_bErrMdulCtlrComMon 1 "Error" 0 "No error";
VAL_ 549 MCCM_bErrSnsrTEltlMon 1 "Error" 0 "No error";
VAL_ 549 MCCM_bWarnSnsrTEltlMon 1 "Error" 0 "No error";
VAL_ 549 PCM_bRdySnsrIMon 1 "Error" 0 "No error";
VAL_ 549 PCM_bErrPackEFlowMaxLimMon 1 "Error" 0 "No error";
VAL_ 549 PCM_bErrPackIChDchaMaxLimMon 1 "Error" 0 "No error";
VAL_ 549 PCM_bErrSnsrIImplyMon 1 "Error" 0 "No error";
VAL_ 549 FRMo_bErrSnsrI1ExtMon 1 "Error" 0 "No error";
VAL_ 549 PCM_bInvldSnsrI1Mon 1 "Error" 0 "No error";
VAL_ 549 PCM_bInvldSnsrI2Mon 1 "Error" 0 "No error";
VAL_ 549 FRMo_bErrSopcLvl3Mon 1 "Error" 0 "No error";
VAL_ 549 BMS_FRMo_Reserved_1 1 "Error" 0 "No error";
VAL_ 549 BMS_FRMo_Reserved_2 1 "Error" 0 "No error";
VAL_ 549 BMS_FRMo_Reserved_3 1 "Error" 0 "No error";
VAL_ 549 BMS_FRMo_Reserved_4 1 "Error" 0 "No error";
VAL_ 549 BMS_FRMo_Reserved_5 1 "Error" 0 "No error";
VAL_ 293 Rolling_Counter_0x125 15 "Invalid";
VAL_ 293 BMS_AllowDischgCurr 65535 "Invalid";
VAL_ 293 BMS_AllowDischgCurrPeak 65535 "Invalid";
VAL_ 885 Rolling_Counter_0x375 15 "Invalid";
VAL_ 885 BMS_MainPosRelay_ERR 1 "normal " 0 "Error";
VAL_ 885 BMS_MainPosRelay_STS 4 "stuck open" 3 "stuck closed" 2 "closed" 1 "open" 0 "reserved";
VAL_ 885 BMS_PreChgRelay_ERR 1 "normal " 0 "error";
VAL_ 885 BMS_PreChgRelay_STS 4 "stuck open" 3 "stuck closed" 2 "closed" 1 "open" 0 "reserved";
VAL_ 885 BMS_TotalNegRelay_STS 4 "stuck open" 3 "stuck closed" 2 "closed" 1 "open" 0 "reserved";
VAL_ 885 BMS_TotalNegRelay_ERR 1 "normal " 0 "Error";
VAL_ 517 Rolling_Counter_0x205 15 "Invalid";
VAL_ 517 BMS_MaxCellVol 8191 "Invalid";
VAL_ 517 BMS_CellNumMaxCellVol 0 "Invalid";
VAL_ 517 BMS_MinCellVol 8191 "Invalid";
VAL_ 517 BMS_CellNumMinCellVol 0 "Invalid";
VAL_ 581 Rolling_Counter_0x245 15 "Invalid";
VAL_ 581 BMS_PackTemp 255 "Invalid";
VAL_ 581 BMS_MaxMinDiffCellTemp 255 "Diff Temp";
VAL_ 581 BMS_MaxCellTemp 255 "Invalid";
VAL_ 581 BMS_MinCellTemp 255 "Invalid";
VAL_ 581 BMS_ProbeNumMaxCellTemp 63 "Invalid" 62 "Error" 0 "Invalid";
VAL_ 581 BMS_ProbeNumMinCellTemp 63 "Invalid" 62 "Error" 0 "Invalid";
VAL_ 773 Rolling_Counter_0x305 15 "Invalid";
VAL_ 773 BMS_VCU_Insulation_Mon_Sts 1 "OFF" 0 "ON";
VAL_ 1171 BMS_DischargeCurrent_Limited 1 "Limited" 0 "Not Limited ";
VAL_ 1171 BMS_Warning_Flag_Reserved_07 1 "Warning" 0 "No warning";
VAL_ 1171 BMS_Warning_Flag_Reserved_11 1 "Warning" 0 "No warning";
VAL_ 1171 BMS_Warning_Flag_Reserved_10 1 "Warning" 0 "No warning";
VAL_ 1171 BMS_Warning_Flag_Reserved_09 1 "Warning" 0 "No warning";
VAL_ 1171 BMS_Warning_Flag_Reserved_13 1 "Warning" 0 "No warning";
VAL_ 1171 BMS_Warning_Flag_Reserved_12 1 "Warning" 0 "No warning";
VAL_ 1171 BMS_Warning_Flag_Reserved_06 1 "Warning" 0 "No warning";
VAL_ 1171 BMS_Warning_Flag_Reserved_05 1 "Warning" 0 "No warning";
VAL_ 1171 BMS_Warning_Flag_Reserved_04 1 "Warning" 0 "No warning";
VAL_ 1171 BMS_MalfunctionSts 1 "Malfunction indicator lamp ON" 0 "Malfunction indicator lamp OFF";
VAL_ 1171 BMS_LowBattery 2 "Extremely low level" 1 "Low level" 0 "No warning";
VAL_ 1171 BMS_BatteryReplacement 1 "Warning" 0 "No warning";
VAL_ 1171 BMS_PackTempSts 2 "Under Temperature Warning" 1 "Over Temperature Warning" 0 "No warning";
VAL_ 1171 BMS_ThermalRunaway 1 "Warning" 0 "No warning";
VAL_ 1171 Rolling_Counter_0x493 15 "Invalid";
VAL_ 550 BMS_QMMo_Reserved_9 1 "Error" 0 "No Error";
VAL_ 550 BMS_QMMo_Reserved_8 1 "Error" 0 "No Error";
VAL_ 550 BMS_QMMo_Reserved_7 1 "Error" 0 "No Error";
VAL_ 550 BMS_QMMo_Reserved_6 1 "Error" 0 "No Error";
VAL_ 550 BMS_QMMo_Reserved_5 1 "Error" 0 "No Error";
VAL_ 550 BMS_QMMo_Reserved_4 1 "Error" 0 "No Error";
VAL_ 550 BMS_QMMo_Reserved_3 1 "Error" 0 "No Error";
VAL_ 550 BMS_QMMo_Reserved_2 1 "Error" 0 "No Error";
VAL_ 550 BMS_QMMo_Reserved_11 1 "Error" 0 "No Error";
VAL_ 550 BMS_QMMo_Reserved_10 1 "Error" 0 "No Error";
VAL_ 550 BMS_QMMo_Reserved_1 1 "Error" 0 "No Error";
VAL_ 550 BMS_QMMo_Reserved_0 1 "Error" 0 "No Error";
VAL_ 550 Rolling_Counter_0x226 15 "Invalid";
VAL_ 1109 Rolling_Counter_0x455 15 "Invalid";
VAL_ 1109 BMS_PackInsu_ERR 2 "Lv2-Short to vbat and open line" 1 "Lv1 - Short to ground" 0 "Lv0-No Err";
VAL_ 1109 BMS_CellVoltDiff_ERR 3 "Level3 Reserve" 2 "Level2 Serious alarm value" 1 "Level1 General alarm value" 0 "Level0 Normal";
VAL_ 1109 BMS_PackOverCurr_ERR 2 "Serious Alarm value" 1 "General Alarm Value" 0 "Normal";
VAL_ 1109 BMS_HVIL_Err 3 "Level3" 2 "Level2" 1 "Level1" 0 "Normal";
VAL_ 1109 BMS_CellHighVol_ERR 3 "Level3 Reserve" 2 "Level2 Serious alarm value" 1 "Level1 General alarm value" 0 "Level0 Normal";
VAL_ 1109 BMS_CellLowVol_ERR 3 "Level3 Reserve" 2 "Level2 Serious alarm value" 1 "Level1 General alarm value" 0 "Level0 Normal";
VAL_ 1109 BMS_PackLowVol_ERR 3 "Level3 Reserve" 2 "Level2 Serious alarm value" 1 "Level1 General alarm value" 0 "Level0 Normal";
VAL_ 1109 BMS_PackHighVol_ERR 3 "Level3 Reserve" 2 "Level2 Serious alarm value" 1 "Level1 General alarm value" 0 "Level0 Normal";
VAL_ 1109 BMS_ProbeHighTemp_ERR 3 "Level3 Reserve" 2 "Level2 Serious alarm value" 1 "Level1 General alarm value" 0 "Level0 Normal";
VAL_ 1109 BMS_ProbeTempDiff_ERR 3 "Level3 Reserve" 2 "Level2 Serious alarm value" 1 "Level1 General alarm value" 0 "Level0 Normal";
VAL_ 1109 BMS_FuseStatus_ERR 1 "Fuse blow" 0 "Normal";
VAL_ 1109 BMS_ProbeLowTemp_ERR 3 "Level3 Reserve" 2 "Level2 Serious alarm value" 1 "Level1 General alarm value" 0 "Level0 Normal";
VAL_ 1504 softwore_version 1 "valid" 0 "Invalid";
VAL_ 523 Rolling_Counter_0x20B 15 "Invalid";
VAL_ 523 DCDC_Sys_STS 6 "(Off)" 5 "(Fault,Cannot work)" 3 "(Successful High Voltage Power Up)" 1 "(Self-Check passes, can be high-voltage)" 0 "(Initialization of power on, self-checking)";
VAL_ 523 DCDC_Voltage_Input 1023 "Invalid";
VAL_ 523 DCDC_Current_Input 255 "Invalid";
VAL_ 523 DCDC_Voltage_Output 1023 "Invalid";
VAL_ 523 DCDC_Current_Output 255 "Invalid";
VAL_ 523 DCDC_Output_STS 2 "fault" 1 "normal" 0 "stop";
VAL_ 523 DCDC_Temp 255 "Invalid";
VAL_ 854 Rolling_Counter_0x356 15 "Invalid";
VAL_ 854 OBC_WorkStatus 7 "CHG_LOCK_FAULT_STATE " 6 "CHG_RECV_FAULT_STATE " 5 " CHG_SLEEP_STATE" 4 "CHG_CHARG_OVER_STATE" 3 "CHG_CHARG_CV_STATE" 2 "CHG_CHARG_CC_STATE" 1 "CHG_STANDBY_STATE" 0 "Initial";
VAL_ 854 OBC_Sys_STS 3 "fault" 2 "warning" 1 "ok" 0 "init";
VAL_ 854 OBC_StartStatus 1 "Close Output" 0 "Start Output";
VAL_ 854 OBC_ChargeConnetState 3 "Invalid" 2 "connect" 1 "half connect" 0 "disconnect";
VAL_ 870 Rolling_Counter_0x366 15 "Invalid";
VAL_ 870 OBC_CP_State_reserved 5 "StataF" 4 "StataE" 3 "StataD" 2 "StataC" 1 "StataB" 0 "StataA";
VAL_ 870 OBC_Charge_air_temp 255 "Invalid";
VAL_ 870 OBC_Temp_Reserved 255 "Invalid";
VAL_ 646 Rolling_Counter_0x286 15 "Invalid";
VAL_ 646 OBC_OUT_DC_V 65535 "Invalid";
VAL_ 646 OBC_OUT_DC_I 16383 "Invalid";
VAL_ 646 OBC_DCCharge_line_V 65535 "Invalid";
VAL_ 630 Rolling_Counter_0x276 15 "Invalid";
VAL_ 630 OBC_Input_U 65535 "Invalid";
VAL_ 630 OBC_IN_Main_V_Reserved 65535 "Invalid";
VAL_ 630 OBC_IN_Main_I_Reserved 1023 "Invalid";
VAL_ 662 Rolling_Counter_0x296 15 "Invalid";
VAL_ 662 OBC_MaxOutputChgU 8191 "Invalid";
VAL_ 662 OBC_MaxOutputChgI 511 "Invalid";
VAL_ 662 OBC_MaxOutputPwr 127 "Invalid";
VAL_ 1142 OBC_FailGrade_ERR 5 "Level5,Fatal fault" 4 "Level4,Serious fault" 3 "Level3,General fault" 2 "Level2,Minor fault" 1 "Level1,slight fault" 0 "No Fault";
VAL_ 1142 OBC_ErrorFlag_Reserved 11 "FAULT_MUTEX " 10 "FAULT_OUT_OV " 9 "FAULT_OUT_UV" 8 "FAULT_PFC_UVPFC" 7 "FAULT_PFC_OVPFC" 6 "FAULT_IN_OV" 5 "FAULT_IN_UV" 4 "FAULT_COMM_OUT" 3 "FAULT_OUT_OC " 2 " FAULT_OTP_ALL " 1 "FAULT_OTP_RT " 0 "Initial";
VAL_ 1142 OBC_Hardware_ERR 1 "Error" 0 "Normal";
VAL_ 1142 OBC_OTemp_ERR 2 "Level2 - stop" 1 "Level1 - limit" 0 "Normal";
VAL_ 1142 OBC_OCofOut_ERR_Reserved 1 "Error" 0 "Normal";
VAL_ 1142 OBC_SlwChgSktOTemp_ERR_Reserved 1 "Error" 0 "Normal";
VAL_ 1142 OBC_CANcomoverT_ERR 1 "Error" 0 "Normal";
VAL_ 1142 OBC_UVofIn_ERR_Reserved 1 "Error" 0 "Normal";
VAL_ 1142 OBC_OVofIn_ERR_Reserved 1 "Error" 0 "Normal";
VAL_ 1142 OBC_OVofPFC_ERR_Reserved 1 "Error" 0 "Normal";
VAL_ 1142 OBC_UVofPFC_ERR_Reserved 1 "Error" 0 "Normal";
VAL_ 1142 OBC_UVofOut_ERR 1 "Error" 0 "Normal";
VAL_ 1142 OBC_OVofOut_ERR 1 "Error" 0 "Normal";
VAL_ 840 EDS_bus_Volt_FWD 16383 "Invalid";
VAL_ 840 EDS_bus_Curr_FWD 65535 "Invalid";
VAL_ 840 EDS_HVIL_STS_FWD 3 "short to ground" 2 "short to battery" 1 "Open" 0 "Closed";
VAL_ 504 Rolling_Counter_0x1F8 15 "Invalid";
VAL_ 504 EDS_output_trq_FR 65535 "Invalid";
VAL_ 504 EDS_output_trqValid_FR 1 "valid" 0 "invalid";
VAL_ 504 EDS_Spd_FR 65535 "Invalid";
VAL_ 504 EDS_SpdValid_FR 1 "valid" 0 "invalid";
VAL_ 504 EDS_MotorDriveSts_FR 3 "Invaild" 2 "regen control" 1 "Drive control" 0 "Zero control";
VAL_ 504 EDS_Work_STS_FR 15 "invaild" 14 "power off" 13 "Failure" 12 "after run" 11 "shut down" 5 "HVReady" 4 "normal" 3 "precharge" 2 "standby" 1 "init" 0 "default";
VAL_ 504 EDS_powoff_req_FR 1 "(Request high voltage power down)" 0 "(No request)";
VAL_ 1080 EDS_FailGrade_ERR_FWD 7 "Invaild" 6 "Invaild" 5 "Fifth Fault,Delayed power off" 4 "Forth Fault,ZeroTorque" 3 "Third Fault,Limp" 2 "Second Fault，Limited power" 1 "First-Level warning" 0 "No fault";
VAL_ 1080 EDS_MotOverTempAlarm_FWD 1 "Error" 0 "Normal";
VAL_ 1080 EDS_MotOverTempFault_FWD 1 "Error" 0 "Normal";
VAL_ 1080 EDS_MotTempSenFault_FWD 1 "Error" 0 "Normal";
VAL_ 1080 EDS_EDSOverTempUFault_FWD 1 "Error" 0 "Normal";
VAL_ 1080 EDS_EDSOverTempVFault_FWD 1 "Error" 0 "Normal";
VAL_ 1080 EDS_EDSOverTempWFault_FWD 1 "Error" 0 "Normal";
VAL_ 1080 EDS_EDSOverTempAlarm_FWD 1 "Error" 0 "Normal";
VAL_ 1080 EDS_TCoolantOvHi_FWD 1 "Error" 0 "Normal";
VAL_ 1080 EDS_EDSTempCmpAlarm_FWD 1 "Error" 0 "Normal";
VAL_ 1080 EDS_EDSPhaOvCurentHWFault_FWD 1 "Error" 0 "Normal";
VAL_ 1080 EDS_EDSphaOffCalFault_FWD 1 "Error" 0 "Normal";
VAL_ 1080 EDS_EDSOverIdcLnkAlarm_FWD 1 "Error" 0 "Normal";
VAL_ 1080 EDS_EDSHVOverVoltageAlarm_FWD 1 "Error" 0 "Normal";
VAL_ 1080 EDS_EDSHVOverVoltageFault_FWD 1 "Error" 0 "Normal";
VAL_ 1080 EDS_EDSHVUnderVoltageAlarm_FWD 1 "Error" 0 "Normal";
VAL_ 1080 EDS_EDSHVUnderVoltageFault_FWD 1 "Error" 0 "Normal";
VAL_ 1080 EDS_RunToDischaErr_FWD 1 "Error" 0 "Normal";
VAL_ 1080 EDS_12VOverVoltageAlarm_FWD 1 "Error" 0 "Normal";
VAL_ 1080 EDS_12VUnderVoltageAlarm_FWD 1 "Error" 0 "Normal";
VAL_ 1080 EDS_MotOverAlarm_FWD 1 "Error" 0 "Normal";
VAL_ 1080 EDS_MotOverFault_FWD 1 "Error" 0 "Normal";
VAL_ 1080 EDS_iDcLnkOvCLimFail_FWD 1 "Error" 0 "Normal";
VAL_ 1080 EDS_MotBlockedFault_FWD 1 "Error" 0 "Normal";
VAL_ 1080 EDS_RSLErr_FWD 1 "Error" 0 "Normal";
VAL_ 1080 EDS_MotTrqLimFault_FWD 1 "Error" 0 "Normal";
VAL_ 1080 EDS_ResolverOffsetAngle_FWD 1 "Error" 0 "Normal";
VAL_ 1080 EDS_EDSDisChgFault_FWD 1 "Error" 0 "Normal";
VAL_ 1080 EDS_IGBTFault_FWD 1 "Error" 0 "Normal";
VAL_ 1080 EDS_CANBusoffFault_FWD 1 "Error" 0 "Normal";
VAL_ 1080 EDS_TDrvBoardOvHiWarn_FWD 1 "Error" 0 "Normal";
VAL_ 1080 EDS_TIGBTOvHiFault_FWD 1 "Error" 0 "Normal";
VAL_ 1080 EDS_TIGBTOvHiWarn_FWD 1 "Error" 0 "Normal";
VAL_ 1080 EDS_IOHWABSampFail_FWD 1 "Error" 0 "Normal";
VAL_ 1080 EDS_EDSOpenFault_FWD 1 "Error" 0 "Normal";
VAL_ 1080 EDS_MotorOpenFault_FWD 1 "Error" 0 "Normal";
VAL_ 1080 EDS_EmacBlkdWarn_FWD 1 "Error" 0 "Normal";
VAL_ 1080 EDS_VerMatchFailureErr_FWD 1 "Error" 0 "Normal";
VAL_ 1080 EDS_DiashCirNoPsblErr_FWD 1 "Error" 0 "Normal";
VAL_ 1080 EDS_OperOutdRngErr_FWD 1 "Error" 0 "Normal";
VAL_ 1080 EDS_PhaseLossFaultErr_FWD 1 "Error" 0 "Normal";
VAL_ 1080 EDS_CPLDFault_FWD 1 "Error" 0 "Normal";
VAL_ 1080 EDS_CPLDFaultBaseSpd_FWD 1 "Error" 0 "Normal";
VAL_ 1080 EDS_IOHWABNen33Fail_FWD 1 "Error" 0 "Normal";
VAL_ 1080 EDS_HvMcuSlightFault_RWD 1 "Error" 0 "Normal";
VAL_ 1080 EDS_HvMcuSevFault_FWD 1 "Error" 0 "Normal";
VAL_ 1080 EDS_EDSPhaSampHWFault_FWD 1 "Error" 0 "Normal";
VAL_ 1080 EDS_IsOvHiErr_FWD 1 "Error" 0 "Normal";
VAL_ 1080 EDS_CanRollingCounterErr_FWD 1 "Error" 0 "Normal";
VAL_ 1080 EDS_CanTimeoutErr_FWD 1 "Error" 0 "Normal";
VAL_ 1080 EDS_CrashFault_FWD 1 "Error" 0 "Normal";
VAL_ 537 Rolling_Counter_0x219 15 "Invalid";
VAL_ 537 VCU_ChargeAllow 1 "Allow " 0 "Not allow";
VAL_ 544 Rolling_Counter_0x220 15 "Invalid";
VAL_ 544 VCU_BMS_PTCOnOff_Sts 1 "on " 0 "off";
VAL_ 544 VCU_BMS_ValveOnOff_Sts 1 "open " 0 "close";
VAL_ 544 VCU_BMS_PumpFB 3 "Reserve" 2 "Fault" 1 "ON" 0 "OFF";
VAL_ 757 VCU_Charge_Control 2 "Forbid" 1 "Allowed" 0 "Default";
VAL_ 757 VCU_AC_chargeSock_temp1 2047 "Invaild";
VAL_ 757 VCU_DC_chargeSock_temp1 2047 "Invaild";
VAL_ 757 VCU_DC_chargeSock_temp2 2047 "Invaild";
VAL_ 937 VCU_PTC_RelaySts 1 "close" 0 "open";
VAL_ 937 VCU_EACEnbReq 1 "Enable" 0 "Disable";
VAL_ 937 VCU_EACAllowedPower 1023 "Invalid";
VAL_ 937 VCU_EAC_CompSpdReq 16383 "Invaild";
VAL_ 425 VCU_RegenLevel_Feed 3 "invalid" 2 "High" 1 "Low" 0 "none";
VAL_ 425 VCU_RBCSts 1 "active" 0 "incative";
VAL_ 425 VCU_RDCSts 1 "active" 0 "incative";
VAL_ 425 VCU_Veh_ERR 1 "Error" 0 "Normal";
VAL_ 425 VCU_DrvSys_ERR 1 "Error" 0 "Normal";
VAL_ 425 VCU_PackSys_ERR 1 "Error" 0 "Normal";
VAL_ 425 VCU_TBOX_Veh_STS_Reserved 3 "Other" 2 "Off" 1 "Start" 0 "Invalid";
VAL_ 425 VCU_VehChg_STS 3 "Charge fault" 2 "Charging complete" 1 "Charging in progress" 0 "Charging not in progress";
VAL_ 425 VCU_BatterVoltage_Reserved 255 "Invalid";
VAL_ 425 VCU_BatteryVoltErr_Reserved 1 "warning" 0 "no warning";
VAL_ 425 VCU_MotorCoolingCircuitErr_Reserved 1 "Error" 0 "Normal";
VAL_ 425 VCU_PackCoolingCircuitErr_Reserved 1 "Error" 0 "Normal";
VAL_ 425 VCU_VehicleHVStatus 3 "Reserved" 2 "ReadyToDrive" 1 "HV On" 0 "Not ready";
VAL_ 425 VCU_InstantPowerConsump 1023 "Invalid";
VAL_ 425 VCU_AveragePowerConsump 1023 "Invalid";
VAL_ 425 VCU_BrakePedalSts 3 "Invalid" 2 "Reserved" 1 "pressed" 0 "Not pressed";
VAL_ 992 Rolling_Counter_0x3E0 15 "Invalid";
VAL_ 992 VCU_MHU_Ack_ChgSche_stt 0 "Disabled" 1 "Enabled" 2 "Reserved" 3 "Invalid";
VAL_ 992 VCU_MHU_GuestMode_sts 0 "OFF" 1 "ON" 2 "Reserved" 3 "Reserved";
VAL_ 992 VCU_ValetMode_sts 0 "Inactive" 1 "Active" 255 "Invalid";
VAL_ 992 VCU_CreepDisable_stt 0 "Enable" 1"Disable";
VAL_ 409 Rolling_Counter_0x199 15 "Invalid";
VAL_ 409 VCU_VehFailGrade_ERR 5 "Level5" 4 "Level4" 3 "Level3" 2 "Level2" 1 "Level1" 0 "Normal";
VAL_ 409 VCU_BMS_HVOnOff_REQ 1 "allow" 0 "forbid";
VAL_ 409 VCU_Vehicle_Mode 9 "Reserved " 8 "Emer Driving Mode " 7 "Reserved" 6 "Charging Mode " 5 "HV-Termination Mode " 4 "Driving Mode " 3 "HV-Activation Mode" 2 "Vehicle Reset Mode " 1 "StandBy IG OFF Mode " 0 "Reserved";
VAL_ 792 EAC_CompElecCurrV 0 "Valid" 1 "Invalid";
VAL_ 792 EAC_CompStat 0 "Normal Operation" 1 "Degraded Operation" 2 "Inoperative" 15 "Invalid";
VAL_ 792 EAC_CompElecPwrV 0 "Valid" 1 "Invalid";
VAL_ 792 EAC_CompSpdIncrReq 0 "False" 1 "True";
VAL_ 792 EAC_CompSpdV 0 "Valid" 1 "Invalid";
VAL_ 792 EAC_CompElecPwr 255 "Invaild";
VAL_ 792 EAC_CompSpd 16383 "Invaild";
VAL_ 792 EAC_CompElecCurr 255 "Invaild";
VAL_ 792 EAC_CompFltStat 0 "No Fault" 1 "Under Voltage" 2 "Over Voltage" 3 "Over Temperature" 4 "Input Control" 5 "Current Fault" 6 "Internal Fault" 8 "Motor slip protection" 9 "HVDC input voltage drop protection" 10 "Inside the controller 15V control power supply output undervoltage protection" 11 "Overcurrent frequency limitation and frequency reduction" 15 "Invalid";
VAL_ 524 Rolling_Counter_0x20C 15 "Invalid";
VAL_ 524 IPC_ODO 1048575 "Invalid";
VAL_ 703 IPC_TripA 65535 "Invalid";
VAL_ 703 IPC_AverageSpeedTripA 4095 "Invalid";
VAL_ 703 IPC_AverageConsumptionTripA 1023 "Invalid";
VAL_ 703 IPC_ParkBrakeSts 3 "Invalid" 2 "Reserved" 1 "Applied" 0 "Released";
VAL_ 703 IPC_VehSpd 32767 "Invalid";
VAL_ 1087 IPC_Sec 63 "Invalid";
VAL_ 1087 IPC_Min 63 "Invalid";
VAL_ 1087 IPC_Hour 31 "Invalid";
VAL_ 1087 IPC_Day 31 "Invalid";
VAL_ 1087 IPC_Month 15 "Invalid";
VAL_ 1087 IPC_Year 255 "Invalid";
VAL_ 1087 IPC_SelfCheckStatus 1 "self-check finish" 0 "self-checking";
VAL_ 1074 Rolling_Counter_0x432 15 "Invalid";
VAL_ 1074 MHU_FOTA_State 0 "INIT" 1 "NORMAL" 2 "FOTA FLASHING" 3 "FOTA-SUSPENDED" 4 "FAIL-SAFE-ERROR" 5 "SHUTDOWN" 6 "REMOTE DIAGNOSTICS" 7 "Invalid";
VAL_ 1027 Rolling_Counter_0x403 15 "Invalid";
VAL_ 1027 MHU_SET_TCS_OnOff 0 "OFF (keep sending for 2 seconds)" 1 "ON (keep sending for 2 seconds)" 2 "No action" 3 "Invalid";
VAL_ 1027 MHU_SET_DrivingModeSwitch 3 "sport mode (should be hold during 1 second)" 2 "normal mode (should be hold during 1 second)" 1 "eco mode (should be hold during 1 second)" 0 "no change request";
VAL_ 1027 MHU_SET_RegenLevel 3 "No action" 2 "High" 1 "Low" 0 "none";
VAL_ 1027 MHU_VCU_CreepDisable_stt 0 "No request" 1 "Creep Disable request" 2 "Reserved" 3 "Invalid";
VAL_ 1027 MHU_HVACTurnON 0 "No request" 1 "ON" 2 "Reserved" 3 "Invalid";
VAL_ 1027 MHU_ChargeScheduleSet 0 "Disabled" 1 "Enabled" 2 "No Action" 3 "Reserved";
VAL_ 1027 MHU_ChargingRequest 0 "Reserved" 1 "Request scheduled start charging" 2 "Request stop" 3 "No effect";
VAL_ 1027 MHU_ValetMode_Activation 0 "Inactive" 1 "Active" 254 "Reserved" 255 "Invalid";
VAL_ 811 CCU_TemperatureGearSts 63 "Invalid" 16 "level 8" 15 "level 7" 14 "level 6" 13 "level 5" 12 "level 4" 11 "level 3" 10 "level 2" 9 "level 1" 8 "level 8" 7 "level 7" 6 "level 6" 5 "level 5" 4 "level 4" 3 "level 3" 2 "level 2" 1 "level 1" 0 "Inactive";
VAL_ 811 CCU_BlowMode_Sts 7 "Invalid" 6 "Reserve" 4 "Foot and window" 3 "Foot" 2 "Foot and Face" 1 "Face" 0 "OFF";
VAL_ 811 CCU_Circulation_Sts 1 "Internal circulation" 0 "Outer circulation";
VAL_ 811 CCU_AC_Req 3 "Invalid" 2 "Reserved" 1 "Requset" 0 "No requset";
VAL_ 811 CCU_AC_Sts 1 "ON" 0 "OFF";
VAL_ 811 CCU_BlowerLevelSts 8 "level 8" 7 "level 7" 6 "level 6" 5 "level 5" 4 "level 4" 3 "level 3" 2 "level 2" 1 "level 1" 0 "OFF";
VAL_ 811 CCU_FrontDefrostSts 1 "On" 0 "Off";
VAL_ 811 CCU_PTC_Req 3 "Invalid" 2 "Reserved" 1 "Requset" 0 "No requset";
VAL_ 811 CCU_PTC_Temperature 1023 "Invaild";
VAL_ 811 CCU_CompSpdMEAS_Comp 8191 "Invalid";
VAL_ 811 CCU_PollutionSts 1 "ON" 0 "OFF";
VAL_ 811 CCU_ExternalTemperature 255 "Invaild";
VAL_ 811 CCU_evaporator_Temperature 31 "Invalid";
VAL_ 811 CCU_ExternalTemperatureFailSts 1 "invalid" 0 "valid";
VAL_ 274 Rolling_Counter_0x112 15 "Invalid";
VAL_ 274 STAT_Terminal 7 "Signal invalid" 6 "Reserved" 5 "Reserved" 4 "SW update OTA (Not used in VFe34)" 3 "Engine start (eMotor running)" 2 "ON (Driver Present)" 1 "ACC (Park)" 0 "OFF(Comfort Enable)";
VAL_ 274 STAT_CL30s_L_Reserved 3 "Signal invalid" 2 "Failure" 1 "ON" 0 "OFF";
VAL_ 266 Rolling_Counter_0x10a 15 "Invalid";
VAL_ 266 BCM_LVTop_up 1 "start Top up" 0 "stop Top up";
VAL_ 133 Rolling_Counter_0x85 15 "Invalid";
VAL_ 133 ACM_Crash_Sts 3 "Invalid Value" 2 "Invalid Value" 1 "Crash_Detected" 0 "No_Event";
VAL_ 133 ACM_Airbag_Deployment_Status 3 "Invalid Value" 2 "Invalid Value" 1 "Airbag_Deployment" 0 "No_Airbag_Deployment";
VAL_ 133 ACM_Crash_Intensity 7 "Invalid_Value" 6 "Invalid_Value" 5 "Invalid_Value" 4 "Invalid_Value" 3 "Crash_Intensity_3" 2 "Crash_Intensity_2" 1 "Crash_Intensity_1" 0 "No_Crash";
VAL_ 133 ACM_Front_Crash 3 "Invalid Value" 2 "Invalid Value" 1 "Front_Crash_Detected" 0 "No_Event";
VAL_ 133 ACM_DriverSide_Crash 3 "Invalid Value" 2 "Invalid Value" 1 "Driverside_Crash_Detected" 0 "No_Event";
VAL_ 133 ACM_PassSide_Crash 3 "Invalid Value" 2 "Invalid Value" 1 "PassSide_Crash_Detected" 0 "No_Event";
VAL_ 133 ACM_Rear_Crash 3 "Invalid Value" 2 "Invalid Value" 1 "Rear_Crash_Detected" 0 "No_Event";
VAL_ 133 ACM_Rollover_Crash 3 "Invalid Value" 2 "Invalid Value" 1 "Rollover_Crash_Detected" 0 "No_Event";
VAL_ 834 Rolling_Counter_0x342 15 "Invalid";
VAL_ 834 ABS_LRWhlSpdRaw 32767 "Invalid";
VAL_ 834 ABS_LRWhlSpdRawValid 1 "Valid" 0 "Invalid";
VAL_ 834 ABS_RRWhlSpdRaw 32767 "Invalid";
VAL_ 834 ABS_RRWhlSpdRawValid 1 "Valid" 0 "Invalid";
VAL_ 834 ABS_VehSpd 32767 "Invalid";
VAL_ 834 ABS_VehSpdValid 1 "Valid" 0 "Invalid";
